VERSION ""

NS_ :

BS_:

BU_: BCM DMS NAB NDG NQS NVO SGW

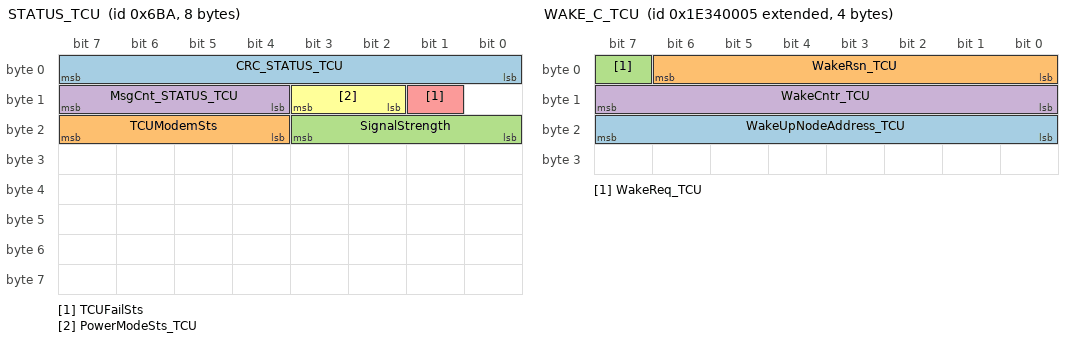
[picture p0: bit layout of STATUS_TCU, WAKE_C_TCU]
BO_ 1722 STATUS_TCU: 8 SGW
 SG_ CRC_STATUS_TCU : 7|8@0+ (1,0) [0|255] "" Vector__XXX
 SG_ TCUModemSts : 23|4@0+ (1,0) [0|15] "" Vector__XXX
 SG_ SignalStrength : 19|4@0+ (1,0) [0|15] "" Vector__XXX
 SG_ MsgCnt_STATUS_TCU : 15|4@0+ (1,0) [0|14] "" Vector__XXX
 SG_ TCUFailSts : 9|1@0+ (1,0) [0|1] "" Vector__XXX
 SG_ PowerModeSts_TCU : 11|2@0+ (1,0) [0|3] ""  BCM

BO_ 2654208005 WAKE_C_TCU: 4 SGW
 SG_ WakeUpNodeAddress_TCU : 23|8@0+ (1,0) [0|255] ""  BCM
 SG_ WakeRsn_TCU : 6|7@0+ (1,0) [0|127] ""  BCM
 SG_ WakeReq_TCU : 7|1@0+ (1,0) [0|1] ""  BCM
 SG_ WakeCntr_TCU : 15|8@0+ (1,0) [0|255] ""  BCM

BO_ 1212 COMMAND_SGW_TO_NBC: 8 SGW
 SG_ TCU_Replacement_Warning : 23|1@0+ (1,0) [0|1] ""  BCM

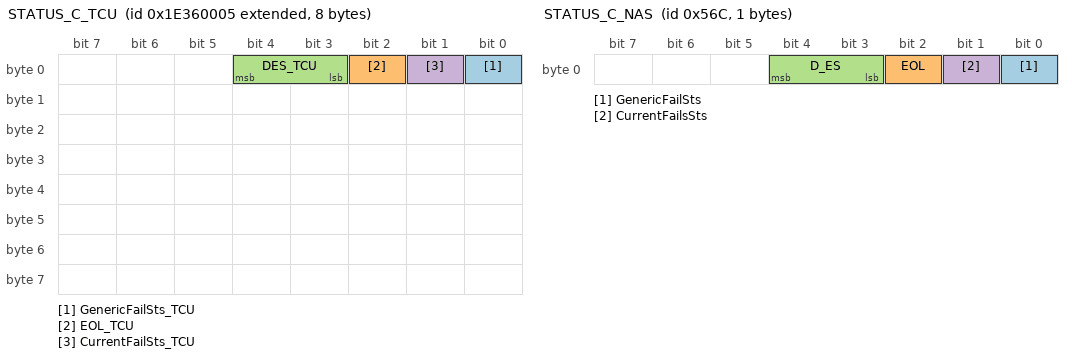
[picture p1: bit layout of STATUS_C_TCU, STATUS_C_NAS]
BO_ 2654339077 STATUS_C_TCU: 8 SGW
 SG_ GenericFailSts_TCU : 0|1@0+ (1,0) [0|1] ""  BCM
 SG_ EOL_TCU : 2|1@0+ (1,0) [0|1] ""  BCM
 SG_ DES_TCU : 4|2@0+ (1,0) [0|3] ""  BCM
 SG_ CurrentFailSts_TCU : 1|1@0+ (1,0) [0|1] ""  BCM

BO_ 2564453105 UDS_DIAG_REQ_ELR: 8 SGW
 SG_ TPDU_DREQ_ELR : 7|64@0+ (1,0) [0|1.84467440737096E+019] ""  BCM

BO_ 2564453361 UDS_DIAG_REQ_ELL: 8 SGW
 SG_ TPDU_DREQ_ELL : 7|64@0+ (1,0) [0|1.84467440737096E+019] ""  BCM

BO_ 204 LWS_STEERING_ANGLE_SENSOR: 6 SGW
 SG_ LWS_OK : 8|1@0+ (1,0) [0|1] ""  BCM
 SG_ LWS_Angle : 31|16@0- (0.1,0) [-780|780] "°"  BCM,NDG

BO_ 1388 STATUS_C_NAS: 1 SGW
 SG_ GenericFailSts : 0|1@0+ (1,0) [0|1] ""  BCM
 SG_ EOL : 2|1@0+ (1,0) [0|1] ""  BCM
 SG_ D_ES : 4|2@0+ (1,0) [0|3] ""  BCM
 SG_ CurrentFailsSts : 1|1@0+ (1,0) [0|1] ""  BCM

BO_ 1530 STATUS_C_LCU: 8 SGW
 SG_ Right_TI_Feedback_C_LCU : 27|1@0+ (1,0) [0|1] ""  BCM
 SG_ Right_TI_FailSts_C_LCU : 25|1@0+ (1,0) [0|1] ""  BCM
 SG_ Right_PL_Feedback_C_LCU : 14|1@0+ (1,0) [0|1] ""  BCM,NQS
 SG_ Right_LB_Feedback_C_LCU : 23|1@0+ (1,0) [0|1] ""  BCM
 SG_ Right_HB_Feedback_C_LCU : 31|1@0+ (1,0) [0|1] ""  BCM
 SG_ Right_DRL_Feedback_C_LCU : 12|1@0+ (1,0) [0|1] ""  BCM,NQS
 SG_ ParkingLight_Feedback_C_LCU : 38|1@0+ (1,0) [0|1] ""  BCM
 SG_ MsgCounter_LCUSts : 51|4@0+ (1,0) [0|15] ""  BCM,NQS
 SG_ Left_TI_Feedback_C_LCU : 28|1@0+ (1,0) [0|1] ""  BCM
 SG_ Left_TI_FailSts_C_LCU : 26|1@0+ (1,0) [0|1] ""  BCM
 SG_ Left_PL_Feedback_C_LCU : 15|1@0+ (1,0) [0|1] ""  BCM,NQS
 SG_ Left_LB_Feedback_C_LCU : 8|1@0+ (1,0) [0|1] ""  BCM
 SG_ Left_HB_Feedback_C_LCU : 16|1@0+ (1,0) [0|1] ""  BCM
 SG_ Left_DRL_Feedback_C_LCU : 13|1@0+ (1,0) [0|1] ""  BCM,NQS
 SG_ GenericFailSts_C_LCU : 0|1@0+ (1,0) [0|1] ""  BCM
 SG_ EOL_C_LCU : 2|1@0+ (1,0) [0|1] ""  BCM
 SG_ D_ES_C_LCU : 4|2@0+ (1,0) [0|3] ""  BCM
 SG_ CurrentFailsSts_C_LCU : 1|1@0+ (1,0) [0|1] ""  BCM
 SG_ Checksum_LCUSts : 63|8@0+ (1,0) [0|255] ""  BCM,NQS

BO_ 2564485490 UDS_DIAG_RES_ELR: 8 BCM
 SG_ TPDU_DRES_ELR : 7|64@0+ (1,0) [0|1.84467440737096E+019] ""  SGW

BO_ 2564485491 UDS_DIAG_RES_ELL: 8 BCM
 SG_ TPDU_DRES_ELL : 7|64@0+ (1,0) [0|1.84467440737096E+019] ""  SGW

BO_ 2041 DIAGNOSTIC_RESPONSE_BCM_MTP_TST: 8 BCM
 SG_ N_PDU_MTP_TST_RESP : 7|64@0+ (1,0) [0|0] ""  SGW

BO_ 2040 DIAGNOSTIC_RESPONSE_BCM_MTP: 8 BCM
 SG_ N_PDU_MTP_RESP : 7|64@0+ (1,0) [0|0] ""  SGW

BO_ 2033 DIAGNOSTIC_REQUEST_BCM_MTP_TST: 8 SGW
 SG_ N_PDU_MTP_TST_REQ : 7|64@0+ (1,0) [0|0] ""  BCM

BO_ 2032 DIAGNOSTIC_REQUEST_BCM_MTP: 8 SGW
 SG_ N_PDU_MTP_REQ : 7|64@0+ (1,0) [0|0] ""  BCM

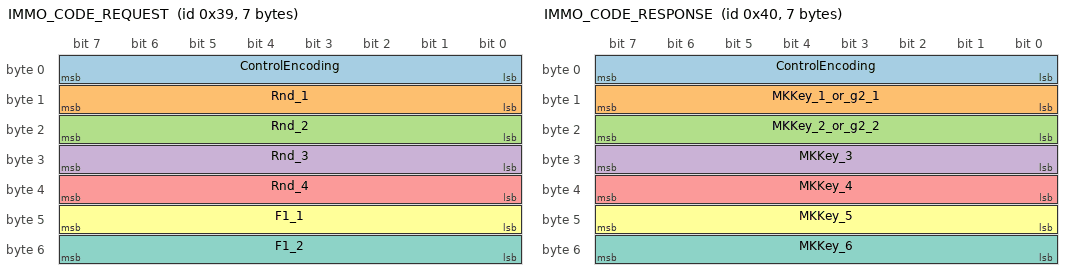
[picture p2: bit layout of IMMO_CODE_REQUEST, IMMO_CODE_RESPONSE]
BO_ 57 IMMO_CODE_REQUEST: 7 SGW
 SG_ ControlEncoding : 7|8@0+ (1,0) [0|255] ""  BCM
 SG_ Rnd_1 : 15|8@0+ (1,0) [0|255] ""  BCM
 SG_ Rnd_2 : 23|8@0+ (1,0) [0|255] ""  BCM
 SG_ Rnd_3 : 31|8@0+ (1,0) [0|255] ""  BCM
 SG_ Rnd_4 : 39|8@0+ (1,0) [0|255] ""  BCM
 SG_ F1_1 : 47|8@0+ (1,0) [0|255] ""  BCM
 SG_ F1_2 : 55|8@0+ (1,0) [0|255] ""  BCM

BO_ 64 IMMO_CODE_RESPONSE: 7 BCM
 SG_ ControlEncoding : 7|8@0+ (1,0) [0|255] ""  SGW
 SG_ MKKey_1_or_g2_1 : 15|8@0+ (1,0) [0|255] ""  SGW
 SG_ MKKey_2_or_g2_2 : 23|8@0+ (1,0) [0|255] ""  SGW
 SG_ MKKey_3 : 31|8@0+ (1,0) [0|255] ""  SGW
 SG_ MKKey_4 : 39|8@0+ (1,0) [0|255] ""  SGW
 SG_ MKKey_5 : 47|8@0+ (1,0) [0|255] ""  SGW
 SG_ MKKey_6 : 55|8@0+ (1,0) [0|255] ""  SGW

BO_ 70 C1_ASR0: 8 SGW
 SG_ ABSSts : 3|3@0+ (1,0) [0|7] ""  BCM,NAB
 SG_ BrkRecSts : 6|3@0+ (1,0) [0|7] "0" Vector__XXX
 SG_ HDCSts : 10|3@0+ (1,0) [0|7] ""  NQS,NVO
 SG_ EBDSts : 15|3@0+ (1,0) [0|7] "" Vector__XXX
 SG_ ACC_Engine_Torque_Enabled_NFR : 16|1@0+ (1,0) [0|1] "" Vector__XXX
 SG_ TrqIncrease_Enabler_TCS : 17|1@0+ (1,0) [0|1] "" Vector__XXX
 SG_ AVHSts : 20|3@0+ (1,0) [0|7] "" Vector__XXX
 SG_ CDPSts : 23|3@0+ (1,0) [0|7] "" Vector__XXX
 SG_ FrontCtrlSts : 25|3@0+ (1,0) [0|7] "" Vector__XXX
 SG_ RearCtrlSts : 28|3@0+ (1,0) [0|7] "" Vector__XXX
 SG_ CommandedSilenceRequest : 29|1@0+ (1,0) [0|1] "" Vector__XXX
 SG_ ACCEngaged : 30|1@0+ (1,0) [0|1] "" Vector__XXX
 SG_ DsblFuelShutOff_ACC_NFR : 31|1@0+ (1,0) [0|1] "" Vector__XXX
 SG_ HDC_TargetSpeed : 38|7@0+ (1,0) [0|120] ""  NQS
 SG_ ACC_TorqueRequest_NFR : 47|12@0+ (8,-8000) [-8000|24760] "Nm" Vector__XXX
 SG_ MessageCounterP_ASR0 : 51|4@0+ (1,0) [0|15] "" Vector__XXX
 SG_ ChecksumP_ASR0 : 63|8@0+ (1,0) [0|255] "" Vector__XXX

BO_ 76 NCR_INFO: 8 SGW
 SG_ GearEngagedForADAS : 7|4@0+ (1,0) [0|15] ""  DMS
 SG_ ActiveGearRatio : 9|10@0+ (0.025,0) [0|25.575] "" Vector__XXX
 SG_ NCRACCFailSts : 10|1@0+ (1,0) [0|1] "" Vector__XXX
 SG_ ActiveGearRatioValidData : 11|1@0+ (1,0) [0|1] "" Vector__XXX
 SG_ GearBoxAutomaticMode : 12|1@0+ (1,0) [0|1] "" Vector__XXX
 SG_ DrivingCycle : 13|1@0+ (1,0) [0|1] "" Vector__XXX
 SG_ WarmingUpCycle : 14|1@0+ (1,0) [0|1] "" Vector__XXX
 SG_ GearEngaged : 27|4@0+ (1,0) [0|15] ""  BCM
 SG_ FutureSyncGear : 31|4@0+ (1,0) [0|15] "" Vector__XXX
 SG_ AMTIndex : 38|7@0+ (1,0) [0|100] "" Vector__XXX
 SG_ ShiftInProgress : 39|1@0+ (1,0) [0|1] "" Vector__XXX
 SG_ DCTState : 45|6@0+ (1,0) [0|63] "" Vector__XXX
 SG_ EngineSlaveMode : 46|1@0+ (1,0) [0|1] "" Vector__XXX
 SG_ RaceStart : 47|1@0+ (1,0) [0|1] "" Vector__XXX
 SG_ MessageCounterP_NCR_INFO : 51|4@0+ (1,0) [0|15] ""  DMS
 SG_ TorquePhaseTime : 55|4@0+ (50,0) [0|750] "msec" Vector__XXX
 SG_ ChecksumP_NCR_INFO : 63|8@0+ (1,0) [0|255] ""  DMS

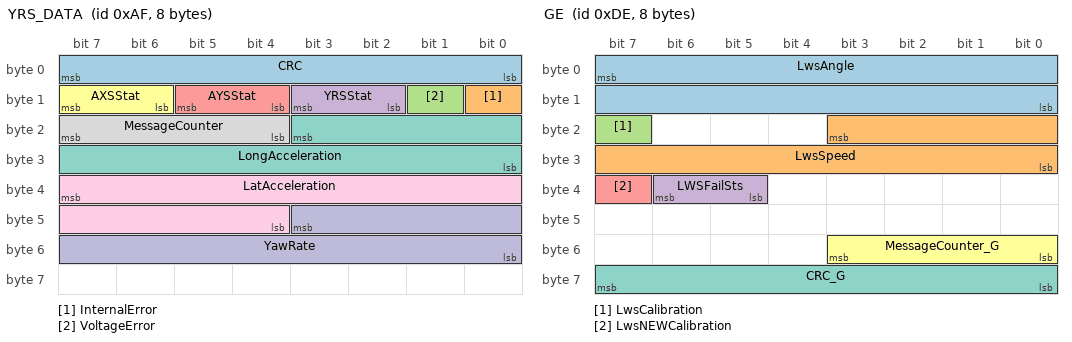
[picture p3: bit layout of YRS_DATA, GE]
BO_ 175 YRS_DATA: 8 SGW
 SG_ CRC : 7|8@0+ (1,0) [0|255] ""  BCM,NAB
 SG_ InternalError : 8|1@0+ (1,0) [0|1] "" Vector__XXX
 SG_ VoltageError : 9|1@0+ (1,0) [0|1] "" Vector__XXX
 SG_ YRSStat : 11|2@0+ (1,0) [0|3] ""  BCM
 SG_ AYSStat : 13|2@0+ (1,0) [0|3] ""  BCM,NQS
 SG_ AXSStat : 15|2@0+ (1,0) [0|3] ""  BCM,NQS
 SG_ LongAcceleration : 19|12@0+ (0.02,-40.96) [-40.96|40.92] "m/s²"  BCM,NDG,NQS
 SG_ MessageCounter : 23|4@0+ (1,0) [0|15] ""  BCM,NAB
 SG_ LatAcceleration : 39|12@0+ (0.02,-40.96) [-40.96|40.92] "m/s²"  BCM,NDG,NQS
 SG_ YawRate : 43|12@0+ (0.08,-163.84) [-163.84|163.68] "°/s"  BCM,NAB,NDG

BO_ 222 GE: 8 SGW
 SG_ LwsAngle : 7|16@0+ (0.1,-720) [-720|720] "°"  BCM,NAB,NDG
 SG_ LwsSpeed : 19|12@0+ (1,-2000) [-2000|2094] "°/S" Vector__XXX
 SG_ LwsCalibration : 23|1@0+ (1,0) [0|1] ""  BCM
 SG_ LWSFailSts : 38|2@0+ (1,0) [0|3] ""  BCM,NAB,NQS
 SG_ LwsNEWCalibration : 39|1@0+ (1,0) [0|1] "" Vector__XXX
 SG_ MessageCounter_G : 51|4@0+ (1,0) [0|15] "" Vector__XXX
 SG_ CRC_G : 63|8@0+ (1,0) [0|255] "" Vector__XXX

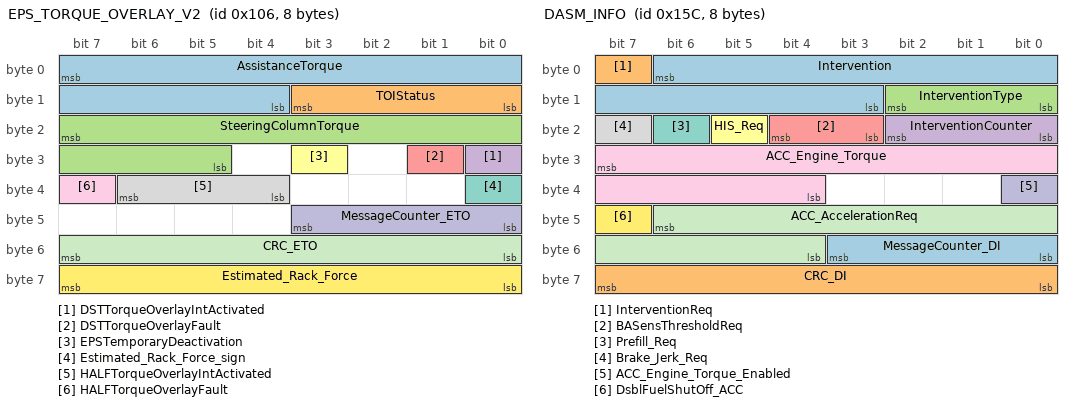
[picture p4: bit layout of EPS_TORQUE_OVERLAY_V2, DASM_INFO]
BO_ 262 EPS_TORQUE_OVERLAY_V2: 8 SGW
 SG_ AssistanceTorque : 7|12@0+ (0.05,-100) [-100|104.75] "Nm" Vector__XXX
 SG_ TOIStatus : 11|4@0+ (1,0) [0|15] "" Vector__XXX
 SG_ SteeringColumnTorque : 23|11@0+ (0.0078125,-8) [-8|7.984375] "Nm" Vector__XXX
 SG_ DSTTorqueOverlayIntActivated : 24|1@0+ (1,0) [0|1] "" Vector__XXX
 SG_ DSTTorqueOverlayFault : 25|1@0+ (1,0) [0|1] "" Vector__XXX
 SG_ EPSTemporaryDeactivation : 27|1@0+ (1,0) [0|1] "" Vector__XXX
 SG_ Estimated_Rack_Force_sign : 32|1@0+ (1,0) [0|1] "" Vector__XXX
 SG_ HALFTorqueOverlayIntActivated : 38|3@0+ (1,0) [0|7] ""  NAB
 SG_ HALFTorqueOverlayFault : 39|1@0+ (1,0) [0|1] ""  NAB
 SG_ MessageCounter_ETO : 43|4@0+ (1,0) [0|15] "" Vector__XXX
 SG_ CRC_ETO : 55|8@0+ (1,0) [0|255] "" Vector__XXX
 SG_ Estimated_Rack_Force : 63|8@0+ (80,0) [0|20400] "N" Vector__XXX

BO_ 326 BRAKE_FE3: 8 BCM
 SG_ Slope : 0|7@0+ (1,-61) [-61|61] "%" Vector__XXX
 SG_ EPBMalfunction : 1|1@0+ (1,0) [0|1] "" Vector__XXX
 SG_ SlopeValidData : 2|1@0+ (1,0) [0|1] "" Vector__XXX
 SG_ Function2Sts : 3|1@0+ (1,0) [0|1] "" Vector__XXX
 SG_ FunctionSts : 4|1@0+ (1,0) [0|1] "" Vector__XXX
 SG_ EPBSts : 7|3@0+ (1,0) [0|7] "" Vector__XXX
 SG_ EPB_ButtonSts : 9|2@0+ (1,0) [0|3] "" Vector__XXX
 SG_ VehicleSpeedVSOSig : 22|13@0+ (0.0625,0) [0|511.9375] "km/h" Vector__XXX
 SG_ AutoDriveOffFailSts : 23|1@0+ (1,0) [0|1] "" Vector__XXX
 SG_ VehicleSpeedVSOSigFailSts : 25|1@0+ (1,0) [0|1] "" Vector__XXX
 SG_ NFR_Speed_FA : 38|13@0+ (0.0625,0) [0|511.9375] "km/h" Vector__XXX
 SG_ ESCOFF_Mode : 39|1@0+ (1,0) [0|1] "" Vector__XXX
 SG_ ABSFailPresent : 40|1@0+ (1,0) [0|1] "" Vector__XXX
 SG_ NFR_Speed_FA_FailSts : 41|1@0+ (1,0) [0|1] "" Vector__XXX
 SG_ MsgCounter : 51|4@0+ (1,0) [0|15] "" Vector__XXX
 SG_ NFRAutoStopFailSts : 52|1@0+ (1,0) [0|1] "" Vector__XXX
 SG_ NFRAutoStopStaySts : 53|1@0+ (1,0) [0|1] "" Vector__XXX
 SG_ NFRAutoStopEnableSts : 54|1@0+ (1,0) [0|1] "" Vector__XXX
 SG_ NFRCruiseEnabler : 55|1@0+ (1,0) [0|1] "" Vector__XXX
 SG_ Checksum : 63|8@0+ (1,0) [0|255] "" Vector__XXX

BO_ 348 DASM_INFO: 8 SGW
 SG_ Intervention : 6|12@0+ (0.01,-16) [-16|4.46] "m/s2" Vector__XXX
 SG_ InterventionReq : 7|1@0+ (1,0) [0|1] ""  NAB,NQS
 SG_ InterventionType : 10|3@0+ (1,0) [0|7] "" Vector__XXX
 SG_ InterventionCounter : 18|3@0+ (1,0) [0|7] "" Vector__XXX
 SG_ BASensThresholdReq : 20|2@0+ (1,0) [0|3] "" Vector__XXX
 SG_ HIS_Req : 21|1@0+ (1,0) [0|1] "" Vector__XXX
 SG_ Prefill_Req : 22|1@0+ (1,0) [0|1] "" Vector__XXX
 SG_ Brake_Jerk_Req : 23|1@0+ (1,0) [0|1] "" Vector__XXX
 SG_ ACC_Engine_Torque : 31|12@0+ (8,-8000) [-8000|24760] "Nm"  NQS
 SG_ ACC_Engine_Torque_Enabled : 32|1@0+ (1,0) [0|1] ""  NQS
 SG_ ACC_AccelerationReq : 46|11@0+ (0.01,-16) [-16|4.46] "m/s2" Vector__XXX
 SG_ DsblFuelShutOff_ACC : 47|1@0+ (1,0) [0|1] "" Vector__XXX
 SG_ MessageCounter_DI : 51|4@0+ (1,0) [0|15] "" Vector__XXX
 SG_ CRC_DI : 63|8@0+ (1,0) [0|255] "" Vector__XXX

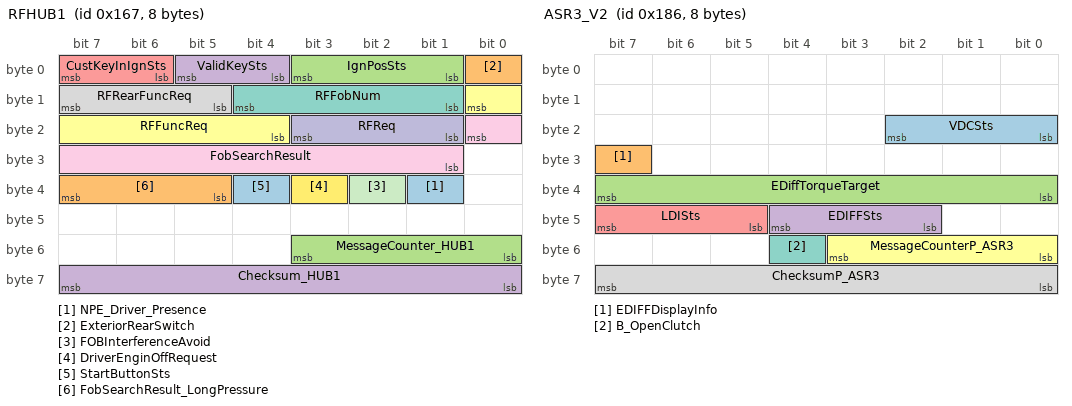
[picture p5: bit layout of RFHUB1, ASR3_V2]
BO_ 359 RFHUB1: 8 BCM
 SG_ NPE_Driver_Presence : 33|1@0+ (1,0) [0|1] ""  SGW
 SG_ ExteriorRearSwitch : 0|1@0+ (1,0) [0|1] ""  SGW
 SG_ IgnPosSts : 3|3@0+ (1,0) [0|7] ""  SGW
 SG_ ValidKeySts : 5|2@0+ (1,0) [0|3] ""  SGW
 SG_ CustKeyInIgnSts : 7|2@0+ (1,0) [0|3] ""  SGW
 SG_ RFFuncReq : 8|5@0+ (1,0) [0|31] ""  SGW
 SG_ RFFobNum : 12|4@0+ (1,0) [0|15] ""  SGW
 SG_ RFRearFuncReq : 15|3@0+ (1,0) [0|7] ""  SGW
 SG_ FobSearchResult : 16|8@0+ (1,0) [0|255] ""  SGW
 SG_ RFReq : 19|3@0+ (1,0) [0|7] ""  SGW
 SG_ FOBInterferenceAvoid : 34|1@0+ (1,0) [0|1] "raw"  NQS,SGW
 SG_ DriverEnginOffRequest : 35|1@0+ (1,0) [0|1] ""  SGW
 SG_ StartButtonSts : 36|1@0+ (1,0) [0|1] ""  SGW
 SG_ FobSearchResult_LongPressure : 39|3@0+ (1,0) [0|7] ""  SGW
 SG_ MessageCounter_HUB1 : 51|4@0+ (1,0) [0|15] ""  SGW
 SG_ Checksum_HUB1 : 63|8@0+ (1,0) [0|255] ""  SGW

BO_ 390 ASR3_V2: 8 SGW
 SG_ VDCSts : 18|3@0+ (1,0) [0|7] ""  NAB
 SG_ EDIFFDisplayInfo : 31|1@0+ (1,0) [0|1] "" Vector__XXX
 SG_ EDiffTorqueTarget : 39|8@0+ (10,0) [0|2550] "Nm" Vector__XXX
 SG_ EDIFFSts : 44|3@0+ (1,0) [0|7] "" Vector__XXX
 SG_ LDISts : 47|3@0+ (1,0) [0|7] "" Vector__XXX
 SG_ MessageCounterP_ASR3 : 51|4@0+ (1,0) [0|15] "" Vector__XXX
 SG_ B_OpenClutch : 52|1@0+ (1,0) [0|1] "" Vector__XXX
 SG_ ChecksumP_ASR3 : 63|8@0+ (1,0) [0|255] "" Vector__XXX

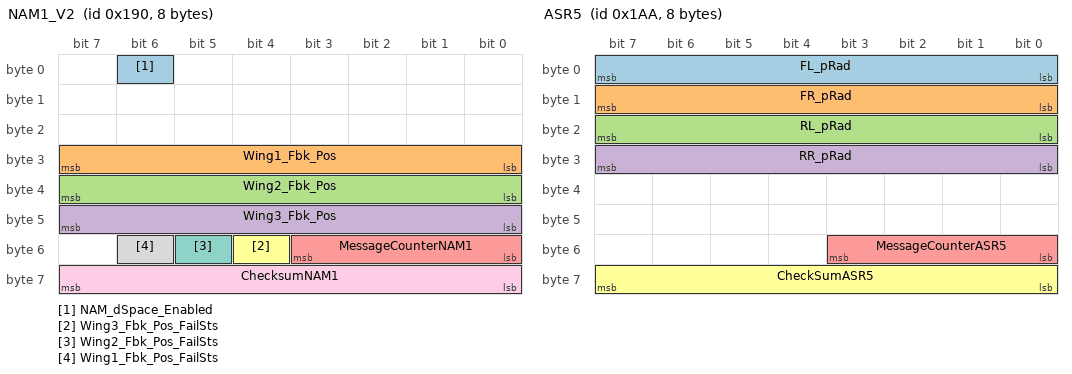
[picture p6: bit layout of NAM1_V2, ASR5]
BO_ 400 NAM1_V2: 8 SGW
 SG_ NAM_dSpace_Enabled : 6|1@0+ (1,0) [0|1] "" Vector__XXX
 SG_ Wing1_Fbk_Pos : 31|8@0+ (0.5,0) [0|100] "%"  BCM
 SG_ Wing2_Fbk_Pos : 39|8@0+ (0.5,0) [0|100] "%"  BCM
 SG_ Wing3_Fbk_Pos : 47|8@0+ (0.5,0) [0|100] "%"  BCM
 SG_ MessageCounterNAM1 : 51|4@0+ (1,0) [0|15] ""  BCM
 SG_ Wing3_Fbk_Pos_FailSts : 52|1@0+ (1,0) [0|1] "" Vector__XXX
 SG_ Wing2_Fbk_Pos_FailSts : 53|1@0+ (1,0) [0|1] "" Vector__XXX
 SG_ Wing1_Fbk_Pos_FailSts : 54|1@0+ (1,0) [0|1] "" Vector__XXX
 SG_ ChecksumNAM1 : 63|8@0+ (1,0) [0|255] ""  BCM

BO_ 426 ASR5: 8 SGW
 SG_ FL_pRad : 7|8@0+ (0.8,0) [0|200] "bar"  NQS
 SG_ FR_pRad : 15|8@0+ (0.8,0) [0|200] "bar"  NQS
 SG_ RL_pRad : 23|8@0+ (0.8,0) [0|200] "bar"  NQS
 SG_ RR_pRad : 31|8@0+ (0.8,0) [0|200] "bar"  NQS
 SG_ MessageCounterASR5 : 51|4@0+ (1,0) [0|15] "" Vector__XXX
 SG_ CheckSumASR5 : 63|8@0+ (1,0) [0|255] "" Vector__XXX

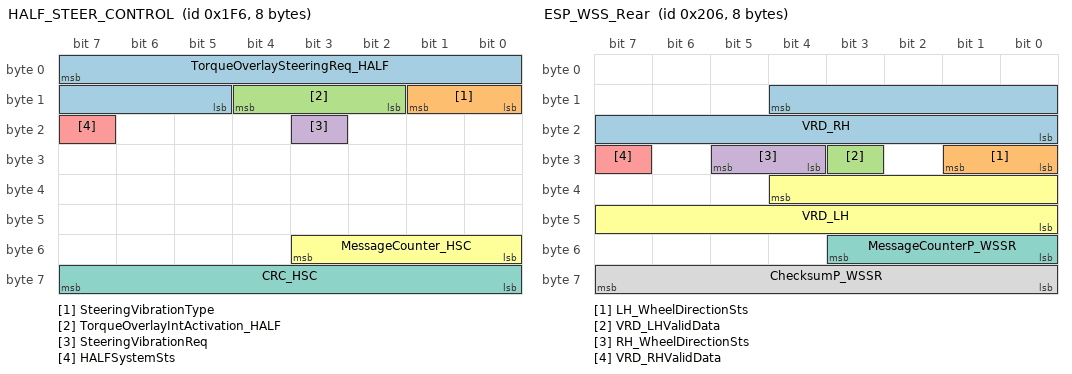
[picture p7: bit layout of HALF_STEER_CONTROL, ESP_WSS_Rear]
BO_ 502 HALF_STEER_CONTROL: 8 SGW
 SG_ TorqueOverlaySteeringReq_HALF : 7|11@0+ (0.00195312,-2) [-2|1.99803664] "Nm" Vector__XXX
 SG_ SteeringVibrationType : 9|2@0+ (1,0) [0|3] "" Vector__XXX
 SG_ TorqueOverlayIntActivation_HALF : 12|3@0+ (1,0) [0|7] "" Vector__XXX
 SG_ SteeringVibrationReq : 19|1@0+ (1,0) [0|1] "" Vector__XXX
 SG_ HALFSystemSts : 23|1@0+ (1,0) [0|1] ""  NAB
 SG_ MessageCounter_HSC : 51|4@0+ (1,0) [0|15] "" Vector__XXX
 SG_ CRC_HSC : 63|8@0+ (1,0) [0|255] "" Vector__XXX

BO_ 518 ESP_WSS_Rear: 8 SGW
 SG_ VRD_RH : 12|13@0+ (0.0625,0) [0.5|511.9375] "km/h"  BCM,NQS
 SG_ LH_WheelDirectionSts : 25|2@0+ (1,0) [0|3] ""  BCM
 SG_ VRD_LHValidData : 27|1@0+ (1,0) [0|1] ""  BCM,NQS
 SG_ RH_WheelDirectionSts : 29|2@0+ (1,0) [0|3] ""  BCM
 SG_ VRD_RHValidData : 31|1@0+ (1,0) [0|1] ""  BCM,NQS
 SG_ VRD_LH : 36|13@0+ (0.0625,0) [0.5|511.9375] "km/h"  BCM,NQS
 SG_ MessageCounterP_WSSR : 51|4@0+ (1,0) [0|15] ""  BCM,NQS
 SG_ ChecksumP_WSSR : 63|8@0+ (1,0) [0|255] ""  BCM,NQS

BO_ 524 NFR_SPEED: 8 SGW
 SG_ Slope : 0|7@0+ (1,-61) [-61|61] "%"  BCM
 SG_ EPBMalfunction : 1|1@0+ (1,0) [0|1] ""  BCM,NAB
 SG_ SlopeValidData : 2|1@0+ (1,0) [0|1] ""  BCM
 SG_ Function2Sts : 3|1@0+ (1,0) [0|1] ""  BCM
 SG_ FunctionSts : 4|1@0+ (1,0) [0|1] ""  BCM
 SG_ EPBSts : 7|3@0+ (1,0) [0|7] ""  BCM,NAB
 SG_ EPB_ButtonSts : 9|2@0+ (1,0) [0|3] ""  BCM
 SG_ VehicleSpeedVSOSig : 22|13@0+ (0.0625,0) [0|511.9375] "km/h"  BCM,DMS,NAB,NDG,NQS,NVO
 SG_ AutoDriveOffFailSts : 23|1@0+ (1,0) [0|1] ""  BCM
 SG_ VehicleSpeedVSOSigFailSts : 25|1@0+ (1,0) [0|1] ""  BCM,DMS,NAB,NDG,NQS,NVO
 SG_ NFR_Speed_FA : 38|13@0+ (0.0625,0) [0|511.9375] "km/h"  BCM,NAB,NQS
 SG_ ESCOFF_Mode : 39|1@0+ (1,0) [0|1] ""  BCM,NAB
 SG_ ABSFailPresent : 40|1@0+ (1,0) [0|1] ""  BCM
 SG_ NFR_Speed_FA_FailSts : 41|1@0+ (1,0) [0|1] ""  BCM,NAB,NQS
 SG_ MsgCounter : 51|4@0+ (1,0) [0|15] ""  BCM,DMS
 SG_ NFRAutoStopFailSts : 52|1@0+ (1,0) [0|1] ""  BCM
 SG_ NFRAutoStopStaySts : 53|1@0+ (1,0) [0|1] ""  BCM
 SG_ NFRAutoStopEnableSts : 54|1@0+ (1,0) [0|1] ""  BCM
 SG_ NFRCruiseEnabler : 55|1@0+ (1,0) [0|1] ""  BCM
 SG_ Checksum : 63|8@0+ (1,0) [0|255] ""  BCM,DMS

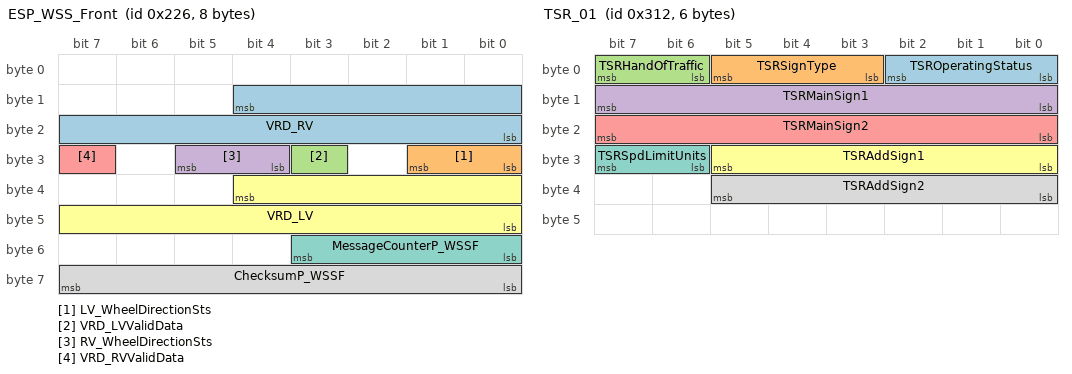
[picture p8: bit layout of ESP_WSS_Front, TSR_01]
BO_ 550 ESP_WSS_Front: 8 SGW
 SG_ VRD_RV : 12|13@0+ (0.0625,0) [0.5|511.9375] "km/h"  BCM,NQS
 SG_ LV_WheelDirectionSts : 25|2@0+ (1,0) [0|3] ""  BCM
 SG_ VRD_LVValidData : 27|1@0+ (1,0) [0|1] ""  BCM,NQS
 SG_ RV_WheelDirectionSts : 29|2@0+ (1,0) [0|3] ""  BCM
 SG_ VRD_RVValidData : 31|1@0+ (1,0) [0|1] ""  BCM,NQS
 SG_ VRD_LV : 36|13@0+ (0.0625,0) [0.5|511.9375] "km/h"  BCM,NQS
 SG_ MessageCounterP_WSSF : 51|4@0+ (1,0) [0|15] ""  BCM,NQS
 SG_ ChecksumP_WSSF : 63|8@0+ (1,0) [0|255] ""  BCM,NQS

BO_ 599 AIRBAG1: 8 NAB
 SG_ AirBagWarningPABLabelSts : 63|1@0+ (1,0) [0|1] ""  BCM,SGW
 SG_ SBR2RowCentralSeatBuckleFailSts : 0|2@0+ (1,0) [0|3] ""  BCM,SGW
 SG_ SBR2RowCentralSeatConfigSts : 1|1@0+ (1,0) [0|1] ""  BCM,SGW
 SG_ AirBagFailSts : 7|2@0+ (1,0) [0|3] ""  BCM,NDG,NQS,SGW
 SG_ SBR1RowDriverSeatFailSts : 8|2@0+ (1,0) [0|3] ""  BCM,SGW
 SG_ SBR1RowDriverSeatConfigSts : 9|1@0+ (1,0) [0|1] ""  BCM,NQS,SGW
 SG_ SBR2RowCentralSeatSts : 12|3@0+ (1,0) [0|7] ""  BCM,SGW
 SG_ SBR1RowCentralSeatPPDFailSts : 14|2@0+ (1,0) [0|3] ""  BCM,SGW
 SG_ SBR1RowPsngrSeatPPDFailSts : 17|2@0+ (1,0) [0|3] ""  BCM,NQS,SGW
 SG_ SBR1RowPsngrSeatBuckleFailSts : 19|2@0+ (1,0) [0|3] ""  BCM,SGW
 SG_ SBR1RowPsngrSeatConfigSts : 20|1@0+ (1,0) [0|1] ""  BCM,NQS,SGW
 SG_ SBR1RowDriverSeatSts : 22|2@0+ (1,0) [0|3] ""  BCM,NQS,SGW
 SG_ SBR2RowLeftSeatSts : 24|2@0+ (1,0) [0|3] ""  BCM,SGW
 SG_ SBR2RowRightSeatFailSts : 26|2@0+ (1,0) [0|3] ""  BCM,SGW
 SG_ SBR2RowLeftSeatFailSts : 28|2@0+ (1,0) [0|3] ""  BCM,SGW
 SG_ SBR1RowPsngrSeatSts : 31|3@0+ (1,0) [0|7] ""  BCM,NQS,SGW
 SG_ CrashOutputSts : 36|8@0+ (1,0) [0|255] ""  BCM,NQS,SGW
 SG_ SBR2RowRightSeatSts : 38|2@0+ (1,0) [0|3] ""  BCM,SGW
 SG_ MessageCounterNAB1 : 43|4@0+ (1,0) [0|15] ""  BCM,SGW
 SG_ CrashOutputValidData : 44|1@0+ (1,0) [0|1] ""  BCM,NQS,SGW
 SG_ ChecksumNAB1 : 55|8@0+ (1,0) [0|255] ""  BCM,SGW
 SG_ AirBagWarningPADLampOnSts : 56|1@0+ (1,0) [0|1] ""  BCM,SGW
 SG_ AirBagWarningPADLampOffSts : 57|1@0+ (1,0) [0|1] ""  BCM,SGW
 SG_ SBR2RowRightSeatConfigSts : 58|1@0+ (1,0) [0|1] ""  BCM,SGW
 SG_ SBR2RowLeftSeatConfigSts : 59|1@0+ (1,0) [0|1] ""  BCM,SGW
 SG_ Ppd_psngr_info : 61|2@0+ (1,0) [0|3] ""  BCM,NQS,SGW
 SG_ AirBagWarningLampSts : 62|1@0+ (1,0) [0|1] ""  BCM,NDG,NQS,SGW

BO_ 786 TSR_01: 6 SGW
 SG_ TSROperatingStatus : 0|3@1+ (1,0) [0|7] ""  NQS
 SG_ TSRSignType : 3|3@1+ (1,0) [0|7] ""  NQS
 SG_ TSRHandOfTraffic : 6|2@1+ (1,0) [0|3] ""  NQS
 SG_ TSRMainSign1 : 8|8@1+ (1,0) [0|255] ""  NQS
 SG_ TSRMainSign2 : 16|8@1+ (1,0) [0|255] ""  NQS
 SG_ TSRAddSign1 : 24|6@1+ (1,0) [0|63] ""  NQS
 SG_ TSRSpdLimitUnits : 30|2@1+ (1,0) [0|3] ""  NQS
 SG_ TSRAddSign2 : 32|6@1+ (1,0) [0|63] ""  NQS

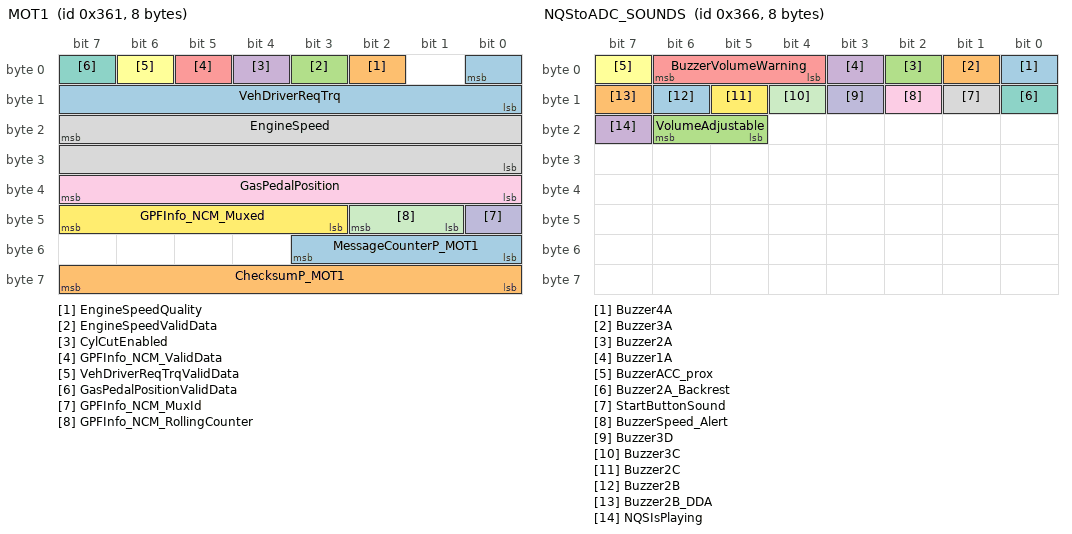
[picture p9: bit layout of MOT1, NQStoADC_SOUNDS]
BO_ 865 MOT1: 8 SGW
 SG_ VehDriverReqTrq : 0|9@0+ (4,-508) [-508|1536] "Nm"  BCM
 SG_ EngineSpeedQuality : 2|1@0+ (1,0) [0|1] ""  BCM
 SG_ EngineSpeedValidData : 3|1@0+ (1,0) [0|1] ""  BCM,NAB,NQS
 SG_ CylCutEnabled : 4|1@0+ (1,0) [0|1] ""  BCM
 SG_ GPFInfo_NCM_ValidData : 5|1@0+ (1,0) [0|1] ""  BCM
 SG_ VehDriverReqTrqValidData : 6|1@0+ (1,0) [0|1] ""  BCM
 SG_ GasPedalPositionValidData : 7|1@0+ (1,0) [0|1] ""  BCM,NDG,NQS
 SG_ EngineSpeed : 23|16@0+ (1,0) [0|10240] "1/min"  BCM,NAB,NQS
 SG_ GasPedalPosition : 39|8@0+ (0.392,0) [0|99.96] "%"  BCM,NDG,NQS
 SG_ GPFInfo_NCM_MuxId : 40|1@0+ (1,0) [0|1] ""  BCM
 SG_ GPFInfo_NCM_RollingCounter : 42|2@0+ (1,0) [0|3] ""  BCM
 SG_ GPFInfo_NCM_Muxed : 47|5@0+ (1,0) [0|31] ""  BCM
 SG_ MessageCounterP_MOT1 : 51|4@0+ (1,0) [0|15] ""  BCM
 SG_ ChecksumP_MOT1 : 63|8@0+ (1,0) [0|255] ""  BCM

BO_ 870 NQStoADC_SOUNDS: 8 NQS
 SG_ Buzzer4A : 0|1@0+ (1,0) [0|1] ""  SGW
 SG_ Buzzer3A : 1|1@0+ (1,0) [0|1] ""  SGW
 SG_ Buzzer2A : 2|1@0+ (1,0) [0|1] ""  SGW
 SG_ Buzzer1A : 3|1@0+ (1,0) [0|1] ""  SGW
 SG_ BuzzerVolumeWarning : 6|3@0+ (1,0) [0|7] ""  SGW
 SG_ BuzzerACC_prox : 7|1@0+ (1,0) [0|1] ""  SGW
 SG_ Buzzer2A_Backrest : 8|1@0+ (1,0) [0|1] ""  SGW
 SG_ StartButtonSound : 9|1@0+ (1,0) [0|1] ""  SGW
 SG_ BuzzerSpeed_Alert : 10|1@0+ (1,0) [0|1] ""  SGW
 SG_ Buzzer3D : 11|1@0+ (1,0) [0|1] ""  SGW
 SG_ Buzzer3C : 12|1@0+ (1,0) [0|1] ""  SGW
 SG_ Buzzer2C : 13|1@0+ (1,0) [0|1] ""  SGW
 SG_ Buzzer2B : 14|1@0+ (1,0) [0|1] ""  SGW
 SG_ Buzzer2B_DDA : 15|1@0+ (1,0) [0|1] ""  SGW
 SG_ VolumeAdjustable : 22|2@0+ (1,0) [0|3] ""  SGW
 SG_ NQSIsPlaying : 23|1@0+ (1,0) [0|1] ""  SGW

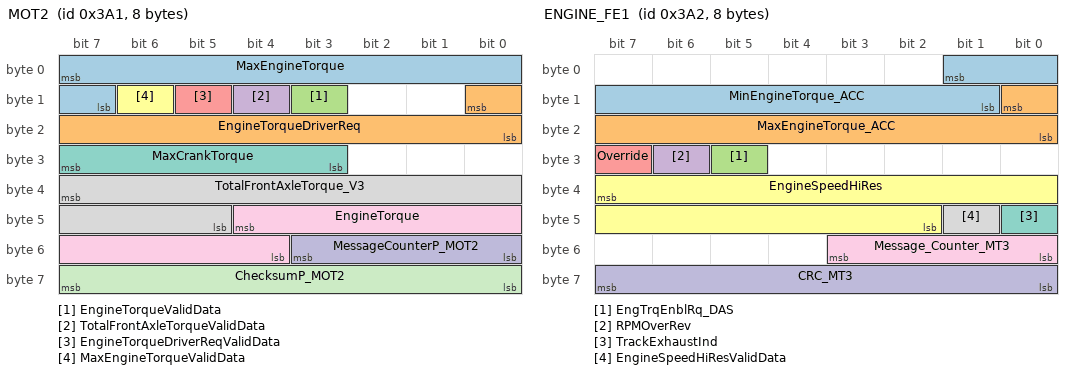
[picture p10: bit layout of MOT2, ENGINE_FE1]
BO_ 929 MOT2: 8 SGW
 SG_ MaxEngineTorque : 7|9@0+ (4,-508) [-508|1536] "Nm" Vector__XXX
 SG_ EngineTorqueDriverReq : 8|9@0+ (4,-508) [-508|1536] "Nm"  NQS
 SG_ EngineTorqueValidData : 11|1@0+ (1,0) [0|1] ""  NQS
 SG_ TotalFrontAxleTorqueValidData : 12|1@0+ (1,0) [0|1] ""  NQS
 SG_ EngineTorqueDriverReqValidData : 13|1@0+ (1,0) [0|1] ""  NQS
 SG_ MaxEngineTorqueValidData : 14|1@0+ (1,0) [0|1] "" Vector__XXX
 SG_ MaxCrankTorque : 31|5@0+ (5,60) [60|215] "Nm" Vector__XXX
 SG_ TotalFrontAxleTorque_V3 : 39|11@0+ (1,-254) [-254|1533] "Nm"  NQS
 SG_ EngineTorque : 44|9@0+ (4,-508) [-508|1536] "Nm"  NQS
 SG_ MessageCounterP_MOT2 : 51|4@0+ (1,0) [0|15] ""  BCM
 SG_ ChecksumP_MOT2 : 63|8@0+ (1,0) [0|255] ""  BCM

BO_ 930 ENGINE_FE1: 8 SGW
 SG_ MinEngineTorque_ACC : 1|9@0+ (4,-508) [-508|1536] "Nm" Vector__XXX
 SG_ MaxEngineTorque_ACC : 8|9@0+ (4,-508) [-508|1536] "Nm" Vector__XXX
 SG_ EngTrqEnblRq_DAS : 29|1@0+ (1,0) [0|1] "" Vector__XXX
 SG_ RPMOverRev : 30|1@0+ (1,0) [0|1] "" Vector__XXX
 SG_ Override : 31|1@0+ (1,0) [0|1] "" Vector__XXX
 SG_ EngineSpeedHiRes : 39|14@0+ (1,0) [0|16383] "rpm"  NQS,NVO
 SG_ TrackExhaustInd : 40|1@0+ (1,0) [0|1] ""  NQS
 SG_ EngineSpeedHiResValidData : 41|1@0+ (1,0) [0|1] ""  NQS,NVO
 SG_ Message_Counter_MT3 : 51|4@0+ (1,0) [0|15] ""  NQS,NVO
 SG_ CRC_MT3 : 63|8@0+ (1,0) [0|255] ""  NQS,NVO

BO_ 980 NVO_INFO: 8 NVO
 SG_ CruiseControlCmdResumeSts : 0|1@0+ (1,0) [0|1] ""  SGW
 SG_ CruiseControlCmdChangeSts : 1|1@0+ (1,0) [0|1] ""  NQS,SGW
 SG_ CruiseControlCmdDecelerationSts : 2|1@0+ (1,0) [0|1] ""  SGW
 SG_ CruiseControlCmdAccelerationSts : 3|1@0+ (1,0) [0|1] ""  SGW
 SG_ HManettinoDriverWishFailSts : 4|1@0+ (1,0) [0|1] ""  SGW
 SG_ HManettinoDriverWish : 7|3@0+ (1,0) [0|7] ""  SGW
 SG_ CruiseControlFailSts : 9|1@0+ (1,0) [0|1] ""  SGW
 SG_ ACC_OnOffSts : 10|1@0+ (1,0) [0|1] ""  NQS,SGW
 SG_ SpeedRockerSts : 13|3@0+ (1,0) [0|7] ""  SGW
 SG_ ACC_DistSts : 14|1@0+ (1,0) [0|1] ""  SGW
 SG_ ResumeSwitch : 15|1@0+ (1,0) [0|1] ""  SGW
 SG_ ManettinoSuspensionSts : 18|3@0+ (1,0) [0|7] ""  SGW
 SG_ ESPChangeModeReqSts : 19|1@0+ (1,0) [0|1] ""  SGW
 SG_ ManettinoFailSts : 20|1@0+ (1,0) [0|1] ""  NDG,NQS,SGW
 SG_ ManettinoSts : 23|3@0+ (1,0) [0|7] ""  NDG,NQS,SGW
 SG_ FrontWindshieldWiperSwitchSts : 26|3@0+ (1,0) [0|7] ""  BCM,SGW
 SG_ SuspensionButtonSts : 27|1@0+ (1,0) [0|1] ""  SGW
 SG_ LdirectionSwitchSts_NVO_INFO : 28|1@0+ (1,0) [0|1] ""  BCM,SGW
 SG_ RdirectionSwitchSts_NVO_INFO : 29|1@0+ (1,0) [0|1] ""  BCM,SGW
 SG_ EfficiencyModeRequest : 31|2@0+ (1,0) [0|3] ""  SGW
 SG_ LChangeLaneSts_NVO_INFO : 35|1@0+ (1,0) [0|1] ""  BCM
 SG_ RChangeLaneSts_NVO_INFO : 36|1@0+ (1,0) [0|1] ""  BCM
 SG_ HDCButtonSts : 37|1@0+ (1,0) [0|1] ""  SGW
 SG_ ADAS_OnOffSts : 38|1@0+ (1,0) [0|1] ""  SGW
 SG_ FrontWindshieldWasherSwitchSts : 39|1@0+ (1,0) [0|1] ""  BCM,SGW
 SG_ MessageCounterP_NVO_INFO : 51|4@0+ (1,0) [0|15] ""  BCM,SGW
 SG_ ChecksumP_NVO_INFO : 63|8@0+ (1,0) [0|255] ""  BCM,SGW

BO_ 988 STATUS_NTP: 8 SGW
 SG_ TyrePressureSystemSts : 0|1@0+ (1,0) [0|1] ""  NAB,NQS
 SG_ TyrePressureSystemFailSts : 1|1@0+ (1,0) [0|1] ""  NAB,NQS
 SG_ TyrePressureSysCalibrationSts : 2|1@0+ (1,0) [0|1] ""  NQS
 SG_ NTPTempNotActiveSts : 3|1@0+ (1,0) [0|1] ""  NQS
 SG_ NTPCalibrationReqACK : 4|1@0+ (1,0) [0|1] ""  NQS
 SG_ IDtyre_temperature : 7|2@0+ (1,0) [0|3] ""  NQS
 SG_ TemperatureSts_xx : 15|8@0+ (1,-40) [-40|125] "°C"  NQS
 SG_ UnknownTyrePressureSts : 17|2@0+ (1,0) [0|3] ""  NQS
 SG_ TPMSTelltaleSts : 23|2@0+ (1,0) [0|3] ""  NQS
 SG_ RHRTyrePressureSts : 25|2@0+ (1,0) [0|3] ""  NQS
 SG_ LHRTyrePressureSts : 27|2@0+ (1,0) [0|3] ""  NQS
 SG_ RHFTyrePressureSts : 29|2@0+ (1,0) [0|3] ""  NQS
 SG_ LHFTyrePressureSts : 31|2@0+ (1,0) [0|3] ""  NQS
 SG_ LHFPressureSts : 39|8@0+ (0.025,0) [0|5.375] "bar"  NQS
 SG_ RHFPressureSts : 47|8@0+ (0.025,0) [0|5.375] "bar"  NQS
 SG_ LHRPressureSts : 55|8@0+ (0.025,0) [0|5.375] "bar"  NQS
 SG_ RHRPressureSts : 63|8@0+ (0.025,0) [0|5.375] "bar"  NQS

BO_ 1023 LCU_COMMAND: 8 BCM
 SG_ HBActivation : 1|2@0+ (1,0) [0|3] ""  SGW
 SG_ LBActivation : 2|1@0+ (1,0) [0|1] ""  SGW
 SG_ ParkingLightCmd : 3|1@0+ (1,0) [0|1] ""  SGW
 SG_ LeftPL : 4|1@0+ (1,0) [0|1] ""  SGW
 SG_ RightPL : 5|1@0+ (1,0) [0|1] ""  SGW
 SG_ LeftDRL : 6|1@0+ (1,0) [0|1] ""  SGW
 SG_ RightDRL : 7|1@0+ (1,0) [0|1] ""  SGW
 SG_ AHB_Memory : 12|1@0+ (1,0) [0|1] "" Vector__XXX
 SG_ FBL_Activation : 13|1@0+ (1,0) [0|1] ""  SGW
 SG_ TrafficChangeEnable : 15|2@0+ (1,0) [0|3] "" Vector__XXX
 SG_ AFSReq : 40|1@0+ (1,0) [0|1] ""  SGW
 SG_ MsgCounter_LCUCmd : 51|4@0+ (1,0) [0|15] ""  SGW
 SG_ FrontWindshieldWiperSts : 52|1@0+ (1,0) [0|1] ""  SGW
 SG_ FrontWindshieldWasherSts : 53|1@0+ (1,0) [0|1] ""  SGW
 SG_ AHBFeature : 54|1@0+ (1,0) [0|1] ""  SGW
 SG_ AHB_ON : 55|1@0+ (1,0) [0|1] "" Vector__XXX
 SG_ Checksum_LCUCmd : 63|8@0+ (1,0) [0|255] ""  SGW

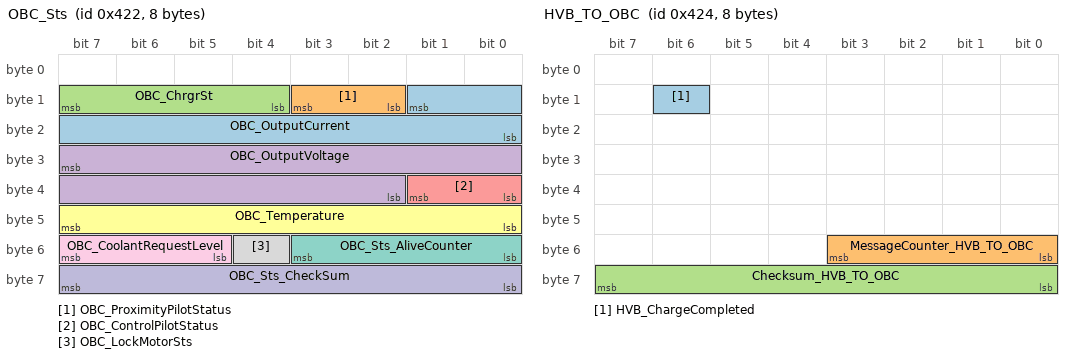
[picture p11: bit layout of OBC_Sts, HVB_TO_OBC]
BO_ 1058 OBC_Sts: 8 SGW
 SG_ OBC_OutputCurrent : 9|10@0+ (0.1,0) [0|25] "A" Vector__XXX
 SG_ OBC_ProximityPilotStatus : 11|2@0+ (1,0) [0|3] "" Vector__XXX
 SG_ OBC_ChrgrSt : 15|4@0+ (1,0) [0|15] ""  NDG,NQS
 SG_ OBC_OutputVoltage : 31|14@0+ (0.1,0) [0|512] "V" Vector__XXX
 SG_ OBC_ControlPilotStatus : 33|2@0+ (1,0) [0|3] "" Vector__XXX
 SG_ OBC_Temperature : 47|8@0+ (1,-40) [-40|215] "°C" Vector__XXX
 SG_ OBC_Sts_AliveCounter : 51|4@0+ (1,0) [0|15] ""  NQS
 SG_ OBC_LockMotorSts : 52|1@0+ (1,0) [0|1] "" Vector__XXX
 SG_ OBC_CoolantRequestLevel : 55|3@0+ (1,0) [0|7] "" Vector__XXX
 SG_ OBC_Sts_CheckSum : 63|8@0+ (1,0) [0|255] ""  NQS

BO_ 1060 HVB_TO_OBC: 8 SGW
 SG_ HVB_ChargeCompleted : 14|1@0+ (1,0) [0|1] ""  NQS
 SG_ MessageCounter_HVB_TO_OBC : 51|4@0+ (1,0) [0|15] ""  NQS
 SG_ Checksum_HVB_TO_OBC : 63|8@0+ (1,0) [0|255] ""  NQS

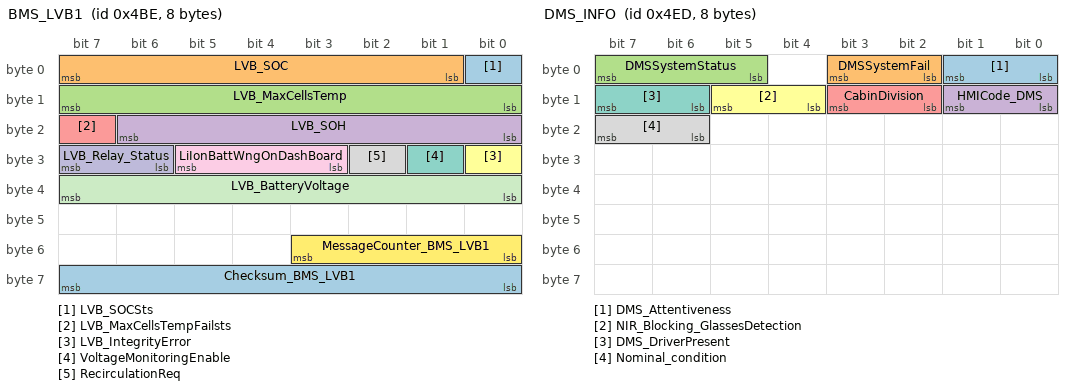
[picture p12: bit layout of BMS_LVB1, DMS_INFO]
BO_ 1214 BMS_LVB1: 8 SGW
 SG_ LVB_SOCSts : 0|1@0+ (1,0) [0|1] ""  BCM,NDG,NQS
 SG_ LVB_SOC : 7|7@0+ (1,0) [0|100] "%"  BCM,NDG,NQS
 SG_ LVB_MaxCellsTemp : 15|8@0+ (1,-45) [-45|170] "°C"  BCM
 SG_ LVB_SOH : 22|7@0+ (1,0) [0|100] "%"  BCM,NDG
 SG_ LVB_MaxCellsTempFailsts : 23|1@0+ (1,0) [0|1] ""  BCM
 SG_ LVB_IntegrityError : 24|1@0+ (1,0) [0|1] ""  BCM
 SG_ VoltageMonitoringEnable : 25|1@0+ (1,0) [0|1] ""  BCM
 SG_ RecirculationReq : 26|1@0+ (1,0) [0|1] ""  BCM
 SG_ LiIonBattWngOnDashBoard : 29|3@0+ (1,0) [0|7] ""  BCM
 SG_ LVB_Relay_Status : 31|2@0+ (1,0) [0|3] ""  BCM
 SG_ LVB_BatteryVoltage : 39|8@0+ (0.078,0) [0|19.89] "V"  BCM
 SG_ MessageCounter_BMS_LVB1 : 51|4@0+ (1,0) [0|15] ""  BCM,NQS
 SG_ Checksum_BMS_LVB1 : 63|8@0+ (1,0) [0|255] ""  BCM,NQS

BO_ 1261 DMS_INFO: 8 DMS
 SG_ DMS_Attentiveness : 1|2@0+ (1,0) [0|3] ""  SGW
 SG_ DMSSystemFail : 3|2@0+ (1,0) [0|3] ""  NQS,SGW
 SG_ DMSSystemStatus : 7|3@0+ (1,0) [0|7] ""  NQS,SGW
 SG_ HMICode_DMS : 9|2@0+ (1,0) [0|3] ""  NQS,SGW
 SG_ CabinDivision : 11|2@0+ (1,0) [0|3] ""  SGW
 SG_ NIR_Blocking_GlassesDetection : 13|2@0+ (1,0) [0|3] ""  SGW
 SG_ DMS_DriverPresent : 15|2@0+ (1,0) [0|3] ""  SGW
 SG_ Nominal_condition : 23|2@0+ (1,0) [0|3] ""  SGW

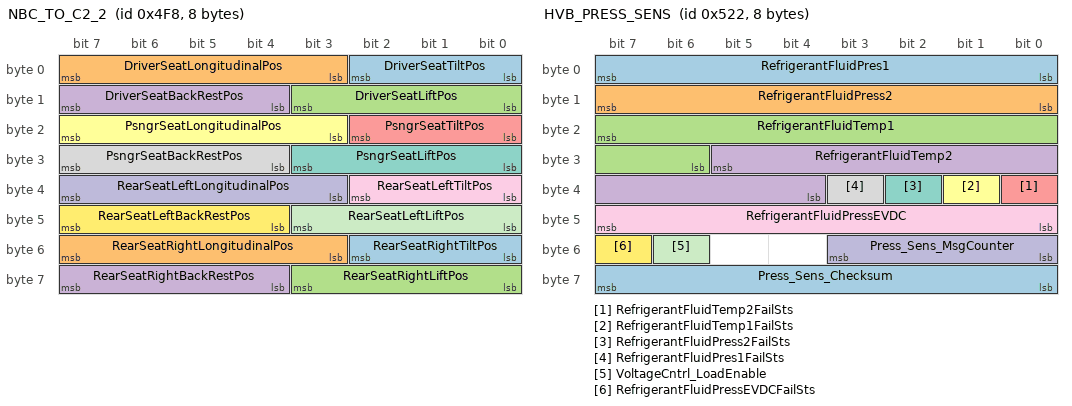
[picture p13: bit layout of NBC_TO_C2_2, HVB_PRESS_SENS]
BO_ 1272 NBC_TO_C2_2: 8 BCM
 SG_ DriverSeatTiltPos : 2|3@0+ (1.01,0) [0|7.07] "°"  SGW
 SG_ DriverSeatLongitudinalPos : 7|5@0+ (7.28,0) [0|225.68] "mm"  SGW
 SG_ DriverSeatLiftPos : 11|4@0+ (6.12,0) [0|91.8] "mm"  SGW
 SG_ DriverSeatBackRestPos : 15|4@0+ (3.88,0) [0|58.2] "°"  SGW
 SG_ PsngrSeatTiltPos : 18|3@0+ (1.01,0) [0|7.07] "°"  SGW
 SG_ PsngrSeatLongitudinalPos : 23|5@0+ (7.28,0) [0|225.68] "mm"  SGW
 SG_ PsngrSeatLiftPos : 27|4@0+ (6.12,0) [0|91.8] "mm"  SGW
 SG_ PsngrSeatBackRestPos : 31|4@0+ (3.88,0) [0|58.2] "°"  SGW
 SG_ RearSeatLeftTiltPos : 34|3@0+ (1.01,0) [0|7.07] "°"  SGW
 SG_ RearSeatLeftLongitudinalPos : 39|5@0+ (7.4,0) [0|229.4] "mm"  SGW
 SG_ RearSeatLeftLiftPos : 43|4@0+ (6.12,0) [0|91.8] "mm"  SGW
 SG_ RearSeatLeftBackRestPos : 47|4@0+ (2.69,0) [0|40.35] "°"  SGW
 SG_ RearSeatRightTiltPos : 50|3@0+ (1.01,0) [0|7.07] "°"  SGW
 SG_ RearSeatRightLongitudinalPos : 55|5@0+ (7.4,0) [0|229.4] "mm"  SGW
 SG_ RearSeatRightLiftPos : 59|4@0+ (6.12,0) [0|91.8] "mm"  SGW
 SG_ RearSeatRightBackRestPos : 63|4@0+ (2.69,0) [0|40.35] "°"  SGW

BO_ 1273 NBC_TO_C2: 8 BCM
 SG_ BlowerSpeed10L : 7|4@0+ (1,0) [0|15] ""  SGW
 SG_ AirConditionCompressor : 40|1@0+ (1,0) [0|1] ""  SGW

BO_ 1286 NFR_HMI: 8 SGW
 SG_ AVHDisplayInfo : 1|2@0+ (1,0) [0|3] ""  NDG,NQS
 SG_ HHCDisplayInfo : 2|1@0+ (1,0) [0|1] ""  NQS
 SG_ EBDDisplayInfo : 3|1@0+ (1,0) [0|1] ""  NDG,NQS
 SG_ ABSDisplayInfo : 4|1@0+ (1,0) [0|1] ""  NAB,NDG,NQS
 SG_ ESCOFFLampRequest : 5|1@0+ (1,0) [0|1] ""  NAB,NDG,NQS,NVO
 SG_ Reserved_AWDDisplayInfo : 6|1@0+ (1,0) [0|1] "" Vector__XXX
 SG_ BrakeFluidLevelSts : 7|1@0+ (1,0) [0|1] ""  NDG,NQS
 SG_ NFRSts : 11|4@0+ (1,0) [0|15] ""  NAB,NQS,NVO
 SG_ F1TCSDisplayInfo : 13|2@0+ (1,0) [0|3] ""  NAB,NDG,NQS,NVO
 SG_ EPBRemovePLRqtInfo : 14|1@0+ (1,0) [0|1] ""  NQS
 SG_ ThirdLightFaultSts : 15|1@0+ (1,0) [0|1] ""  NDG,NQS
 SG_ EPB_BrakePedalPressIndicationReq : 16|1@0+ (1,0) [0|1] ""  NQS
 SG_ EPB_BuzzerReq : 17|1@0+ (1,0) [0|1] ""  NQS
 SG_ LDIDisplayInfo : 20|3@0+ (1,0) [0|7] ""  NAB,NQS
 SG_ PBDisplayInfoValidData : 21|1@0+ (1,0) [0|1] ""  NQS
 SG_ VDCDisplayInfo : 23|2@0+ (1,0) [0|3] ""  NAB,NDG,NQS,NVO
 SG_ ServiceLampBlinkFreq : 26|3@0+ (1,0) [0|7] ""  NQS
 SG_ PBDisplayInfo : 31|5@0+ (1,0) [0|31] ""  NDG,NQS
 SG_ FadeWarning : 33|2@0+ (1,0) [0|3] ""  NQS
 SG_ EPBDisplayEnable : 35|2@0+ (1,0) [0|3] ""  NDG,NQS
 SG_ WarningLampReq : 37|2@0+ (1,0) [0|3] ""  NDG,NQS
 SG_ ServiceLampReq : 39|2@0+ (1,0) [0|3] ""  NQS
 SG_ MessageCounter : 51|4@0+ (1,0) [0|15] ""  BCM,NQS
 SG_ EPBLifeCycleWarning : 52|1@0+ (1,0) [0|1] ""  NDG,NQS
 SG_ HDC_Pop_Up : 55|3@0+ (1,0) [0|3] ""  NQS
 SG_ Checksum : 63|8@0+ (1,0) [0|255] ""  BCM,NQS

BO_ 1312 VEHSTAT: 8 BCM
 SG_ LowBeamSts_VEHSTAT : 0|1@0+ (1,0) [0|1] ""  SGW
 SG_ TurnIndicatorSts_CCAN1 : 2|2@0+ (1,0) [0|3] ""  NAB,SGW
 SG_ KeySts : 6|4@0+ (1,0) [0|15] "raw"  SGW
 SG_ LHRTurnLightFailSts : 8|1@0+ (1,0) [0|1] ""  NQS,SGW
 SG_ LHRParkTailLightFailSts : 9|1@0+ (1,0) [0|1] ""  NQS,SGW
 SG_ HazardLightSts : 10|1@0+ (1,0) [0|1] ""  NAB,SGW
 SG_ ADAS_heater : 11|1@0+ (1,0) [0|1] ""  SGW
 SG_ NBCFISSts : 12|1@0+ (1,0) [0|1] ""  SGW
 SG_ StopLightFault : 13|1@0+ (1,0) [0|1] ""  SGW
 SG_ AHBFeature : 14|1@0+ (1,0) [0|1] ""  NQS,NVO,SGW
 SG_ HighBeamSts_VEHSTAT : 15|1@0+ (1,0) [0|1] ""  SGW
 SG_ RHTurnSignalSts : 16|1@0+ (1,0) [0|1] ""  NQS,SGW
 SG_ RHStopLightFailSts : 17|1@0+ (1,0) [0|1] ""  NQS,SGW
 SG_ RHRTurnLightFailSts : 18|1@0+ (1,0) [0|1] ""  NQS,SGW
 SG_ RHRParkTailLightFailSts : 19|1@0+ (1,0) [0|1] ""  NQS,SGW
 SG_ RHFTurnLightFailSts : 21|1@0+ (1,0) [0|1] ""  NQS,SGW
 SG_ LHTurnSignalSts : 22|1@0+ (1,0) [0|1] ""  NQS,SGW
 SG_ LHStopLightFailSts : 23|1@0+ (1,0) [0|1] ""  NQS,SGW
 SG_ FrontWindshieldWiperMotErrSts : 29|1@0+ (1,0) [0|1] ""  NQS,SGW
 SG_ LHFTurnLightFailSts : 30|1@0+ (1,0) [0|1] ""  NQS,SGW
 SG_ NSVSts : 41|2@0+ (1,0) [0|3] ""  SGW
 SG_ message_counter_B01 : 51|4@0+ (1,0) [0|15] ""  SGW
 SG_ RLSWiperSpeed : 54|3@0+ (1,0) [0|7] ""  SGW
 SG_ FrontWiperModeSts : 55|1@0+ (1,0) [0|1] ""  SGW
 SG_ CRC_B01 : 63|8@0+ (1,0) [0|255] ""  SGW

BO_ 1313 STATUS_DOORS: 8 BCM
 SG_ STS_DRS_DriverLatchsts : 1|2@0+ (1,0) [0|3] ""  NDG,NVO,SGW
 SG_ STS_DRS_PsngrDoorSts : 3|2@0+ (1,0) [0|3] ""  NDG,NQS,NVO,SGW
 SG_ STS_DRS_DriverDoorSts : 5|2@0+ (1,0) [0|3] ""  NDG,NQS,NVO,SGW
 SG_ STS_DRS_VPSTrunkSts : 7|2@0+ (1,0) [0|3] ""  NDG,NQS,SGW
 SG_ STS_DRS_RearRightLatchsts : 9|2@0+ (1,0) [0|3] ""  NVO,SGW
 SG_ STS_DRS_RearLeftDoorSts : 11|2@0+ (1,0) [0|3] ""  NVO,SGW
 SG_ STS_DRS_RearRightDoorSts : 13|2@0+ (1,0) [0|3] ""  NVO,SGW
 SG_ STS_DRS_PsngrLatchsts : 15|2@0+ (1,0) [0|3] ""  NDG,NVO,SGW
 SG_ STS_DRS_PsngrWindowSts : 17|3@0+ (1,0) [0|7] ""  SGW
 SG_ STS_DRS_DriverWindowSts : 20|3@0+ (1,0) [0|7] ""  SGW
 SG_ STS_DRS_VPSLockValidData : 21|1@0+ (1,0) [0|1] ""  SGW
 SG_ STS_DRS_RearLeftLatchsts : 23|2@0+ (1,0) [0|3] ""  NVO,SGW
 SG_ STS_DRS_RearRightWindowSts : 27|3@0+ (1,0) [0|7] ""  SGW
 SG_ STS_DRS_RearLeftWindowSts : 30|3@0+ (1,0) [0|7] ""  SGW
 SG_ VPSDoorSts : 37|2@0+ (1,0) [0|3] ""  SGW
 SG_ STS_DRS_MsgCounter : 51|4@0+ (1,0) [0|15] ""  NQS,SGW
 SG_ STS_DRS_Checksum : 63|8@0+ (1,0) [0|255] ""  NQS,SGW

BO_ 1314 HVB_PRESS_SENS: 8 SGW
 SG_ RefrigerantFluidPres1 : 7|8@0+ (0.04,0) [0|10] "bar" Vector__XXX
 SG_ RefrigerantFluidPress2 : 15|8@0+ (0.04,0) [0|10] "bar" Vector__XXX
 SG_ RefrigerantFluidTemp1 : 23|10@0+ (0.1,-20) [-20|82.3] "°C" Vector__XXX
 SG_ RefrigerantFluidTemp2 : 29|10@0+ (0.1,-20) [-20|82.3] "°C" Vector__XXX
 SG_ RefrigerantFluidTemp2FailSts : 32|1@0+ (1,0) [0|1] "" Vector__XXX
 SG_ RefrigerantFluidTemp1FailSts : 33|1@0+ (1,0) [0|1] "" Vector__XXX
 SG_ RefrigerantFluidPress2FailSts : 34|1@0+ (1,0) [0|1] "" Vector__XXX
 SG_ RefrigerantFluidPres1FailSts : 35|1@0+ (1,0) [0|1] "" Vector__XXX
 SG_ RefrigerantFluidPressEVDC : 47|8@0+ (0.125,0) [0|31.875] "bar" Vector__XXX
 SG_ Press_Sens_MsgCounter : 51|4@0+ (1,0) [0|15] ""  BCM
 SG_ VoltageCntrl_LoadEnable : 54|1@0+ (1,0) [0|1] "" Vector__XXX
 SG_ RefrigerantFluidPressEVDCFailSts : 55|1@0+ (1,0) [0|1] "" Vector__XXX
 SG_ Press_Sens_Checksum : 63|8@0+ (1,0) [0|255] ""  BCM

BO_ 1317 STATUS_AUWP_HVB: 8 SGW
 SG_ SetSpeed : 7|8@0+ (28,0) [0|7000] "rpm" Vector__XXX
 SG_ ActualSpeed : 15|8@0+ (28,0) [0|7000] "rpm" Vector__XXX
 SG_ Voltage : 23|8@0+ (0.1,0) [0|25.4] "V" Vector__XXX
 SG_ Temperature : 31|8@0+ (1,-50) [-50|205] "°C" Vector__XXX
 SG_ Current : 39|8@0+ (0.2,0) [0|51] "A" Vector__XXX
 SG_ OverTemperature : 41|2@0+ (1,0) [0|3] "" Vector__XXX
 SG_ HVB_Load_Enable_NCL : 42|1@0+ (1,0) [0|1] "" Vector__XXX
 SG_ LT_WaterPumpRelayFailSts : 43|1@0+ (1,0) [0|1] "" Vector__XXX
 SG_ Stepmode : 45|2@0+ (1,0) [0|3] "" Vector__XXX
 SG_ LT_WaterPumpRelaySts : 47|2@0+ (1,0) [0|3] "" Vector__XXX
 SG_ Deblocking : 49|2@0+ (1,0) [0|3] "" Vector__XXX
 SG_ VoltageError : 51|2@0+ (1,0) [0|3] "" Vector__XXX
 SG_ DryRun : 53|2@0+ (1,0) [0|3] "" Vector__XXX
 SG_ OverCurrent : 55|2@0+ (1,0) [0|3] "" Vector__XXX
 SG_ CommunicationError : 56|1@0+ (1,0) [0|1] "" Vector__XXX
 SG_ StatusPostRunningMode : 59|3@0+ (1,0) [0|7] "" Vector__XXX
 SG_ EOBDII_FailureCleaningRqt : 60|1@0+ (1,0) [0|1] ""  BCM
 SG_ EOBDII_SecondaryNodes : 63|3@0+ (1,0) [0|7] ""  BCM

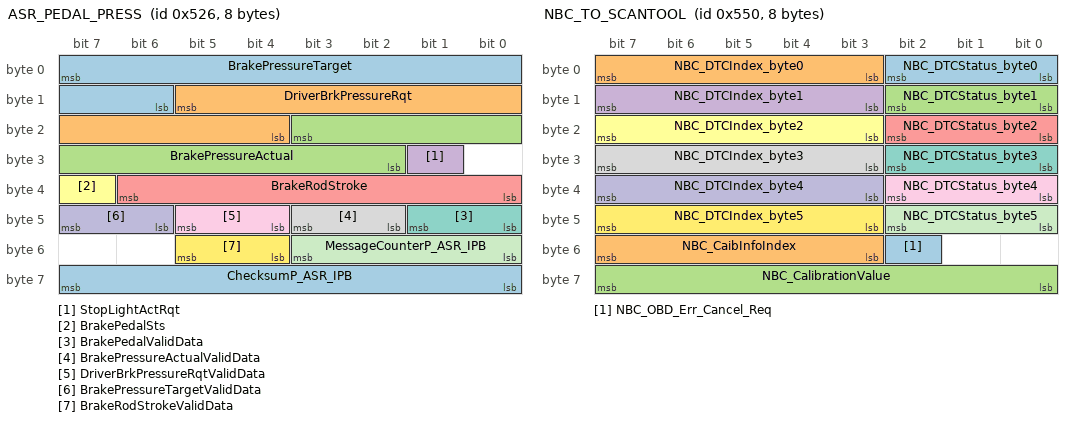
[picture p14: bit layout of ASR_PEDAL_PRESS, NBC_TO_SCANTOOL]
BO_ 1318 ASR_PEDAL_PRESS: 8 SGW
 SG_ BrakePressureTarget : 7|10@0+ (0.25,0) [0|200] "bar"  BCM
 SG_ DriverBrkPressureRqt : 13|10@0+ (0.25,0) [0|200] "bar"  BCM
 SG_ BrakePressureActual : 19|10@0+ (0.25,0) [0|200] "bar"  BCM,NDG,NQS
 SG_ StopLightActRqt : 25|1@0+ (1,0) [0|1] ""  BCM
 SG_ BrakeRodStroke : 38|7@0+ (0.2,0) [0|20] "mm"  BCM,NAB
 SG_ BrakePedalSts : 39|1@0+ (1,0) [0|1] ""  BCM,NAB,NDG,NQS
 SG_ BrakePedalValidData : 41|2@0+ (1,0) [0|3] ""  BCM,NAB,NDG,NQS
 SG_ BrakePressureActualValidData : 43|2@0+ (1,0) [0|3] ""  BCM,NDG,NQS
 SG_ DriverBrkPressureRqtValidData : 45|2@0+ (1,0) [0|3] ""  BCM
 SG_ BrakePressureTargetValidData : 47|2@0+ (1,0) [0|3] ""  BCM
 SG_ MessageCounterP_ASR_IPB : 51|4@0+ (1,0) [0|15] ""  BCM,NDG,NQS
 SG_ BrakeRodStrokeValidData : 53|2@0+ (1,0) [0|3] ""  BCM,NAB
 SG_ ChecksumP_ASR_IPB : 63|8@0+ (1,0) [0|255] ""  BCM,NDG,NQS

BO_ 1323 NCM_HYB_INFO: 8 SGW
 SG_ EngineWarmingInProgress : 0|1@0+ (1,0) [0|1] ""  NQS
 SG_ HManettinoTransitionInfo : 3|3@0+ (1,0) [0|7] ""  NQS
 SG_ HManettinoFailSts : 4|1@0+ (1,0) [0|1] ""  NDG,NQS,NVO
 SG_ HManettinoSts : 7|3@0+ (1,0) [0|7] ""  NDG,NQS,NVO
 SG_ LimpHomeWarningSts : 11|4@0+ (1,0) [0|15] ""  NDG,NQS
 SG_ FuelTankFlapEnable : 13|2@0+ (1,0) [0|3] ""  BCM
 SG_ EfficiencyMode : 15|2@0+ (1,0) [0|3] ""  NQS,NVO
 SG_ P2_To_Wheel : 17|2@0+ (1,0) [0|3] ""  NQS
 SG_ HybridLimpHomeSts : 20|3@0+ (1,0) [0|7] ""  NDG,NQS
 SG_ START_ButtonPress_Rqt : 23|2@0+ (1,0) [0|3] ""  NQS
 SG_ P2_To_HVB : 25|2@0+ (1,0) [0|3] ""  NQS
 SG_ eDriveStsForNqs : 27|2@0+ (1,0) [0|3] ""  NQS
 SG_ Engine_To_P2 : 28|1@0+ (1,0) [0|1] ""  NQS
 SG_ MAX_PWR : 31|3@0+ (1,0) [0|7] ""  NQS
 SG_ MAX_BST : 38|7@0+ (1,0) [0|100] "%"  NQS
 SG_ Engine_To_Wheel : 39|1@0+ (1,0) [0|1] ""  NQS
 SG_ MAX_GEN : 46|7@0+ (1,0) [0|100] "%"  NQS
 SG_ P2_To_P4 : 47|1@0+ (1,0) [0|1] ""  NQS
 SG_ VehicleStartNotAllowed : 48|1@0+ (1,0) [0|1] ""  NQS
 SG_ HVB_Lamp : 50|2@0+ (1,0) [0|3] ""  NQS
 SG_ P4_To_HVB : 52|2@0+ (1,0) [0|3] ""  NQS
 SG_ P4_To_Wheel : 54|2@0+ (1,0) [0|3] ""  NQS
 SG_ ICE_Lamp : 55|1@0+ (1,0) [0|1] ""  NQS
 SG_ OverboostStatus : 57|2@0+ (1,0) [0|3] ""  NQS
 SG_ OverboostLevel_NQS : 63|6@0+ (1,0) [0|60] ""  NQS

BO_ 1351 HAPTIC1: 8 SGW
 SG_ HALF_CHIME_TYPESts : 3|4@0+ (1,0) [0|15] "" Vector__XXX
 SG_ TSR_Fault : 4|1@0+ (1,0) [0|1] ""  NDG,NQS
 SG_ TSR_ON : 5|1@0+ (1,0) [0|1] ""  NQS
 SG_ LDWSystemSts : 7|2@0+ (1,0) [0|3] ""  NAB
 SG_ StatusLKA : 9|2@0+ (1,0) [0|3] ""  NAB,NDG,NQS
 SG_ AHBSensitivitySts : 11|2@0+ (1,0) [0|3] ""  BCM
 SG_ LDWSensitivitySts : 13|2@0+ (1,0) [0|3] "" Vector__XXX
 SG_ HALF_RF_CHIME_RQSts : 14|1@0+ (1,0) [0|1] "" Vector__XXX
 SG_ HALF_LF_CHIME_RQSts : 15|1@0+ (1,0) [0|1] "" Vector__XXX
 SG_ TSA_ON : 17|2@0+ (1,0) [0|3] ""  NQS
 SG_ HandsOnSts : 21|3@0+ (1,0) [0|7] ""  NQS
 SG_ StatusDDA : 23|2@0+ (1,0) [0|3] "" Vector__XXX
 SG_ LDW_Intensity_fbk : 25|2@0+ (1,0) [0|3] "" Vector__XXX
 SG_ ADAS_Unavailable_Camera : 27|2@0+ (1,0) [0|3] ""  NQS
 SG_ TSAMainSign2Fbk : 29|2@0+ (1,0) [0|3] ""  NQS
 SG_ TSASignChangeFbk : 31|2@0+ (1,0) [0|3] ""  NQS
 SG_ DDAW_Level : 35|4@0+ (1,0) [0|15] "" Vector__XXX
 SG_ DrowsinessSts : 37|2@0+ (1,0) [0|3] ""  NQS
 SG_ LDWWarningType_fbk : 39|2@0+ (1,0) [0|3] "" Vector__XXX
 SG_ DisplaySts : 40|8@0+ (1,0) [0|255] ""  NAB,NDG,NQS
 SG_ SensorBlinded : 41|1@0+ (1,0) [0|1] ""  BCM,NDG,NQS
 SG_ AHBFault : 42|1@0+ (1,0) [0|1] ""  BCM,NDG,NQS
 SG_ AHB_ON : 43|1@0+ (1,0) [0|1] ""  BCM
 SG_ TSR_Sts : 46|1@0+ (1,0) [0|1] "" Vector__XXX
 SG_ HALF_heaterSts : 47|1@0+ (1,0) [0|1] "" Vector__XXX
 SG_ DDAW_Index : 48|9@0+ (0.2,0) [0|100] "" Vector__XXX

BO_ 1360 NBC_TO_SCANTOOL: 8 BCM
 SG_ NBC_DTCStatus_byte0 : 2|3@0+ (1,0) [0|7] ""  SGW
 SG_ NBC_DTCIndex_byte0 : 7|5@0+ (1,0) [0|31] ""  SGW
 SG_ NBC_DTCStatus_byte1 : 10|3@0+ (1,0) [0|7] ""  SGW
 SG_ NBC_DTCIndex_byte1 : 15|5@0+ (1,0) [0|31] ""  SGW
 SG_ NBC_DTCStatus_byte2 : 18|3@0+ (1,0) [0|7] ""  SGW
 SG_ NBC_DTCIndex_byte2 : 23|5@0+ (1,0) [0|31] ""  SGW
 SG_ NBC_DTCStatus_byte3 : 26|3@0+ (1,0) [0|7] ""  SGW
 SG_ NBC_DTCIndex_byte3 : 31|5@0+ (1,0) [0|31] ""  SGW
 SG_ NBC_DTCStatus_byte4 : 34|3@0+ (1,0) [0|7] ""  SGW
 SG_ NBC_DTCIndex_byte4 : 39|5@0+ (1,0) [0|31] ""  SGW
 SG_ NBC_DTCStatus_byte5 : 42|3@0+ (1,0) [0|7] ""  SGW
 SG_ NBC_DTCIndex_byte5 : 47|5@0+ (1,0) [0|31] ""  SGW
 SG_ NBC_OBD_Err_Cancel_Req : 50|1@0+ (1,0) [0|1] ""  SGW
 SG_ NBC_CaibInfoIndex : 55|5@0+ (1,0) [0|31] ""  SGW
 SG_ NBC_CalibrationValue : 63|8@0+ (1,0) [0|255] ""  SGW

BO_ 1376 STATUS_B_CAN: 8 BCM
 SG_ IncreaseIdleSpeedReq_2 : 55|1@0+ (1,0) [0|1] ""  SGW
 SG_ VDCLamp_FailSts : 1|2@0+ (1,0) [0|3] ""  SGW
 SG_ TC_ASRLamp_FailSts : 3|2@0+ (1,0) [0|3] ""  SGW
 SG_ EBDLamp_FailSts : 5|2@0+ (1,0) [0|3] ""  SGW
 SG_ ABSLamp_FailSts : 7|2@0+ (1,0) [0|3] ""  SGW
 SG_ LifterButtonValidData : 8|1@0+ (1,0) [0|1] ""  SGW
 SG_ TrunkSts : 9|1@0+ (1,0) [0|1] ""  SGW
 SG_ ReverseGearBCSts : 10|1@0+ (1,0) [0|1] ""  SGW
 SG_ LifterButtonSts : 11|1@0+ (1,0) [0|1] ""  SGW
 SG_ AutoEPBButtonSts : 12|1@0+ (1,0) [0|1] ""  SGW
 SG_ SimpleCapoteSts : 13|1@0+ (1,0) [0|1] ""  SGW
 SG_ PowerModeSts : 15|2@0+ (1,0) [0|3] ""  SGW
 SG_ TrunkReleaseReqCntrl : 16|1@0+ (1,0) [0|1] ""  SGW
 SG_ BackWindowSts : 18|2@0+ (1,0) [0|3] ""  SGW
 SG_ DriverDoorSts : 19|1@0+ (1,0) [0|1] ""  NVO,SGW
 SG_ KeySts : 23|4@0+ (1,0) [0|15] "raw"  DMS,NAB,NDG,SGW
 SG_ ExternalTemperature : 31|8@0+ (0.5,-40) [-39.5|87.5] "°C"  NQS,SGW
 SG_ FuelLevelFailSts : 32|1@0+ (1,0) [0|1] ""  SGW
 SG_ RawNourriceLevel : 33|1@0+ (1,0) [0|1] ""  SGW
 SG_ IncreaseIdleSpeedReq : 34|1@0+ (1,0) [0|1] ""  SGW
 SG_ CompressorACReqSts : 35|1@0+ (1,0) [0|1] ""  SGW
 SG_ LowNourriceLevel : 36|1@0+ (1,0) [0|1] ""  SGW
 SG_ EngineBonnetSts : 37|1@0+ (1,0) [0|1] ""  SGW
 SG_ RemoteDoorUnlock : 38|1@0+ (1,0) [0|1] ""  SGW
 SG_ ExternalTemperatureFailSts : 39|1@0+ (1,0) [0|1] ""  NQS,SGW
 SG_ FuelLevelRawValue : 47|8@0+ (1,0) [0|100] "%"  SGW
 SG_ FOBSearchRequest : 49|2@0+ (1,0) [0|3] ""  SGW
 SG_ TheftAlarmStatus : 52|3@0+ (1,0) [0|7] ""  NDG,NVO,SGW
 SG_ SnowChainMode : 53|1@0+ (1,0) [0|1] ""  SGW
 SG_ NTPCalibrationReqSts : 54|1@0+ (1,0) [0|1] ""  SGW
 SG_ NBCStopStartButtonSts : 56|1@0+ (1,0) [0|1] ""  NQS,SGW
 SG_ PsngDoorSts : 57|1@0+ (1,0) [0|1] ""  NVO,SGW
 SG_ BCANAutoStopFailSts : 61|4@0+ (1,0) [0|15] ""  SGW
 SG_ BCANAutoStopStaySts : 62|1@0+ (1,0) [0|1] ""  SGW
 SG_ BCANAutoStopEnableSts : 63|1@0+ (1,0) [0|1] ""  SGW

BO_ 1377 STATUS_C_NCM: 8 SGW
 SG_ GenericFailSts_STATUS_C_NCM : 0|1@0+ (1,0) [0|1] ""  BCM
 SG_ CurrentFailSts : 1|1@0+ (1,0) [0|1] ""  BCM
 SG_ EOL : 2|1@0+ (1,0) [0|1] ""  BCM
 SG_ D_ES : 4|2@0+ (1,0) [0|3] ""  BCM
 SG_ CCSpeedWarning : 9|2@0+ (1,0) [0|1] ""  NQS
 SG_ LiIonBattWngOnDashBoard : 12|3@0+ (1,0) [0|7] ""  NDG
 SG_ GeneralDenominator : 13|1@0+ (1,0) [0|1] "" Vector__XXX
 SG_ OilPressureFailSts : 14|1@0+ (1,0) [0|1] ""  NDG,NQS
 SG_ OilPressureSts : 15|1@0+ (1,0) [0|1] ""  NDG,NQS
 SG_ EngineWaterTempWarningLightSts : 16|1@0+ (1,0) [0|1] ""  NDG,NQS
 SG_ EngineBonnetSts2_LH : 17|1@0+ (1,0) [0|1] "" Vector__XXX
 SG_ EngineWaterTempFailSts : 18|1@0+ (1,0) [0|1] ""  BCM,NDG,NQS
 SG_ EMSFailSts : 20|2@0+ (1,0) [0|3] ""  NDG
 SG_ LimpHomeSts : 21|1@0+ (1,0) [0|1] ""  NDG,NQS
 SG_ CompressorSts : 23|2@0+ (1,0) [0|3] ""  BCM
 SG_ EngineWaterTemp : 31|8@0+ (1,-40) [-40|215] "°C"  BCM,NDG,NQS
 SG_ FuelConsumption : 39|16@0+ (0.0044,0) [0|288] "litres/hour"  BCM,NQS
 SG_ EngineSpeed : 55|8@0+ (40,0) [0|10200] "rpm"  BCM,NDG,NQS
 SG_ SlowDownSts : 57|2@0+ (1,0) [0|3] ""  NDG,NQS
 SG_ ShiftIndicatorLightSts : 59|2@0+ (1,0) [0|3] ""  NQS
 SG_ OilLevelSts : 60|1@0+ (1,0) [0|1] ""  NDG,NQS
 SG_ EngineSpeedValidData : 61|1@0+ (1,0) [0|1] ""  BCM,NDG,NQS
 SG_ FuelConsumptionValidData : 62|1@0+ (1,0) [0|1] ""  NQS
 SG_ BatteryDisconnectionWarning : 63|1@0+ (1,0) [0|1] ""  NQS

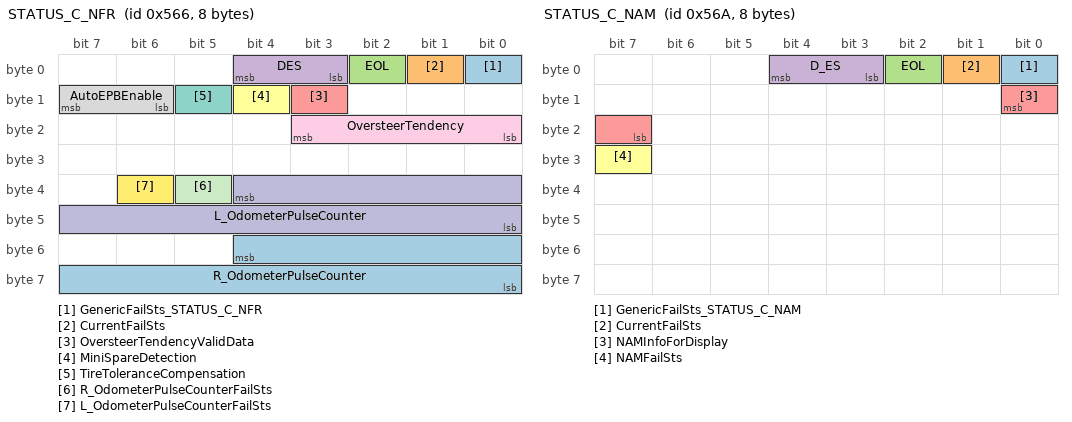
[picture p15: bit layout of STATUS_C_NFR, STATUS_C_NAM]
BO_ 1382 STATUS_C_NFR: 8 SGW
 SG_ GenericFailSts_STATUS_C_NFR : 0|1@0+ (1,0) [0|1] ""  BCM
 SG_ CurrentFailSts : 1|1@0+ (1,0) [0|1] ""  BCM
 SG_ EOL : 2|1@0+ (1,0) [0|1] ""  BCM
 SG_ DES : 4|2@0+ (1,0) [0|3] ""  BCM
 SG_ OversteerTendencyValidData : 11|1@0+ (1,0) [0|1] "" Vector__XXX
 SG_ MiniSpareDetection : 12|1@0+ (1,0) [0|1] ""  NQS
 SG_ TireToleranceCompensation : 13|1@0+ (1,0) [0|1] ""  NQS
 SG_ AutoEPBEnable : 15|2@0+ (1,0) [0|3] ""  NQS
 SG_ OversteerTendency : 19|4@0+ (3.33333,0) [0|49.99995] "%" Vector__XXX
 SG_ L_OdometerPulseCounter : 36|13@0+ (1,0) [0|8191] "pulses"  BCM
 SG_ R_OdometerPulseCounterFailSts : 37|1@0+ (1,0) [0|1] ""  BCM
 SG_ L_OdometerPulseCounterFailSts : 38|1@0+ (1,0) [0|1] ""  BCM
 SG_ R_OdometerPulseCounter : 52|13@0+ (1,0) [0|8191] "pulses"  BCM

BO_ 1386 STATUS_C_NAM: 8 SGW
 SG_ GenericFailSts_STATUS_C_NAM : 0|1@0+ (1,0) [0|1] ""  BCM
 SG_ CurrentFailSts : 1|1@0+ (1,0) [0|1] ""  BCM
 SG_ EOL : 2|1@0+ (1,0) [0|1] ""  BCM
 SG_ D_ES : 4|2@0+ (1,0) [0|3] ""  BCM
 SG_ NAMInfoForDisplay : 8|2@0+ (1,0) [0|3] ""  NQS
 SG_ NAMFailSts : 31|1@0+ (1,0) [0|1] ""  NQS

BO_ 1387 STATUS_C_NCA_NCR: 8 SGW
 SG_ GenericFailSts_STATUS_C_NCA_NCR : 0|1@0+ (1,0) [0|1] ""  BCM
 SG_ CurrentFailSts : 1|1@0+ (1,0) [0|1] ""  BCM
 SG_ EOL : 2|1@0+ (1,0) [0|1] ""  BCM
 SG_ D_ES : 4|2@0+ (1,0) [0|3] ""  BCM
 SG_ ShiftModeSts : 15|1@0+ (1,0) [0|1] ""  BCM,NDG,NQS
 SG_ Automatic_RoboticXmsnFailSts : 16|1@0+ (1,0) [0|1] ""  BCM,NDG,NQS
 SG_ ActualGearForDisplay : 20|4@0+ (1,0) [0|15] ""  BCM,NAB,NDG,NQS,NVO
 SG_ NCDFailSts : 22|2@0+ (1,0) [0|3] ""  BCM,NDG,NQS,NVO
 SG_ AutoEPBInhibitionReq : 26|1@0+ (1,0) [0|1] ""  BCM
 SG_ BuzzerReqSts : 29|2@0+ (1,0) [0|3] ""  BCM,NQS
 SG_ GearIndicationSts : 31|1@0+ (1,0) [0|1] ""  BCM,NDG,NQS
 SG_ AutomaticRoboticXmsnDegradedMode : 40|1@0+ (1,0) [0|1] ""  BCM,NDG,NQS
 SG_ PerformanceLaunchMode : 41|1@0+ (1,0) [0|1] ""  BCM,NDG,NQS,NVO
 SG_ RoboticTransmissionWarning : 47|6@0+ (1,0) [0|63] ""  BCM,NDG,NQS
 SG_ MessageCounter : 51|4@0+ (1,0) [0|15] ""  BCM,NQS,NVO
 SG_ PLockSts : 53|2@0+ (1,0) [0|3] ""  BCM
 SG_ NCR_EPB_Req : 54|1@0+ (1,0) [0|1] ""  BCM
 SG_ SailingAct : 55|1@0+ (1,0) [0|1] ""  BCM,NQS
 SG_ Checksum_STATUS_C_NCA_NCR : 63|8@0+ (1,0) [0|255] ""  BCM,NQS,NVO

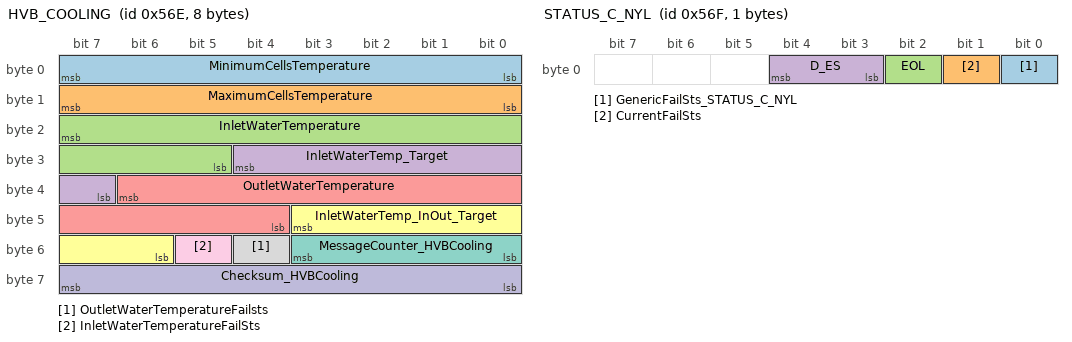
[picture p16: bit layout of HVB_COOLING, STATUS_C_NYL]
BO_ 1390 HVB_COOLING: 8 SGW
 SG_ MinimumCellsTemperature : 7|8@0+ (0.5,-40) [-40|80] "°C" Vector__XXX
 SG_ MaximumCellsTemperature : 15|8@0+ (0.5,-40) [-40|80] "°C"  NDG,NQS
 SG_ InletWaterTemperature : 23|11@0+ (0.05,-25) [-25|75] "°C" Vector__XXX
 SG_ InletWaterTemp_Target : 28|6@0+ (1,0) [0|63] "°C" Vector__XXX
 SG_ OutletWaterTemperature : 38|11@0+ (0.05,-25) [-25|75] "°C" Vector__XXX
 SG_ InletWaterTemp_InOut_Target : 43|6@0+ (1,0) [0|63] "°C" Vector__XXX
 SG_ MessageCounter_HVBCooling : 51|4@0+ (1,0) [0|15] "" Vector__XXX
 SG_ OutletWaterTemperatureFailsts : 52|1@0+ (1,0) [0|1] "" Vector__XXX
 SG_ InletWaterTemperatureFailSts : 53|1@0+ (1,0) [0|1] "" Vector__XXX
 SG_ Checksum_HVBCooling : 63|8@0+ (1,0) [0|255] "" Vector__XXX

BO_ 1391 STATUS_C_NYL: 1 SGW
 SG_ GenericFailSts_STATUS_C_NYL : 0|1@0+ (1,0) [0|1] ""  BCM
 SG_ CurrentFailSts : 1|1@0+ (1,0) [0|1] ""  BCM
 SG_ EOL : 2|1@0+ (1,0) [0|1] ""  BCM
 SG_ D_ES : 4|2@0+ (1,0) [0|3] ""  BCM

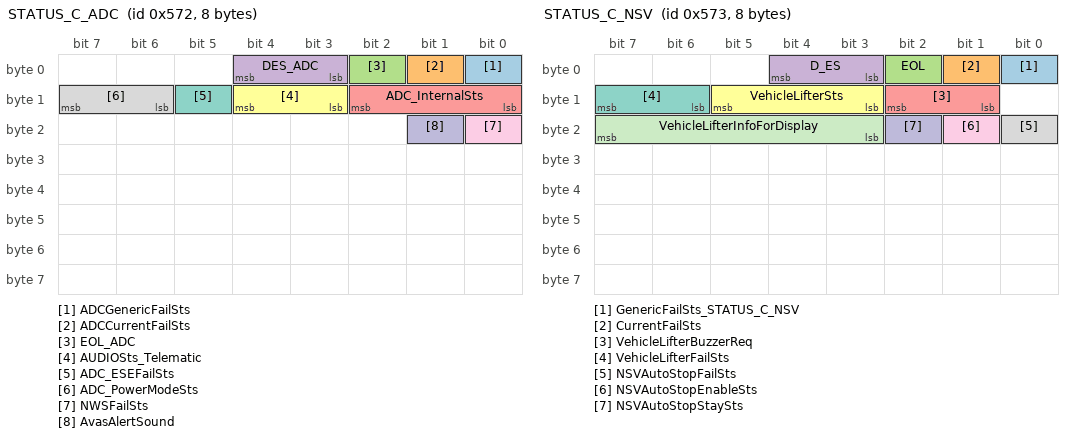
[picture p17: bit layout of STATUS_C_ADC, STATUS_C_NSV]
BO_ 1394 STATUS_C_ADC: 8 SGW
 SG_ ADCGenericFailSts : 0|1@0+ (1,0) [0|1] ""  BCM
 SG_ ADCCurrentFailSts : 1|1@0+ (1,0) [0|1] ""  BCM
 SG_ EOL_ADC : 2|1@0+ (1,0) [0|1] ""  BCM
 SG_ DES_ADC : 4|2@0+ (1,0) [0|3] ""  BCM
 SG_ ADC_InternalSts : 10|3@0+ (1,0) [0|7] "" Vector__XXX
 SG_ AUDIOSts_Telematic : 12|2@0+ (1,0) [0|3] ""  NQS
 SG_ ADC_ESEFailSts : 13|1@0+ (1,0) [0|1] ""  NQS
 SG_ ADC_PowerModeSts : 15|2@0+ (1,0) [0|3] ""  BCM
 SG_ NWSFailSts : 16|1@0+ (1,0) [0|1] ""  NDG,NQS
 SG_ AvasAlertSound : 17|1@0+ (1,0) [0|1] ""  NQS

BO_ 1395 STATUS_C_NSV: 8 SGW
 SG_ GenericFailSts_STATUS_C_NSV : 0|1@0+ (1,0) [0|1] ""  BCM
 SG_ CurrentFailSts : 1|1@0+ (1,0) [0|1] ""  BCM
 SG_ EOL : 2|1@0+ (1,0) [0|1] ""  BCM
 SG_ D_ES : 4|2@0+ (1,0) [0|3] ""  BCM
 SG_ VehicleLifterBuzzerReq : 10|2@0+ (1,0) [0|3] ""  NQS
 SG_ VehicleLifterSts : 13|3@0+ (1,0) [0|7] ""  BCM,NQS
 SG_ VehicleLifterFailSts : 15|2@0+ (1,0) [0|3] ""  BCM,NQS
 SG_ NSVAutoStopFailSts : 16|1@0+ (1,0) [0|1] "" Vector__XXX
 SG_ NSVAutoStopEnableSts : 17|1@0+ (1,0) [0|1] "" Vector__XXX
 SG_ NSVAutoStopStaySts : 18|1@0+ (1,0) [0|1] "" Vector__XXX
 SG_ VehicleLifterInfoForDisplay : 23|5@0+ (1,0) [0|31] ""  NDG,NQS

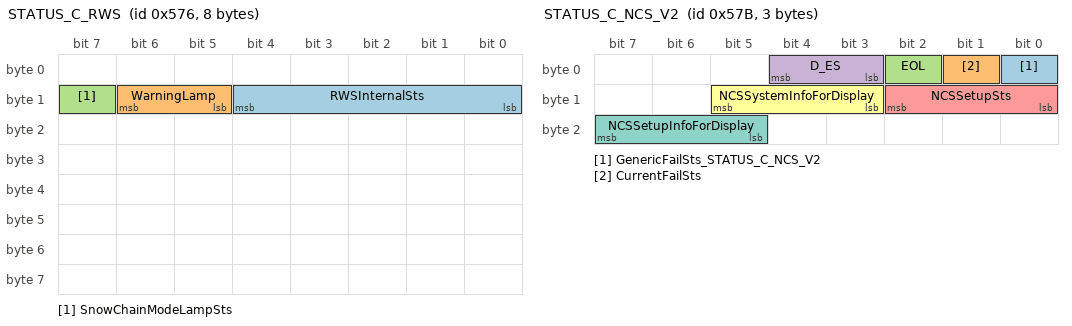
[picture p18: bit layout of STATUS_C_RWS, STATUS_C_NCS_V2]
BO_ 1398 STATUS_C_RWS: 8 SGW
 SG_ RWSInternalSts : 12|5@0+ (1,0) [0|31] ""  NQS
 SG_ WarningLamp : 14|2@0+ (1,0) [0|3] ""  NQS
 SG_ SnowChainModeLampSts : 15|1@0+ (1,0) [0|1] ""  NQS

BO_ 1403 STATUS_C_NCS_V2: 3 SGW
 SG_ GenericFailSts_STATUS_C_NCS_V2 : 0|1@0+ (1,0) [0|1] ""  BCM
 SG_ CurrentFailSts : 1|1@0+ (1,0) [0|1] ""  BCM
 SG_ EOL : 2|1@0+ (1,0) [0|1] ""  BCM
 SG_ D_ES : 4|2@0+ (1,0) [0|3] ""  BCM
 SG_ NCSSetupSts : 10|3@0+ (1,0) [0|7] ""  BCM,NQS
 SG_ NCSSystemInfoForDisplay : 13|3@0+ (1,0) [0|7] ""  BCM,NQS
 SG_ NCSSetupInfoForDisplay : 23|3@0+ (1,0) [0|7] ""  BCM,NQS

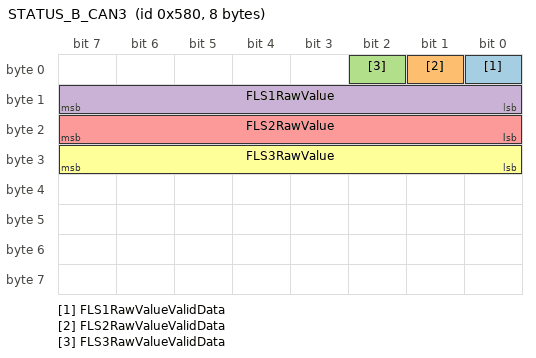
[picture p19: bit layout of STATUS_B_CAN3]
BO_ 1408 STATUS_B_CAN3: 8 BCM
 SG_ FLS1RawValueValidData : 0|1@0+ (1,0) [0|1] "" Vector__XXX
 SG_ FLS2RawValueValidData : 1|1@0+ (1,0) [0|1] "" Vector__XXX
 SG_ FLS3RawValueValidData : 2|1@0+ (1,0) [0|1] "" Vector__XXX
 SG_ FLS1RawValue : 15|8@0+ (1,0) [0|100] "%" Vector__XXX
 SG_ FLS2RawValue : 23|8@0+ (1,0) [0|100] "%" Vector__XXX
 SG_ FLS3RawValue : 31|8@0+ (1,0) [0|100] "%" Vector__XXX

CM_ "CAN_C1";
CM_ BU_ BCM "Nodo Body Computer";
CM_ BU_ NAB "Nodo AIRbag";
CM_ BU_ NQS "Nodo Quadro Strumenti";
CM_ BU_ NVO "Nodo Volante";
CM_ BU_ SGW "Secure Gateway";
CM_ SG_ 1530 MsgCounter_LCUSts "SAE J1850";
CM_ SG_ 2041 N_PDU_MTP_TST_RESP "This signal is used for EOL diagnostic purposes";
CM_ SG_ 2040 N_PDU_MTP_RESP "This signal is used for EOL diagnostic purposes";
CM_ SG_ 2033 N_PDU_MTP_TST_REQ "This signal is used for EOL diagnostic purposes";
CM_ SG_ 2032 N_PDU_MTP_REQ "This signal is used for EOL diagnostic purposes";
CM_ SG_ 57 Rnd_4 "In case the 4 byte field rnd_1 to rnd_4 is processed as a 32 bit integer, rnd_1 is the Most Significant Byte and rnd_4 the Least Significant Byte";
CM_ SG_ 57 F1_2 "In case the 2 byte field f2_1 to f2_2 is processed as a 16 bit integer, f2_1 is the Most Significant Byte and f2_2 is the Least Significant Byte";
CM_ SG_ 64 MKKey_2_or_g2_2 "In case the 2 byte field g2_1 to g2_2 is processed as a 16 bit integer, g2_1 is the Most Significant Byte and g2_2 is the Least Significant Byte";
CM_ SG_ 64 MKKey_6 "In case the 6 byte field MKKey_1 to MKKey_6 is processed as a 48 bit integer, MKKey_1 is the Most Significant Byte and MKKey_6 the Least Significant Byte";
CM_ SG_ 70 BrkRecSts "Status of regenerative braking";
CM_ SG_ 70 RearCtrlSts "Accept downshift with High RPM (negative torque) olny with MSTSts = Valid.";
CM_ SG_ 70 ACC_TorqueRequest_NFR "Nm @ wheel level";
CM_ SG_ 76 GearEngaged "{For 8Marce: Property = 'Not Coded'}";
CM_ SG_ 76 FutureSyncGear "{For 8Marce: Property = 'Not Coded'}";
CM_ SG_ 76 AMTIndex "values can be in the range [0-100]
0: full overlapshift
100: amtshift";
CM_ SG_ 76 DCTState "Details of this signal are reported into the Ferrari DCT Specification";
CM_ BO_ 175 "{For F173: Sender = NYL}";
CM_ SG_ 175 CRC "CRC according to SAE
J1850 standard";
CM_ SG_ 222 CRC_G "CRC according to SAE J1850 standard ";
CM_ SG_ 262 MessageCounter_ETO "Calculated by SAE-J1850";
CM_ SG_ 348 ACC_Engine_Torque "Nm @ wheel level";
CM_ SG_ 348 MessageCounter_DI "SAE J1850";
CM_ SG_ 348 CRC_DI "SAE J1850";
CM_ SG_ 359 RFRearFuncReq "{For F175: Sig_name = RFRearFuncReq}";
CM_ SG_ 359 FobSearchResult "   7         6       5       4         3              2                 1                 0
|Status|Status|Fault|Trunk|Interior|ExteriorRight|ExteriorLeft|ExteriorRear|

Status is 2 bits encoded as:
  7     6
  0     0   = NO_ACTION
  0     1   = IN_PROGRESS
  1     0   = COMPLETE
  1     1   = TIMEOUT

Fault: 0 = NO_FAULT, 1 = FAULT

Trunk, Interior, ExteriorRight, ExteriorLeft, ExteriorRear: 
0 = NO_FOB_IN_ZONE, 1 = FOB_IN_ZONE";
CM_ SG_ 359 FobSearchResult_LongPressure "Passive Entry system (ASC-PE)";
CM_ SG_ 390 B_OpenClutch "Frizione del differenziale libera (fattore di bloccaggio =0)";
CM_ SG_ 400 ChecksumNAM1 "According SAE J-1850";
CM_ SG_ 518 VRD_RH "Wheel Speed Right Rear.
{For NON-S&S applications: Range_MIN = 2,75}
IF speed < Range_MIN then speed = Range_MIN
Signal not valid for 600ms after startup";
CM_ SG_ 518 LH_WheelDirectionSts "Left Rear.
Signal not valid for 600ms after startup";
CM_ SG_ 518 VRD_LHValidData "Signal not valid for 600ms after startup";
CM_ SG_ 518 RH_WheelDirectionSts "Right Rear.
Signal not valid for 600ms after startup";
CM_ SG_ 518 VRD_RHValidData "Signal not valid for 600ms after startup";
CM_ SG_ 518 VRD_LH "Wheel Speed Left Rear.
{For NON-S&S applications: Range_MIN = 2,75}
IF speed < Range_MIN then speed = Range_MIN
Signal not valid for 600ms after startup";
CM_ SG_ 524 VehicleSpeedVSOSig "Speed is computed based on driven wheels ( rear wheels for Ferrari-Maserati )
This value is computed as the STATUS_C-NFR.VehicleSpeed received by NBC.
Signal not valid for 500ms after startup ";
CM_ SG_ 524 VehicleSpeedVSOSigFailSts "Signal not valid for 500ms after startup";
CM_ SG_ 524 ABSFailPresent "Signal not valid for 500ms after startup";
CM_ SG_ 524 MsgCounter "SAE J1850";
CM_ SG_ 524 NFRAutoStopFailSts "This signal indicates if is present a failure related to NFR that compromises S&S functionality (defined in F506).
Not trasmited in F150";
CM_ SG_ 524 NFRAutoStopStaySts "This signal indicates if the conditions managed by NFR needed for remaining with the engine in automatic stop or not.
Not trasmited in F150";
CM_ SG_ 524 NFRAutoStopEnableSts "This signal indicates if the conditions managed by NFR needed for enabling the automatic stop are fulfilled or not.
Not trasmited in F150";
CM_ SG_ 524 Checksum "According to SAE J1850";
CM_ SG_ 550 VRD_RV "Wheel Speed Right Front.
{For NON-S&S applications: Range_MIN = 2,75}
IF speed < Range_MIN then speed = Range_MIN
Signal not valid for 600ms after startup";
CM_ SG_ 550 LV_WheelDirectionSts "Left Front.
Signal not valid for 600ms after startup";
CM_ SG_ 550 VRD_LVValidData "Signal not valid for 600ms after startup";
CM_ SG_ 550 RV_WheelDirectionSts "Right Front.
Signal not valid for 600ms after startup";
CM_ SG_ 550 VRD_RVValidData "Signal not valid for 600ms after startup";
CM_ SG_ 550 VRD_LV "Wheel Speed Left Front.
{For NON-S&S applications: Range_MIN = 2,75}
IF speed < Range_MIN then speed = Range_MIN
Signal not valid for 600ms after startup";
CM_ SG_ 599 ChecksumNAB1 "According SAE J-1850";
CM_ BO_ 786 "{For F175: Period = 200}";
CM_ SG_ 865 VehDriverReqTrq "Nm @ clutch level";
CM_ SG_ 865 CylCutEnabled "Partial_cylinder_injection_cut_[enabled/not_enabled]_for_DCT";
CM_ SG_ 865 EngineSpeed "For Ferrari application FFFFhex means :
Data NotValid (Failure)
140322: Remove NOTE $FFFF as invalid value";
CM_ SG_ 865 GasPedalPosition "See Functional Requirements";
CM_ SG_ 929 MaxEngineTorque "Nm @ clutch level";
CM_ SG_ 929 EngineTorqueDriverReq "Nm @ clutch level";
CM_ SG_ 929 EngineTorque "Nm @ clutch level";
CM_ SG_ 930 MinEngineTorque_ACC "Nm @ clutch level";
CM_ SG_ 930 MaxEngineTorque_ACC "Nm @ clutch level";
CM_ SG_ 930 EngineSpeedHiRes "{For F173: Sig_name = Reserved}";
CM_ SG_ 930 EngineSpeedHiResValidData "{For F173: Sig_name = Not used}";
CM_ SG_ 930 Message_Counter_MT3 "SAE J1850";
CM_ SG_ 930 CRC_MT3 "SAE J1850";
CM_ SG_ 980 HManettinoDriverWishFailSts "Warming up cycle";
CM_ SG_ 980 ManettinoSuspensionSts "(*) See Project SFS for positions name definition";
CM_ SG_ 980 ManettinoSts "See Project SFS for positions name definition
Position 0 has not to be used by any project";
CM_ SG_ 988 TyrePressureSystemSts "TPMS_STAT_OFF";
CM_ SG_ 988 TyrePressureSystemFailSts "TPMS_STAT_SERVICE";
CM_ SG_ 988 TyrePressureSysCalibrationSts "TPMS_STAT_NOTCAL";
CM_ SG_ 988 NTPTempNotActiveSts "TPMS_STAT_TEMPNOTACT";
CM_ SG_ 988 NTPCalibrationReqACK "TPMS_STAT_CALACK";
CM_ SG_ 1023 MsgCounter_LCUCmd "SAE J1850";
CM_ SG_ 1023 Checksum_LCUCmd "SAE J1850";
CM_ SG_ 1058 OBC_ChrgrSt "The state of the charger";
CM_ SG_ 1060 Checksum_HVB_TO_OBC "SEAE-J1850";
CM_ BO_ 1214 "Fast message for 1M HS CAN (50ms)";
CM_ SG_ 1286 NFRSts "NVO FAILURE with values (2) and (3)";
CM_ SG_ 1286 ServiceLampBlinkFreq "Note:Without  ServiceLamp ON no blinkfrequency can be set.
Blinking must be processed with Colors set by ServiceLampColors Blinking means Flashing";
CM_ SG_ 1286 PBDisplayInfo "(1) See function F252";
CM_ SG_ 1286 WarningLampReq "Indicates all malfunctions ";
CM_ SG_ 1286 ServiceLampReq "Indicates all safety related malfunctions and system functions";
CM_ SG_ 1286 Checksum "According SAE J-1850";
CM_ SG_ 1312 message_counter_B01 "SAE J1850";
CM_ SG_ 1312 CRC_B01 "SAE J1850";
CM_ SG_ 1313 STS_DRS_DriverLatchsts "Passive Entry system (ASC-PE)";
CM_ SG_ 1313 STS_DRS_PsngrDoorSts "Passive Entry system (ASC-PE)";
CM_ SG_ 1313 STS_DRS_DriverDoorSts "Passive Entry system (ASC-PE)";
CM_ SG_ 1313 STS_DRS_RearRightLatchsts "Passive Entry system (ASC-PE)";
CM_ SG_ 1313 STS_DRS_RearLeftDoorSts "Passive Entry system (ASC-PE)";
CM_ SG_ 1313 STS_DRS_RearRightDoorSts "Passive Entry system (ASC-PE)";
CM_ SG_ 1313 STS_DRS_PsngrLatchsts "Passive Entry system (ASC-PE)";
CM_ SG_ 1313 STS_DRS_RearLeftLatchsts "Passive Entry system (ASC-PE)";
CM_ SG_ 1313 STS_DRS_MsgCounter "Passive Entry system (ASC-PE)";
CM_ SG_ 1313 STS_DRS_Checksum "According SAE J-1850 - Passive Entry system (ASC-PE)";
CM_ BO_ 1314 "{For F175: Sender = NCM}";
CM_ SG_ 1317 SetSpeed "0..254 (raw value)  Setspeed (min..max); raw value 250,251,252,253,254 have same rpm value: 7000 rpm
255 (raw value) Signal invalid";
CM_ SG_ 1317 ActualSpeed "0..254 (raw value)  Setspeed (min..max); raw value 250,251,252,253,254 have same rpm value: 7000 rpm
255 (raw value)  Signal invalid";
CM_ SG_ 1317 Voltage "0..25,4 Voltage
";
CM_ SG_ 1317 Temperature "0..254 Temperature
255 Signal invalid";
CM_ SG_ 1318 BrakePressureTarget "Target pressure value available by wire (p_TAR), it includes externnal brake requests (ACC, ?) NOT Available in Back Up mode";
CM_ SG_ 1318 DriverBrkPressureRqt "If valid, it is the master cylinder pressure (pMC), in the 'driver circuit'. Only in by wire mode is related to Brake Rod Stroke (sPTS) by the DBR-curve. In back Up mode reflects the actual pressure in the caliper circuit. ";
CM_ SG_ 1318 BrakePressureActual "Maximum pressure value available at wheels (pS_SP). NOTAvailable in Back Up mode";
CM_ SG_ 1318 StopLightActRqt "This signal is internally used by NBC only. There aren?t any changes for Gateway Function.";
CM_ SG_ 1318 BrakeRodStroke "Available in both 'by wire' and 'Back Up' mode.
Indicate if the Bake pedal is pressed or not AND the amount of the Rod stroke";
CM_ SG_ 1318 BrakePedalSts "Available in both 'by wire' and 'Back Up' mode.
Indicate if the Bake pedal is pressed or not";
CM_ SG_ 1318 DriverBrkPressureRqtValidData "Signal not valid for 800ms after startup";
CM_ SG_ 1360 NBC_DTCStatus_byte0 "Norm SD13430";
CM_ SG_ 1360 NBC_DTCIndex_byte0 "Diagnostic Trouble Code Index, Norm SD13430";
CM_ SG_ 1360 NBC_DTCStatus_byte1 "Norm SD13430";
CM_ SG_ 1360 NBC_DTCIndex_byte1 "Diagnostic Trouble Code Index, Norm SD13430";
CM_ SG_ 1360 NBC_DTCStatus_byte2 "Norm SD13430";
CM_ SG_ 1360 NBC_DTCIndex_byte2 "Diagnostic Trouble Code Index, Norm SD13430";
CM_ SG_ 1360 NBC_DTCStatus_byte3 "Norm SD13430";
CM_ SG_ 1360 NBC_DTCIndex_byte3 "Diagnostic Trouble Code Index, Norm SD13430";
CM_ SG_ 1360 NBC_DTCStatus_byte4 "Norm SD13430";
CM_ SG_ 1360 NBC_DTCIndex_byte4 "Diagnostic Trouble Code Index, Norm SD13430";
CM_ SG_ 1360 NBC_DTCStatus_byte5 "Norm SD13430";
CM_ SG_ 1360 NBC_DTCIndex_byte5 "Diagnostic Trouble Code Index, Norm SD13430";
CM_ SG_ 1360 NBC_CaibInfoIndex "Index: 0-15 ? Cal ID
Index: 16-19 ? CVZ , Norm SD13430";
CM_ SG_ 1360 NBC_CalibrationValue "Index: 0-15 ? Cal ID
Index: 16-19 ? CVZ , Norm SD13430";
CM_ SG_ 1376 TrunkReleaseReqCntrl "Passive Entry system (ASC-PE)";
CM_ SG_ 1376 ExternalTemperature "value = -40°C. This value is not the real extenal temperature processed: it means means no valid data available";
CM_ SG_ 1376 NBCStopStartButtonSts "This signal indicates the status of the S&S activation according to the status of the button. Startup / Default value depends from the value of previus key off. Default has to be used in case of battery disconnection.";
CM_ SG_ 1376 BCANAutoStopFailSts "This signal indicates if is present a faillure on BCAN Nodes that compromises S&S functionality
Bit 0 - NCLAutoStopFailSts
Bit 1 - NQSAutoStopFailSts 
Bit 2 - NCPAutoStopFailSts
Bit 3 - NBCAutoStopFailSts
Bits? Values: 
0 = Fail Not present
1 = Fail Present
0 = Startup / Default
The bits can be transmitted simultaneously.";
CM_ SG_ 1376 BCANAutoStopStaySts "This signal indicates if the conditions managed by NBC needed for remaining with the engine in automatic stop or not.";
CM_ SG_ 1376 BCANAutoStopEnableSts "This signal indicates if the conditions managed by NBC needed for enabling the automatic stop are fulfilled or not.";
CM_ SG_ 1377 CompressorSts "{For 48V: Property = 'Inserted by NCM'}";
CM_ SG_ 1377 FuelConsumption "{For F149: Range_MAX = 144;
Resolution = 0.0022}";
CM_ SG_ 1377 EngineSpeed "For Ferrari application Range High is extended from 8000 to 10200 rpm.
Resolution has been increased from 32 to 40 rpm.";
CM_ SG_ 1377 BatteryDisconnectionWarning "signal used to inform the driver to don't disconnect the Battery";
CM_ SG_ 1387 NCDFailSts "0 niente
1 spia ambra
2 spia ambra e richiesta a NVO di forzare il manettino in prima posizione
3 spia rossa e richiesta a NVO di forzare il manettino in prima posizione";
CM_ SG_ 1387 RoboticTransmissionWarning "For all property see note field in F200";
CM_ SG_ 1387 PLockSts "{For VetturaTermica: Sig_name = PLockSts}";
CM_ SG_ 1387 NCR_EPB_Req "{For VetturaTermica: Sig_name = NCR_EPB_Req}";
CM_ SG_ 1390 MinimumCellsTemperature "Actual value, required for pulse charging";
CM_ BO_ 1391 "{For F173: Sender = NYL}";
CM_ SG_ 1395 NSVAutoStopFailSts "This signal indicates if is present a faillure related to NSV that compromises S&S functionality";
CM_ SG_ 1395 NSVAutoStopEnableSts "This signal indicates if the conditions managed by NSV needed for enabling the automatic stop are fulfilled or not";
CM_ SG_ 1395 NSVAutoStopStaySts "This signal indicates if the conditions managed by NSV needed for remaining with the engine in automatic stop or not.";
BA_DEF_ SG_  "GenSigSendType" ENUM  "NotUsed","OnWrite","OnWriteWithRepetition","OnChange","OnChangeWithRepetition","IfActive","IfActiveWithRepetition","NoSigSendType";
BA_DEF_ SG_  "GenSigInactiveValue" INT 0 2147483647;
BA_DEF_ SG_  "GenSigStartValue" INT 0 2147483647;
BA_DEF_ BO_  "DiagState" ENUM  "No","Yes";
BA_DEF_ BO_  "GenMsgDelayTime" INT 0 65535;
BA_DEF_ BO_  "GenMsgCycleTimeFast" INT 0 65535;
BA_DEF_ BO_  "GenMsgStartDelayTime" INT 0 65535;
BA_DEF_ BO_  "GenMsgILSupport" ENUM  "No","Yes";
BA_DEF_ BO_  "GenMsgNrOfRepetition" INT 0 255;
BA_DEF_ BO_  "GenMsgTimeoutTime" INT 0 10000;
BA_DEF_ BO_  "GenMsgSendType" ENUM  "Cyclic","NotUsed","NotUsed","NotUsed","NotUsed","NotUsed","NotUsed","NotUsed","NoMsgSendType";
BA_DEF_ BO_  "NmMessage" ENUM  "No","Yes";
BA_DEF_ BO_  "Type" ENUM  "P","C","PE","COC","PE_Cntrl","E","E_Cntrl","OC","S","BAF","DC","EM","MM","-";
BA_DEF_ BO_  "Period" INT 0 65535;
BA_DEF_ BU_  "TpOwnSystemEcuNumber" HEX 0 255;
BA_DEF_ BU_  "NwmNodeType" ENUM  "kMaster","kSlave15","kSlave30","none";
BA_DEF_ BU_  "NmNodeType" ENUM  "kMaster","kSlave15","kSlave30","none";
BA_DEF_ BU_  "ILUsed" ENUM  "No","Yes";
BA_DEF_ BU_  "NmNode" ENUM  "No","Yes";
BA_DEF_ BU_  "NmStationAddress" HEX 0 255;
BA_DEF_ BU_  "NodeLayerModules" STRING ;
BA_DEF_ BU_  "Description" STRING ;
BA_DEF_  "Manufacturer" STRING ;
BA_DEF_  "VersionYear" INT 0 99;
BA_DEF_  "VersionWeek" INT 0 53;
BA_DEF_  "Version" HEX 0 255;
BA_DEF_  "DBName" STRING ;
BA_DEF_  "Baudrate_ARB" INT 0 1000000;
BA_DEF_  "Baudrate_DATA" INT 0 0;
BA_DEF_  "BusType" STRING ;
BA_DEF_ SG_  "EventTrans" ENUM  "Yes","No";
BA_DEF_  "NmType" STRING ;
BA_DEF_ SG_  "Accuracy" STRING ;
BA_DEF_ SG_  "SignalAge" INT 0 100000;
BA_DEF_ SG_  "InitialValue" INT -65536 65535;
BA_DEF_ BO_  "DiagResponse" ENUM  "No","Yes";
BA_DEF_ BO_  "DiagRequest" ENUM  "No","Yes";
BA_DEF_ BO_  "GenMsgCycleTime" INT 0 10000;
BA_DEF_DEF_  "GenSigSendType" "NoSigSendType";
BA_DEF_DEF_  "GenSigInactiveValue" 0;
BA_DEF_DEF_  "GenSigStartValue" 0;
BA_DEF_DEF_  "DiagState" "No";
BA_DEF_DEF_  "GenMsgDelayTime" 0;
BA_DEF_DEF_  "GenMsgCycleTimeFast" 0;
BA_DEF_DEF_  "GenMsgStartDelayTime" 0;
BA_DEF_DEF_  "GenMsgILSupport" "No";
BA_DEF_DEF_  "GenMsgNrOfRepetition" 0;
BA_DEF_DEF_  "GenMsgTimeoutTime" 0;
BA_DEF_DEF_  "GenMsgSendType" "NoMsgSendType";
BA_DEF_DEF_  "NmMessage" "No";
BA_DEF_DEF_  "Type" "-";
BA_DEF_DEF_  "Period" 0;
BA_DEF_DEF_  "TpOwnSystemEcuNumber" 0;
BA_DEF_DEF_  "NwmNodeType" "none";
BA_DEF_DEF_  "NmNodeType" "none";
BA_DEF_DEF_  "ILUsed" "Yes";
BA_DEF_DEF_  "NmNode" "Yes";
BA_DEF_DEF_  "NmStationAddress" 0;
BA_DEF_DEF_  "NodeLayerModules" "Osek_TP.dll";
BA_DEF_DEF_  "Description" "";
BA_DEF_DEF_  "Manufacturer" "Ferrari";
BA_DEF_DEF_  "VersionYear" 13;
BA_DEF_DEF_  "VersionWeek" 51;
BA_DEF_DEF_  "Version" 160;
BA_DEF_DEF_  "DBName" "CAN";
BA_DEF_DEF_  "Baudrate_ARB" 500000;
BA_DEF_DEF_  "Baudrate_DATA" 500000;
BA_DEF_DEF_  "BusType" "";
BA_DEF_DEF_  "EventTrans" "No";
BA_DEF_DEF_  "NmType" "";
BA_DEF_DEF_  "Accuracy" "";
BA_DEF_DEF_  "SignalAge" 0;
BA_DEF_DEF_  "InitialValue" 0;
BA_DEF_DEF_  "DiagResponse" "No";
BA_DEF_DEF_  "DiagRequest" "No";
BA_DEF_DEF_  "GenMsgCycleTime" 0;
BA_ "BusType" "CAN";
BA_ "NmType" "Fiat_Class_C";
BA_ "Manufacturer" "Fiat";
BA_ "DBName" "CAN_C1";
BA_ "Description" BU_ BCM "Body Control Module";
BA_ "NmNodeType" BU_ BCM 0;
BA_ "NmStationAddress" BU_ BCM 64;
BA_ "NwmNodeType" BU_ BCM 0;
BA_ "TpOwnSystemEcuNumber" BU_ BCM 64;
BA_ "Description" BU_ DMS "Driver Monitoring System";
BA_ "NmNodeType" BU_ DMS 2;
BA_ "NmStationAddress" BU_ DMS 77;
BA_ "NwmNodeType" BU_ DMS 2;
BA_ "TpOwnSystemEcuNumber" BU_ DMS 77;
BA_ "Description" BU_ NAB "Nodo Airbag";
BA_ "NmStationAddress" BU_ NAB 192;
BA_ "TpOwnSystemEcuNumber" BU_ NAB 192;
BA_ "NmNodeType" BU_ NAB 2;
BA_ "NwmNodeType" BU_ NAB 2;
BA_ "Description" BU_ NDG "Nodo Dongle";
BA_ "Description" BU_ NQS "Nodo Quadro Strumenti";
BA_ "NmStationAddress" BU_ NQS 133;
BA_ "TpOwnSystemEcuNumber" BU_ NQS 133;
BA_ "Description" BU_ NVO "Nodo Volante";
BA_ "NmStationAddress" BU_ NVO 143;
BA_ "TpOwnSystemEcuNumber" BU_ NVO 143;
BA_ "Description" BU_ SGW "Secure Gateway";
BA_ "NmStationAddress" BU_ SGW 203;
BA_ "TpOwnSystemEcuNumber" BU_ SGW 203;
BA_ "NwmNodeType" BU_ SGW 2;
BA_ "NmNodeType" BU_ SGW 2;
BA_ "GenMsgCycleTime" BO_ 1722 250;
BA_ "Period" BO_ 1722 250;
BA_ "Type" BO_ 1722 1;
BA_ "GenMsgSendType" BO_ 1722 0;
BA_ "GenMsgTimeoutTime" BO_ 1722 2500;
BA_ "GenMsgILSupport" BO_ 1722 1;
BA_ "Type" BO_ 2654208005 8;
BA_ "NmMessage" BO_ 2654208005 1;
BA_ "GenMsgILSupport" BO_ 2654208005 1;
BA_ "GenMsgStartDelayTime" BO_ 2654208005 10;
BA_ "GenMsgCycleTime" BO_ 1212 100;
BA_ "Period" BO_ 1212 100;
BA_ "GenMsgSendType" BO_ 1212 0;
BA_ "Type" BO_ 1212 3;
BA_ "GenMsgTimeoutTime" BO_ 1212 2500;
BA_ "GenMsgILSupport" BO_ 1212 1;
BA_ "GenMsgCycleTime" BO_ 2654339077 500;
BA_ "Period" BO_ 2654339077 500;
BA_ "Type" BO_ 2654339077 1;
BA_ "GenMsgSendType" BO_ 2654339077 0;
BA_ "GenMsgTimeoutTime" BO_ 2654339077 2500;
BA_ "GenMsgILSupport" BO_ 2654339077 1;
BA_ "Type" BO_ 2564453105 8;
BA_ "DiagRequest" BO_ 2564453105 1;
BA_ "Type" BO_ 2564453361 8;
BA_ "DiagRequest" BO_ 2564453361 1;
BA_ "GenMsgILSupport" BO_ 204 1;
BA_ "GenMsgTimeoutTime" BO_ 204 2500;
BA_ "GenMsgSendType" BO_ 204 0;
BA_ "Type" BO_ 204 1;
BA_ "Period" BO_ 204 10;
BA_ "GenMsgCycleTime" BO_ 204 10;
BA_ "GenMsgILSupport" BO_ 1388 1;
BA_ "GenMsgTimeoutTime" BO_ 1388 2500;
BA_ "GenMsgSendType" BO_ 1388 0;
BA_ "Type" BO_ 1388 1;
BA_ "Period" BO_ 1388 250;
BA_ "GenMsgCycleTime" BO_ 1388 250;
BA_ "GenMsgILSupport" BO_ 1530 1;
BA_ "GenMsgTimeoutTime" BO_ 1530 2500;
BA_ "GenMsgSendType" BO_ 1530 0;
BA_ "Type" BO_ 1530 3;
BA_ "Period" BO_ 1530 100;
BA_ "GenMsgCycleTime" BO_ 1530 100;
BA_ "Type" BO_ 2564485490 8;
BA_ "DiagResponse" BO_ 2564485490 1;
BA_ "Type" BO_ 2564485491 8;
BA_ "DiagResponse" BO_ 2564485491 1;
BA_ "Type" BO_ 2041 11;
BA_ "GenMsgILSupport" BO_ 2041 1;
BA_ "Type" BO_ 2040 11;
BA_ "GenMsgILSupport" BO_ 2040 1;
BA_ "Type" BO_ 2033 11;
BA_ "GenMsgILSupport" BO_ 2033 1;
BA_ "Type" BO_ 2032 11;
BA_ "GenMsgILSupport" BO_ 2032 1;
BA_ "Type" BO_ 57 11;
BA_ "GenMsgILSupport" BO_ 57 1;
BA_ "Type" BO_ 64 11;
BA_ "GenMsgILSupport" BO_ 64 1;
BA_ "GenMsgCycleTime" BO_ 70 20;
BA_ "GenMsgILSupport" BO_ 70 1;
BA_ "GenMsgSendType" BO_ 70 0;
BA_ "GenMsgTimeoutTime" BO_ 70 2500;
BA_ "Period" BO_ 70 20;
BA_ "Type" BO_ 70 0;
BA_ "GenMsgCycleTime" BO_ 76 10;
BA_ "GenMsgILSupport" BO_ 76 1;
BA_ "GenMsgSendType" BO_ 76 0;
BA_ "GenMsgTimeoutTime" BO_ 76 2500;
BA_ "Period" BO_ 76 10;
BA_ "Type" BO_ 76 0;
BA_ "GenMsgCycleTime" BO_ 175 10;
BA_ "GenMsgILSupport" BO_ 175 1;
BA_ "GenMsgSendType" BO_ 175 0;
BA_ "GenMsgTimeoutTime" BO_ 175 2500;
BA_ "Period" BO_ 175 10;
BA_ "Type" BO_ 175 1;
BA_ "GenMsgCycleTime" BO_ 222 10;
BA_ "GenMsgILSupport" BO_ 222 1;
BA_ "GenMsgSendType" BO_ 222 0;
BA_ "GenMsgTimeoutTime" BO_ 222 2500;
BA_ "Period" BO_ 222 10;
BA_ "Type" BO_ 222 1;
BA_ "GenMsgCycleTime" BO_ 262 10;
BA_ "GenMsgILSupport" BO_ 262 1;
BA_ "GenMsgSendType" BO_ 262 0;
BA_ "GenMsgTimeoutTime" BO_ 262 2500;
BA_ "Period" BO_ 262 10;
BA_ "Type" BO_ 262 1;
BA_ "GenMsgCycleTime" BO_ 326 20;
BA_ "GenMsgILSupport" BO_ 326 1;
BA_ "GenMsgSendType" BO_ 326 0;
BA_ "GenMsgTimeoutTime" BO_ 326 2500;
BA_ "Period" BO_ 326 20;
BA_ "Type" BO_ 326 0;
BA_ "GenMsgCycleTime" BO_ 348 20;
BA_ "GenMsgCycleTimeFast" BO_ 348 20;
BA_ "GenMsgDelayTime" BO_ 348 10;
BA_ "GenMsgILSupport" BO_ 348 1;
BA_ "GenMsgNrOfRepetition" BO_ 348 2;
BA_ "GenMsgSendType" BO_ 348 0;
BA_ "GenMsgStartDelayTime" BO_ 348 20;
BA_ "GenMsgTimeoutTime" BO_ 348 2500;
BA_ "Period" BO_ 348 20;
BA_ "Type" BO_ 348 1;
BA_ "GenMsgCycleTime" BO_ 359 20;
BA_ "GenMsgILSupport" BO_ 359 1;
BA_ "GenMsgTimeoutTime" BO_ 359 2500;
BA_ "Period" BO_ 359 20;
BA_ "Type" BO_ 359 11;
BA_ "GenMsgCycleTime" BO_ 390 20;
BA_ "GenMsgILSupport" BO_ 390 1;
BA_ "GenMsgSendType" BO_ 390 0;
BA_ "GenMsgTimeoutTime" BO_ 390 2500;
BA_ "Period" BO_ 390 20;
BA_ "Type" BO_ 390 0;
BA_ "GenMsgCycleTime" BO_ 400 10;
BA_ "GenMsgILSupport" BO_ 400 1;
BA_ "GenMsgSendType" BO_ 400 0;
BA_ "GenMsgTimeoutTime" BO_ 400 2500;
BA_ "Period" BO_ 400 20;
BA_ "Type" BO_ 400 0;
BA_ "GenMsgCycleTime" BO_ 426 20;
BA_ "GenMsgILSupport" BO_ 426 1;
BA_ "GenMsgSendType" BO_ 426 0;
BA_ "GenMsgTimeoutTime" BO_ 426 2500;
BA_ "Period" BO_ 426 20;
BA_ "Type" BO_ 426 0;
BA_ "GenMsgCycleTime" BO_ 502 10;
BA_ "GenMsgILSupport" BO_ 502 1;
BA_ "GenMsgSendType" BO_ 502 0;
BA_ "GenMsgTimeoutTime" BO_ 502 2500;
BA_ "Period" BO_ 502 10;
BA_ "Type" BO_ 502 1;
BA_ "GenMsgCycleTime" BO_ 518 20;
BA_ "GenMsgILSupport" BO_ 518 1;
BA_ "GenMsgSendType" BO_ 518 0;
BA_ "GenMsgTimeoutTime" BO_ 518 2500;
BA_ "Period" BO_ 518 20;
BA_ "Type" BO_ 518 0;
BA_ "GenMsgCycleTime" BO_ 524 20;
BA_ "GenMsgILSupport" BO_ 524 1;
BA_ "GenMsgSendType" BO_ 524 0;
BA_ "GenMsgTimeoutTime" BO_ 524 2500;
BA_ "Period" BO_ 524 20;
BA_ "Type" BO_ 524 0;
BA_ "GenMsgCycleTime" BO_ 550 20;
BA_ "GenMsgILSupport" BO_ 550 1;
BA_ "GenMsgSendType" BO_ 550 0;
BA_ "GenMsgTimeoutTime" BO_ 550 2500;
BA_ "Period" BO_ 550 20;
BA_ "Type" BO_ 550 0;
BA_ "GenMsgCycleTime" BO_ 599 100;
BA_ "GenMsgDelayTime" BO_ 599 10;
BA_ "GenMsgILSupport" BO_ 599 1;
BA_ "GenMsgSendType" BO_ 599 0;
BA_ "GenMsgTimeoutTime" BO_ 599 2500;
BA_ "Period" BO_ 599 100;
BA_ "Type" BO_ 599 3;
BA_ "GenMsgCycleTime" BO_ 786 200;
BA_ "GenMsgILSupport" BO_ 786 1;
BA_ "GenMsgSendType" BO_ 786 0;
BA_ "GenMsgTimeoutTime" BO_ 786 2500;
BA_ "Period" BO_ 786 200;
BA_ "Type" BO_ 786 1;
BA_ "GenMsgCycleTime" BO_ 865 10;
BA_ "GenMsgILSupport" BO_ 865 1;
BA_ "GenMsgSendType" BO_ 865 0;
BA_ "GenMsgTimeoutTime" BO_ 865 2500;
BA_ "Period" BO_ 865 10;
BA_ "Type" BO_ 865 0;
BA_ "GenMsgCycleTime" BO_ 870 250;
BA_ "GenMsgILSupport" BO_ 870 1;
BA_ "GenMsgSendType" BO_ 870 0;
BA_ "GenMsgTimeoutTime" BO_ 870 2500;
BA_ "Period" BO_ 870 250;
BA_ "Type" BO_ 870 3;
BA_ "GenMsgCycleTime" BO_ 929 10;
BA_ "GenMsgILSupport" BO_ 929 1;
BA_ "GenMsgSendType" BO_ 929 0;
BA_ "GenMsgTimeoutTime" BO_ 929 2500;
BA_ "Period" BO_ 929 10;
BA_ "Type" BO_ 929 0;
BA_ "GenMsgCycleTime" BO_ 930 10;
BA_ "GenMsgILSupport" BO_ 930 1;
BA_ "GenMsgSendType" BO_ 930 0;
BA_ "GenMsgTimeoutTime" BO_ 930 2500;
BA_ "Period" BO_ 930 10;
BA_ "Type" BO_ 930 0;
BA_ "GenMsgCycleTime" BO_ 980 100;
BA_ "GenMsgILSupport" BO_ 980 1;
BA_ "GenMsgSendType" BO_ 980 0;
BA_ "GenMsgTimeoutTime" BO_ 980 2500;
BA_ "Period" BO_ 980 100;
BA_ "Type" BO_ 980 0;
BA_ "GenMsgCycleTime" BO_ 988 500;
BA_ "GenMsgILSupport" BO_ 988 1;
BA_ "GenMsgSendType" BO_ 988 0;
BA_ "GenMsgTimeoutTime" BO_ 988 2500;
BA_ "Period" BO_ 988 500;
BA_ "Type" BO_ 988 3;
BA_ "GenMsgCycleTime" BO_ 1023 100;
BA_ "GenMsgDelayTime" BO_ 1023 10;
BA_ "GenMsgILSupport" BO_ 1023 1;
BA_ "GenMsgSendType" BO_ 1023 0;
BA_ "GenMsgStartDelayTime" BO_ 1023 10;
BA_ "GenMsgTimeoutTime" BO_ 1023 2500;
BA_ "Period" BO_ 1023 100;
BA_ "Type" BO_ 1023 3;
BA_ "GenMsgCycleTime" BO_ 1058 50;
BA_ "GenMsgILSupport" BO_ 1058 1;
BA_ "GenMsgSendType" BO_ 1058 0;
BA_ "GenMsgTimeoutTime" BO_ 1058 2500;
BA_ "Period" BO_ 1058 50;
BA_ "Type" BO_ 1058 1;
BA_ "GenMsgCycleTime" BO_ 1060 50;
BA_ "GenMsgILSupport" BO_ 1060 1;
BA_ "GenMsgSendType" BO_ 1060 0;
BA_ "GenMsgTimeoutTime" BO_ 1060 2500;
BA_ "Period" BO_ 1060 50;
BA_ "Type" BO_ 1060 1;
BA_ "GenMsgCycleTime" BO_ 1214 500;
BA_ "GenMsgILSupport" BO_ 1214 1;
BA_ "GenMsgSendType" BO_ 1214 0;
BA_ "GenMsgTimeoutTime" BO_ 1214 2500;
BA_ "Period" BO_ 1214 500;
BA_ "Type" BO_ 1214 1;
BA_ "GenMsgCycleTime" BO_ 1261 200;
BA_ "GenMsgILSupport" BO_ 1261 1;
BA_ "GenMsgSendType" BO_ 1261 0;
BA_ "GenMsgTimeoutTime" BO_ 1261 2500;
BA_ "Period" BO_ 1261 200;
BA_ "Type" BO_ 1261 1;
BA_ "GenMsgCycleTime" BO_ 1272 250;
BA_ "GenMsgDelayTime" BO_ 1272 10;
BA_ "GenMsgILSupport" BO_ 1272 1;
BA_ "GenMsgSendType" BO_ 1272 0;
BA_ "GenMsgStartDelayTime" BO_ 1272 10;
BA_ "GenMsgTimeoutTime" BO_ 1272 2500;
BA_ "Period" BO_ 1272 250;
BA_ "Type" BO_ 1272 1;
BA_ "GenMsgCycleTime" BO_ 1273 250;
BA_ "GenMsgDelayTime" BO_ 1273 10;
BA_ "GenMsgILSupport" BO_ 1273 1;
BA_ "GenMsgSendType" BO_ 1273 0;
BA_ "GenMsgStartDelayTime" BO_ 1273 10;
BA_ "GenMsgTimeoutTime" BO_ 1273 2500;
BA_ "Period" BO_ 1273 250;
BA_ "Type" BO_ 1273 1;
BA_ "GenMsgCycleTime" BO_ 1286 100;
BA_ "GenMsgDelayTime" BO_ 1286 10;
BA_ "GenMsgILSupport" BO_ 1286 1;
BA_ "GenMsgSendType" BO_ 1286 0;
BA_ "GenMsgTimeoutTime" BO_ 1286 2500;
BA_ "Period" BO_ 1286 100;
BA_ "Type" BO_ 1286 1;
BA_ "GenMsgCycleTime" BO_ 1312 10;
BA_ "GenMsgDelayTime" BO_ 1312 10;
BA_ "GenMsgILSupport" BO_ 1312 1;
BA_ "GenMsgSendType" BO_ 1312 0;
BA_ "GenMsgStartDelayTime" BO_ 1312 10;
BA_ "GenMsgTimeoutTime" BO_ 1312 2500;
BA_ "Period" BO_ 1312 10;
BA_ "Type" BO_ 1312 0;
BA_ "GenMsgCycleTime" BO_ 1313 100;
BA_ "GenMsgDelayTime" BO_ 1313 10;
BA_ "GenMsgILSupport" BO_ 1313 1;
BA_ "GenMsgSendType" BO_ 1313 0;
BA_ "GenMsgTimeoutTime" BO_ 1313 2500;
BA_ "Period" BO_ 1313 100;
BA_ "Type" BO_ 1313 1;
BA_ "GenMsgCycleTime" BO_ 1314 100;
BA_ "GenMsgILSupport" BO_ 1314 1;
BA_ "GenMsgSendType" BO_ 1314 0;
BA_ "GenMsgTimeoutTime" BO_ 1314 1000;
BA_ "Period" BO_ 1314 100;
BA_ "Type" BO_ 1314 1;
BA_ "GenMsgCycleTime" BO_ 1317 100;
BA_ "GenMsgILSupport" BO_ 1317 1;
BA_ "GenMsgSendType" BO_ 1317 0;
BA_ "GenMsgTimeoutTime" BO_ 1317 2500;
BA_ "Period" BO_ 1317 100;
BA_ "Type" BO_ 1317 0;
BA_ "GenMsgCycleTime" BO_ 1318 20;
BA_ "GenMsgILSupport" BO_ 1318 1;
BA_ "GenMsgSendType" BO_ 1318 0;
BA_ "GenMsgTimeoutTime" BO_ 1318 2500;
BA_ "Period" BO_ 1318 20;
BA_ "Type" BO_ 1318 0;
BA_ "GenMsgCycleTime" BO_ 1323 50;
BA_ "GenMsgILSupport" BO_ 1323 1;
BA_ "GenMsgSendType" BO_ 1323 0;
BA_ "GenMsgTimeoutTime" BO_ 1323 2500;
BA_ "Period" BO_ 1323 50;
BA_ "Type" BO_ 1323 1;
BA_ "GenMsgCycleTime" BO_ 1351 250;
BA_ "GenMsgILSupport" BO_ 1351 1;
BA_ "GenMsgSendType" BO_ 1351 0;
BA_ "GenMsgTimeoutTime" BO_ 1351 2500;
BA_ "Period" BO_ 1351 250;
BA_ "Type" BO_ 1351 3;
BA_ "GenMsgCycleTime" BO_ 1360 100;
BA_ "GenMsgILSupport" BO_ 1360 1;
BA_ "GenMsgSendType" BO_ 1360 0;
BA_ "GenMsgTimeoutTime" BO_ 1360 2500;
BA_ "Period" BO_ 1360 100;
BA_ "Type" BO_ 1360 0;
BA_ "GenMsgCycleTime" BO_ 1376 100;
BA_ "GenMsgDelayTime" BO_ 1376 10;
BA_ "GenMsgILSupport" BO_ 1376 1;
BA_ "GenMsgSendType" BO_ 1376 0;
BA_ "GenMsgStartDelayTime" BO_ 1376 10;
BA_ "GenMsgTimeoutTime" BO_ 1376 2500;
BA_ "Period" BO_ 1376 100;
BA_ "Type" BO_ 1376 1;
BA_ "GenMsgCycleTime" BO_ 1377 50;
BA_ "GenMsgILSupport" BO_ 1377 1;
BA_ "GenMsgSendType" BO_ 1377 0;
BA_ "GenMsgTimeoutTime" BO_ 1377 2500;
BA_ "Period" BO_ 1377 50;
BA_ "Type" BO_ 1377 1;
BA_ "GenMsgCycleTime" BO_ 1382 100;
BA_ "GenMsgILSupport" BO_ 1382 1;
BA_ "GenMsgSendType" BO_ 1382 0;
BA_ "GenMsgTimeoutTime" BO_ 1382 2500;
BA_ "Period" BO_ 1382 100;
BA_ "Type" BO_ 1382 1;
BA_ "GenMsgCycleTime" BO_ 1386 100;
BA_ "GenMsgILSupport" BO_ 1386 1;
BA_ "GenMsgSendType" BO_ 1386 0;
BA_ "GenMsgTimeoutTime" BO_ 1386 2500;
BA_ "Period" BO_ 1386 100;
BA_ "Type" BO_ 1386 1;
BA_ "GenMsgCycleTime" BO_ 1387 100;
BA_ "GenMsgILSupport" BO_ 1387 1;
BA_ "GenMsgSendType" BO_ 1387 0;
BA_ "GenMsgStartDelayTime" BO_ 1387 20;
BA_ "GenMsgTimeoutTime" BO_ 1387 2500;
BA_ "Period" BO_ 1387 100;
BA_ "Type" BO_ 1387 1;
BA_ "GenMsgCycleTime" BO_ 1390 100;
BA_ "GenMsgILSupport" BO_ 1390 1;
BA_ "GenMsgSendType" BO_ 1390 0;
BA_ "GenMsgTimeoutTime" BO_ 1390 2500;
BA_ "Period" BO_ 1390 100;
BA_ "Type" BO_ 1390 1;
BA_ "GenMsgCycleTime" BO_ 1391 500;
BA_ "GenMsgILSupport" BO_ 1391 1;
BA_ "GenMsgSendType" BO_ 1391 0;
BA_ "GenMsgTimeoutTime" BO_ 1391 2500;
BA_ "Period" BO_ 1391 500;
BA_ "Type" BO_ 1391 1;
BA_ "GenMsgCycleTime" BO_ 1394 500;
BA_ "GenMsgILSupport" BO_ 1394 1;
BA_ "GenMsgSendType" BO_ 1394 0;
BA_ "GenMsgTimeoutTime" BO_ 1394 2500;
BA_ "Period" BO_ 1394 500;
BA_ "Type" BO_ 1394 1;
BA_ "GenMsgCycleTime" BO_ 1395 100;
BA_ "GenMsgILSupport" BO_ 1395 1;
BA_ "GenMsgSendType" BO_ 1395 0;
BA_ "GenMsgTimeoutTime" BO_ 1395 2500;
BA_ "Period" BO_ 1395 100;
BA_ "Type" BO_ 1395 1;
BA_ "GenMsgCycleTime" BO_ 1398 250;
BA_ "GenMsgILSupport" BO_ 1398 1;
BA_ "GenMsgSendType" BO_ 1398 0;
BA_ "GenMsgTimeoutTime" BO_ 1398 2500;
BA_ "Period" BO_ 1398 250;
BA_ "Type" BO_ 1398 0;
BA_ "GenMsgCycleTime" BO_ 1403 500;
BA_ "GenMsgILSupport" BO_ 1403 1;
BA_ "GenMsgSendType" BO_ 1403 0;
BA_ "GenMsgTimeoutTime" BO_ 1403 2500;
BA_ "Period" BO_ 1403 500;
BA_ "Type" BO_ 1403 1;
BA_ "GenMsgCycleTime" BO_ 1408 100;
BA_ "GenMsgILSupport" BO_ 1408 1;
BA_ "GenMsgSendType" BO_ 1408 0;
BA_ "GenMsgTimeoutTime" BO_ 1408 2500;
BA_ "Period" BO_ 1408 100;
BA_ "Type" BO_ 1408 1;
BA_ "EventTrans" SG_ 1212 TCU_Replacement_Warning 0;
BA_ "GenSigSendType" SG_ 1212 TCU_Replacement_Warning 3;
BA_ "GenSigSendType" SG_ 2564453105 TPDU_DREQ_ELR 1;
BA_ "EventTrans" SG_ 2564453105 TPDU_DREQ_ELR 0;
BA_ "GenSigSendType" SG_ 2564453361 TPDU_DREQ_ELL 1;
BA_ "EventTrans" SG_ 2564453361 TPDU_DREQ_ELL 0;
BA_ "Accuracy" SG_ 204 LWS_Angle "±2,5°";
BA_ "SignalAge" SG_ 204 LWS_Angle 10;
BA_ "GenSigSendType" SG_ 2564485490 TPDU_DRES_ELR 1;
BA_ "EventTrans" SG_ 2564485490 TPDU_DRES_ELR 0;
BA_ "GenSigSendType" SG_ 2564485491 TPDU_DRES_ELL 1;
BA_ "EventTrans" SG_ 2564485491 TPDU_DRES_ELL 0;
BA_ "EventTrans" SG_ 57 ControlEncoding 0;
BA_ "GenSigSendType" SG_ 57 ControlEncoding 1;
BA_ "EventTrans" SG_ 57 Rnd_1 0;
BA_ "GenSigSendType" SG_ 57 Rnd_1 1;
BA_ "EventTrans" SG_ 57 Rnd_2 0;
BA_ "GenSigSendType" SG_ 57 Rnd_2 1;
BA_ "EventTrans" SG_ 57 Rnd_3 0;
BA_ "GenSigSendType" SG_ 57 Rnd_3 1;
BA_ "EventTrans" SG_ 57 Rnd_4 0;
BA_ "GenSigSendType" SG_ 57 Rnd_4 1;
BA_ "EventTrans" SG_ 57 F1_1 0;
BA_ "GenSigSendType" SG_ 57 F1_1 1;
BA_ "EventTrans" SG_ 57 F1_2 0;
BA_ "GenSigSendType" SG_ 57 F1_2 1;
BA_ "EventTrans" SG_ 64 ControlEncoding 0;
BA_ "GenSigSendType" SG_ 64 ControlEncoding 1;
BA_ "EventTrans" SG_ 64 MKKey_1_or_g2_1 0;
BA_ "GenSigSendType" SG_ 64 MKKey_1_or_g2_1 1;
BA_ "EventTrans" SG_ 64 MKKey_2_or_g2_2 0;
BA_ "GenSigSendType" SG_ 64 MKKey_2_or_g2_2 1;
BA_ "EventTrans" SG_ 64 MKKey_3 0;
BA_ "GenSigSendType" SG_ 64 MKKey_3 1;
BA_ "EventTrans" SG_ 64 MKKey_4 0;
BA_ "GenSigSendType" SG_ 64 MKKey_4 1;
BA_ "EventTrans" SG_ 64 MKKey_5 0;
BA_ "GenSigSendType" SG_ 64 MKKey_5 1;
BA_ "EventTrans" SG_ 64 MKKey_6 0;
BA_ "GenSigSendType" SG_ 64 MKKey_6 1;
BA_ "Accuracy" SG_ 70 ACC_TorqueRequest_NFR "8";
BA_ "GenSigStartValue" SG_ 70 ACC_TorqueRequest_NFR 1000;
BA_ "SignalAge" SG_ 70 ACC_TorqueRequest_NFR 10;
BA_ "Accuracy" SG_ 76 ActiveGearRatio "0,025";
BA_ "SignalAge" SG_ 76 ActiveGearRatio 10;
BA_ "Accuracy" SG_ 76 AMTIndex "1";
BA_ "SignalAge" SG_ 76 AMTIndex 10;
BA_ "Accuracy" SG_ 76 TorquePhaseTime "50";
BA_ "SignalAge" SG_ 76 TorquePhaseTime 50;
BA_ "Accuracy" SG_ 175 CRC "1";
BA_ "SignalAge" SG_ 175 CRC 10;
BA_ "GenSigStartValue" SG_ 175 YRSStat 3;
BA_ "InitialValue" SG_ 175 YRSStat 3;
BA_ "GenSigStartValue" SG_ 175 AYSStat 3;
BA_ "InitialValue" SG_ 175 AYSStat 3;
BA_ "GenSigStartValue" SG_ 175 AXSStat 3;
BA_ "InitialValue" SG_ 175 AXSStat 3;
BA_ "Accuracy" SG_ 175 LongAcceleration "0,02";
BA_ "GenSigStartValue" SG_ 175 LongAcceleration 2048;
BA_ "SignalAge" SG_ 175 LongAcceleration 10;
BA_ "Accuracy" SG_ 175 MessageCounter "1";
BA_ "SignalAge" SG_ 175 MessageCounter 10;
BA_ "Accuracy" SG_ 175 LatAcceleration "0,02";
BA_ "GenSigStartValue" SG_ 175 LatAcceleration 2048;
BA_ "SignalAge" SG_ 175 LatAcceleration 10;
BA_ "Accuracy" SG_ 175 YawRate "0,08";
BA_ "GenSigStartValue" SG_ 175 YawRate 2048;
BA_ "SignalAge" SG_ 175 YawRate 10;
BA_ "Accuracy" SG_ 222 LwsAngle "± 2,8 °";
BA_ "GenSigStartValue" SG_ 222 LwsAngle 7200;
BA_ "SignalAge" SG_ 222 LwsAngle 10;
BA_ "Accuracy" SG_ 222 LwsSpeed "15 °/S";
BA_ "GenSigStartValue" SG_ 222 LwsSpeed 2000;
BA_ "SignalAge" SG_ 222 LwsSpeed 10;
BA_ "SignalAge" SG_ 222 MessageCounter_G 10;
BA_ "Accuracy" SG_ 262 AssistanceTorque "+/- 0,05";
BA_ "GenSigStartValue" SG_ 262 AssistanceTorque 2000;
BA_ "SignalAge" SG_ 262 AssistanceTorque 10;
BA_ "Accuracy" SG_ 262 SteeringColumnTorque "+/- 0,47";
BA_ "GenSigStartValue" SG_ 262 SteeringColumnTorque 1024;
BA_ "SignalAge" SG_ 262 SteeringColumnTorque 10;
BA_ "GenSigStartValue" SG_ 326 Slope 61;
BA_ "GenSigStartValue" SG_ 326 EPBSts 7;
BA_ "InitialValue" SG_ 326 EPBSts 7;
BA_ "Accuracy" SG_ 326 VehicleSpeedVSOSig "± 0,0625km/h";
BA_ "SignalAge" SG_ 326 VehicleSpeedVSOSig 10;
BA_ "GenSigStartValue" SG_ 326 VehicleSpeedVSOSigFailSts 1;
BA_ "InitialValue" SG_ 326 VehicleSpeedVSOSigFailSts 1;
BA_ "Accuracy" SG_ 326 NFR_Speed_FA "± 0,0625km/h";
BA_ "SignalAge" SG_ 326 NFR_Speed_FA 20;
BA_ "GenSigStartValue" SG_ 326 ABSFailPresent 1;
BA_ "InitialValue" SG_ 326 ABSFailPresent 1;
BA_ "GenSigStartValue" SG_ 326 NFR_Speed_FA_FailSts 1;
BA_ "InitialValue" SG_ 326 NFR_Speed_FA_FailSts 1;
BA_ "SignalAge" SG_ 326 NFR_Speed_FA_FailSts 20;
BA_ "GenSigStartValue" SG_ 348 Intervention 1600;
BA_ "Accuracy" SG_ 348 ACC_Engine_Torque "8";
BA_ "GenSigStartValue" SG_ 348 ACC_Engine_Torque 1000;
BA_ "SignalAge" SG_ 348 ACC_Engine_Torque 10;
BA_ "GenSigStartValue" SG_ 348 ACC_AccelerationReq 1600;
BA_ "Accuracy" SG_ 390 EDiffTorqueTarget "+/-10Nm";
BA_ "GenSigStartValue" SG_ 390 EDiffTorqueTarget 125;
BA_ "InitialValue" SG_ 390 EDiffTorqueTarget 1250;
BA_ "SignalAge" SG_ 390 EDiffTorqueTarget 20;
BA_ "GenSigStartValue" SG_ 502 TorqueOverlaySteeringReq_HALF 1024;
BA_ "Accuracy" SG_ 518 VRD_RH "± 0,0625 km/h";
BA_ "SignalAge" SG_ 518 VRD_RH 10;
BA_ "GenSigStartValue" SG_ 518 LH_WheelDirectionSts 3;
BA_ "InitialValue" SG_ 518 LH_WheelDirectionSts 3;
BA_ "GenSigStartValue" SG_ 518 VRD_LHValidData 1;
BA_ "InitialValue" SG_ 518 VRD_LHValidData 1;
BA_ "GenSigStartValue" SG_ 518 RH_WheelDirectionSts 3;
BA_ "InitialValue" SG_ 518 RH_WheelDirectionSts 3;
BA_ "GenSigStartValue" SG_ 518 VRD_RHValidData 1;
BA_ "InitialValue" SG_ 518 VRD_RHValidData 1;
BA_ "Accuracy" SG_ 518 VRD_LH "± 0,0625 km/h";
BA_ "SignalAge" SG_ 518 VRD_LH 10;
BA_ "GenSigStartValue" SG_ 524 Slope 61;
BA_ "GenSigStartValue" SG_ 524 EPBSts 7;
BA_ "InitialValue" SG_ 524 EPBSts 7;
BA_ "Accuracy" SG_ 524 VehicleSpeedVSOSig "± 0,0625km/h";
BA_ "SignalAge" SG_ 524 VehicleSpeedVSOSig 10;
BA_ "GenSigStartValue" SG_ 524 VehicleSpeedVSOSigFailSts 1;
BA_ "InitialValue" SG_ 524 VehicleSpeedVSOSigFailSts 1;
BA_ "Accuracy" SG_ 524 NFR_Speed_FA "± 0,0625km/h";
BA_ "SignalAge" SG_ 524 NFR_Speed_FA 20;
BA_ "GenSigStartValue" SG_ 524 ABSFailPresent 1;
BA_ "InitialValue" SG_ 524 ABSFailPresent 1;
BA_ "GenSigStartValue" SG_ 524 NFR_Speed_FA_FailSts 1;
BA_ "InitialValue" SG_ 524 NFR_Speed_FA_FailSts 1;
BA_ "SignalAge" SG_ 524 NFR_Speed_FA_FailSts 20;
BA_ "Accuracy" SG_ 550 VRD_RV "± 0,0625 km/h";
BA_ "SignalAge" SG_ 550 VRD_RV 10;
BA_ "GenSigStartValue" SG_ 550 LV_WheelDirectionSts 3;
BA_ "InitialValue" SG_ 550 LV_WheelDirectionSts 3;
BA_ "GenSigStartValue" SG_ 550 VRD_LVValidData 1;
BA_ "InitialValue" SG_ 550 VRD_LVValidData 1;
BA_ "GenSigStartValue" SG_ 550 RV_WheelDirectionSts 3;
BA_ "InitialValue" SG_ 550 RV_WheelDirectionSts 3;
BA_ "GenSigStartValue" SG_ 550 VRD_RVValidData 1;
BA_ "InitialValue" SG_ 550 VRD_RVValidData 1;
BA_ "Accuracy" SG_ 550 VRD_LV "± 0,0625 km/h";
BA_ "SignalAge" SG_ 550 VRD_LV 10;
BA_ "EventTrans" SG_ 599 AirBagWarningPABLabelSts 0;
BA_ "GenSigSendType" SG_ 599 AirBagWarningPABLabelSts 3;
BA_ "EventTrans" SG_ 599 SBR2RowCentralSeatBuckleFailSts 0;
BA_ "GenSigSendType" SG_ 599 SBR2RowCentralSeatBuckleFailSts 3;
BA_ "GenSigStartValue" SG_ 599 SBR2RowCentralSeatBuckleFailSts 3;
BA_ "InitialValue" SG_ 599 SBR2RowCentralSeatBuckleFailSts 3;
BA_ "EventTrans" SG_ 599 SBR2RowCentralSeatConfigSts 0;
BA_ "GenSigSendType" SG_ 599 SBR2RowCentralSeatConfigSts 3;
BA_ "EventTrans" SG_ 599 AirBagFailSts 0;
BA_ "GenSigSendType" SG_ 599 AirBagFailSts 3;
BA_ "GenSigStartValue" SG_ 599 AirBagFailSts 2;
BA_ "InitialValue" SG_ 599 AirBagFailSts 2;
BA_ "EventTrans" SG_ 599 SBR1RowDriverSeatFailSts 0;
BA_ "GenSigSendType" SG_ 599 SBR1RowDriverSeatFailSts 3;
BA_ "GenSigStartValue" SG_ 599 SBR1RowDriverSeatFailSts 3;
BA_ "InitialValue" SG_ 599 SBR1RowDriverSeatFailSts 3;
BA_ "EventTrans" SG_ 599 SBR1RowDriverSeatConfigSts 0;
BA_ "GenSigSendType" SG_ 599 SBR1RowDriverSeatConfigSts 3;
BA_ "EventTrans" SG_ 599 SBR2RowCentralSeatSts 0;
BA_ "GenSigSendType" SG_ 599 SBR2RowCentralSeatSts 3;
BA_ "GenSigStartValue" SG_ 599 SBR2RowCentralSeatSts 7;
BA_ "InitialValue" SG_ 599 SBR2RowCentralSeatSts 7;
BA_ "EventTrans" SG_ 599 SBR1RowCentralSeatPPDFailSts 0;
BA_ "GenSigSendType" SG_ 599 SBR1RowCentralSeatPPDFailSts 3;
BA_ "GenSigStartValue" SG_ 599 SBR1RowCentralSeatPPDFailSts 3;
BA_ "InitialValue" SG_ 599 SBR1RowCentralSeatPPDFailSts 3;
BA_ "EventTrans" SG_ 599 SBR1RowPsngrSeatPPDFailSts 0;
BA_ "GenSigSendType" SG_ 599 SBR1RowPsngrSeatPPDFailSts 3;
BA_ "GenSigStartValue" SG_ 599 SBR1RowPsngrSeatPPDFailSts 3;
BA_ "InitialValue" SG_ 599 SBR1RowPsngrSeatPPDFailSts 3;
BA_ "EventTrans" SG_ 599 SBR1RowPsngrSeatBuckleFailSts 0;
BA_ "GenSigSendType" SG_ 599 SBR1RowPsngrSeatBuckleFailSts 3;
BA_ "GenSigStartValue" SG_ 599 SBR1RowPsngrSeatBuckleFailSts 3;
BA_ "InitialValue" SG_ 599 SBR1RowPsngrSeatBuckleFailSts 3;
BA_ "EventTrans" SG_ 599 SBR1RowPsngrSeatConfigSts 0;
BA_ "GenSigSendType" SG_ 599 SBR1RowPsngrSeatConfigSts 3;
BA_ "EventTrans" SG_ 599 SBR1RowDriverSeatSts 0;
BA_ "GenSigSendType" SG_ 599 SBR1RowDriverSeatSts 3;
BA_ "GenSigStartValue" SG_ 599 SBR1RowDriverSeatSts 3;
BA_ "InitialValue" SG_ 599 SBR1RowDriverSeatSts 3;
BA_ "EventTrans" SG_ 599 SBR2RowLeftSeatSts 0;
BA_ "GenSigSendType" SG_ 599 SBR2RowLeftSeatSts 3;
BA_ "GenSigStartValue" SG_ 599 SBR2RowLeftSeatSts 3;
BA_ "InitialValue" SG_ 599 SBR2RowLeftSeatSts 3;
BA_ "EventTrans" SG_ 599 SBR2RowRightSeatFailSts 0;
BA_ "GenSigSendType" SG_ 599 SBR2RowRightSeatFailSts 3;
BA_ "GenSigStartValue" SG_ 599 SBR2RowRightSeatFailSts 3;
BA_ "InitialValue" SG_ 599 SBR2RowRightSeatFailSts 3;
BA_ "EventTrans" SG_ 599 SBR2RowLeftSeatFailSts 0;
BA_ "GenSigSendType" SG_ 599 SBR2RowLeftSeatFailSts 3;
BA_ "GenSigStartValue" SG_ 599 SBR2RowLeftSeatFailSts 3;
BA_ "InitialValue" SG_ 599 SBR2RowLeftSeatFailSts 3;
BA_ "EventTrans" SG_ 599 SBR1RowPsngrSeatSts 0;
BA_ "GenSigSendType" SG_ 599 SBR1RowPsngrSeatSts 3;
BA_ "GenSigStartValue" SG_ 599 SBR1RowPsngrSeatSts 7;
BA_ "InitialValue" SG_ 599 SBR1RowPsngrSeatSts 7;
BA_ "EventTrans" SG_ 599 CrashOutputSts 0;
BA_ "GenSigSendType" SG_ 599 CrashOutputSts 3;
BA_ "EventTrans" SG_ 599 SBR2RowRightSeatSts 0;
BA_ "GenSigSendType" SG_ 599 SBR2RowRightSeatSts 3;
BA_ "GenSigStartValue" SG_ 599 SBR2RowRightSeatSts 3;
BA_ "InitialValue" SG_ 599 SBR2RowRightSeatSts 3;
BA_ "SignalAge" SG_ 599 MessageCounterNAB1 10;
BA_ "EventTrans" SG_ 599 CrashOutputValidData 0;
BA_ "GenSigSendType" SG_ 599 CrashOutputValidData 3;
BA_ "SignalAge" SG_ 599 ChecksumNAB1 10;
BA_ "EventTrans" SG_ 599 AirBagWarningPADLampOnSts 0;
BA_ "GenSigSendType" SG_ 599 AirBagWarningPADLampOnSts 3;
BA_ "EventTrans" SG_ 599 AirBagWarningPADLampOffSts 0;
BA_ "GenSigSendType" SG_ 599 AirBagWarningPADLampOffSts 3;
BA_ "EventTrans" SG_ 599 SBR2RowRightSeatConfigSts 0;
BA_ "GenSigSendType" SG_ 599 SBR2RowRightSeatConfigSts 3;
BA_ "EventTrans" SG_ 599 SBR2RowLeftSeatConfigSts 0;
BA_ "GenSigSendType" SG_ 599 SBR2RowLeftSeatConfigSts 3;
BA_ "EventTrans" SG_ 599 Ppd_psngr_info 0;
BA_ "GenSigSendType" SG_ 599 Ppd_psngr_info 3;
BA_ "EventTrans" SG_ 599 AirBagWarningLampSts 0;
BA_ "GenSigSendType" SG_ 599 AirBagWarningLampSts 3;
BA_ "InitialValue" SG_ 865 VehDriverReqTrq -508;
BA_ "GenSigStartValue" SG_ 865 EngineSpeedValidData 1;
BA_ "InitialValue" SG_ 865 EngineSpeedValidData 1;
BA_ "Accuracy" SG_ 865 EngineSpeed "± 1/min";
BA_ "Accuracy" SG_ 865 GasPedalPosition "± 0,392%";
BA_ "SignalAge" SG_ 865 GasPedalPosition 10;
BA_ "EventTrans" SG_ 870 Buzzer4A 0;
BA_ "GenSigSendType" SG_ 870 Buzzer4A 3;
BA_ "EventTrans" SG_ 870 Buzzer3A 0;
BA_ "GenSigSendType" SG_ 870 Buzzer3A 3;
BA_ "EventTrans" SG_ 870 Buzzer2A 0;
BA_ "GenSigSendType" SG_ 870 Buzzer2A 3;
BA_ "EventTrans" SG_ 870 Buzzer1A 0;
BA_ "GenSigSendType" SG_ 870 Buzzer1A 3;
BA_ "EventTrans" SG_ 870 BuzzerVolumeWarning 0;
BA_ "GenSigSendType" SG_ 870 BuzzerVolumeWarning 3;
BA_ "GenSigStartValue" SG_ 870 BuzzerVolumeWarning 4;
BA_ "InitialValue" SG_ 870 BuzzerVolumeWarning 4;
BA_ "EventTrans" SG_ 870 BuzzerACC_prox 0;
BA_ "GenSigSendType" SG_ 870 BuzzerACC_prox 3;
BA_ "EventTrans" SG_ 870 Buzzer2A_Backrest 0;
BA_ "GenSigSendType" SG_ 870 Buzzer2A_Backrest 3;
BA_ "EventTrans" SG_ 870 StartButtonSound 0;
BA_ "GenSigSendType" SG_ 870 StartButtonSound 3;
BA_ "EventTrans" SG_ 870 BuzzerSpeed_Alert 0;
BA_ "GenSigSendType" SG_ 870 BuzzerSpeed_Alert 3;
BA_ "EventTrans" SG_ 870 Buzzer3D 0;
BA_ "GenSigSendType" SG_ 870 Buzzer3D 3;
BA_ "EventTrans" SG_ 870 Buzzer3C 0;
BA_ "GenSigSendType" SG_ 870 Buzzer3C 3;
BA_ "EventTrans" SG_ 870 Buzzer2C 0;
BA_ "GenSigSendType" SG_ 870 Buzzer2C 3;
BA_ "EventTrans" SG_ 870 Buzzer2B 0;
BA_ "GenSigSendType" SG_ 870 Buzzer2B 3;
BA_ "EventTrans" SG_ 870 Buzzer2B_DDA 0;
BA_ "GenSigSendType" SG_ 870 Buzzer2B_DDA 3;
BA_ "EventTrans" SG_ 870 VolumeAdjustable 0;
BA_ "GenSigSendType" SG_ 870 VolumeAdjustable 3;
BA_ "EventTrans" SG_ 870 NQSIsPlaying 0;
BA_ "GenSigSendType" SG_ 870 NQSIsPlaying 3;
BA_ "Accuracy" SG_ 929 MaxEngineTorque "4";
BA_ "InitialValue" SG_ 929 MaxEngineTorque -508;
BA_ "SignalAge" SG_ 929 MaxEngineTorque 10;
BA_ "Accuracy" SG_ 929 EngineTorqueDriverReq "4";
BA_ "InitialValue" SG_ 929 EngineTorqueDriverReq -508;
BA_ "SignalAge" SG_ 929 EngineTorqueDriverReq 10;
BA_ "InitialValue" SG_ 929 MaxCrankTorque 60;
BA_ "GenSigStartValue" SG_ 929 TotalFrontAxleTorque_V3 254;
BA_ "Accuracy" SG_ 929 EngineTorque "4";
BA_ "InitialValue" SG_ 929 EngineTorque -508;
BA_ "SignalAge" SG_ 929 EngineTorque 10;
BA_ "Accuracy" SG_ 930 MinEngineTorque_ACC "4";
BA_ "InitialValue" SG_ 930 MinEngineTorque_ACC -508;
BA_ "SignalAge" SG_ 930 MinEngineTorque_ACC 10;
BA_ "Accuracy" SG_ 930 MaxEngineTorque_ACC "4";
BA_ "InitialValue" SG_ 930 MaxEngineTorque_ACC -508;
BA_ "SignalAge" SG_ 930 MaxEngineTorque_ACC 10;
BA_ "Accuracy" SG_ 930 EngineSpeedHiRes "1";
BA_ "SignalAge" SG_ 930 EngineSpeedHiRes 10;
BA_ "EventTrans" SG_ 980 HManettinoDriverWish 0;
BA_ "GenSigSendType" SG_ 980 HManettinoDriverWish 3;
BA_ "EventTrans" SG_ 980 ManettinoSuspensionSts 0;
BA_ "GenSigSendType" SG_ 980 ManettinoSuspensionSts 3;
BA_ "EventTrans" SG_ 980 ESPChangeModeReqSts 0;
BA_ "GenSigSendType" SG_ 980 ESPChangeModeReqSts 3;
BA_ "EventTrans" SG_ 980 ManettinoFailSts 0;
BA_ "GenSigSendType" SG_ 980 ManettinoFailSts 3;
BA_ "EventTrans" SG_ 980 ManettinoSts 0;
BA_ "GenSigSendType" SG_ 980 ManettinoSts 3;
BA_ "EventTrans" SG_ 980 FrontWindshieldWiperSwitchSts 0;
BA_ "GenSigSendType" SG_ 980 FrontWindshieldWiperSwitchSts 3;
BA_ "EventTrans" SG_ 980 LdirectionSwitchSts_NVO_INFO 0;
BA_ "GenSigSendType" SG_ 980 LdirectionSwitchSts_NVO_INFO 3;
BA_ "EventTrans" SG_ 980 RdirectionSwitchSts_NVO_INFO 0;
BA_ "GenSigSendType" SG_ 980 RdirectionSwitchSts_NVO_INFO 3;
BA_ "EventTrans" SG_ 980 LChangeLaneSts_NVO_INFO 0;
BA_ "GenSigSendType" SG_ 980 LChangeLaneSts_NVO_INFO 3;
BA_ "EventTrans" SG_ 980 RChangeLaneSts_NVO_INFO 0;
BA_ "GenSigSendType" SG_ 980 RChangeLaneSts_NVO_INFO 3;
BA_ "EventTrans" SG_ 980 ADAS_OnOffSts 0;
BA_ "GenSigSendType" SG_ 980 ADAS_OnOffSts 3;
BA_ "EventTrans" SG_ 980 FrontWindshieldWasherSwitchSts 0;
BA_ "GenSigSendType" SG_ 980 FrontWindshieldWasherSwitchSts 3;
BA_ "EventTrans" SG_ 988 TyrePressureSystemSts 0;
BA_ "GenSigSendType" SG_ 988 TyrePressureSystemSts 3;
BA_ "EventTrans" SG_ 988 TyrePressureSystemFailSts 0;
BA_ "GenSigSendType" SG_ 988 TyrePressureSystemFailSts 3;
BA_ "EventTrans" SG_ 988 TyrePressureSysCalibrationSts 0;
BA_ "GenSigSendType" SG_ 988 TyrePressureSysCalibrationSts 3;
BA_ "EventTrans" SG_ 988 NTPTempNotActiveSts 0;
BA_ "GenSigSendType" SG_ 988 NTPTempNotActiveSts 3;
BA_ "EventTrans" SG_ 988 NTPCalibrationReqACK 0;
BA_ "GenSigSendType" SG_ 988 NTPCalibrationReqACK 3;
BA_ "Accuracy" SG_ 988 TemperatureSts_xx "Tbd";
BA_ "InitialValue" SG_ 988 TemperatureSts_xx -40;
BA_ "EventTrans" SG_ 988 TPMSTelltaleSts 0;
BA_ "GenSigSendType" SG_ 988 TPMSTelltaleSts 3;
BA_ "Accuracy" SG_ 988 LHFPressureSts "0,075 bar";
BA_ "Accuracy" SG_ 988 RHFPressureSts "0,075 bar";
BA_ "Accuracy" SG_ 988 LHRPressureSts "0,075 bar";
BA_ "Accuracy" SG_ 988 RHRPressureSts "0,075 bar";
BA_ "EventTrans" SG_ 1023 HBActivation 0;
BA_ "GenSigSendType" SG_ 1023 HBActivation 3;
BA_ "EventTrans" SG_ 1023 LBActivation 0;
BA_ "GenSigSendType" SG_ 1023 LBActivation 3;
BA_ "EventTrans" SG_ 1023 ParkingLightCmd 0;
BA_ "GenSigSendType" SG_ 1023 ParkingLightCmd 3;
BA_ "EventTrans" SG_ 1023 LeftPL 0;
BA_ "GenSigSendType" SG_ 1023 LeftPL 3;
BA_ "EventTrans" SG_ 1023 RightPL 0;
BA_ "GenSigSendType" SG_ 1023 RightPL 3;
BA_ "EventTrans" SG_ 1023 LeftDRL 0;
BA_ "GenSigSendType" SG_ 1023 LeftDRL 3;
BA_ "EventTrans" SG_ 1023 RightDRL 0;
BA_ "GenSigSendType" SG_ 1023 RightDRL 3;
BA_ "EventTrans" SG_ 1023 AHB_Memory 0;
BA_ "GenSigSendType" SG_ 1023 AHB_Memory 3;
BA_ "EventTrans" SG_ 1023 FBL_Activation 0;
BA_ "GenSigSendType" SG_ 1023 FBL_Activation 3;
BA_ "EventTrans" SG_ 1023 TrafficChangeEnable 0;
BA_ "GenSigSendType" SG_ 1023 TrafficChangeEnable 3;
BA_ "EventTrans" SG_ 1023 AFSReq 0;
BA_ "GenSigSendType" SG_ 1023 AFSReq 3;
BA_ "EventTrans" SG_ 1023 FrontWindshieldWiperSts 0;
BA_ "GenSigSendType" SG_ 1023 FrontWindshieldWiperSts 3;
BA_ "EventTrans" SG_ 1023 FrontWindshieldWasherSts 0;
BA_ "GenSigSendType" SG_ 1023 FrontWindshieldWasherSts 3;
BA_ "EventTrans" SG_ 1023 AHBFeature 0;
BA_ "GenSigSendType" SG_ 1023 AHBFeature 3;
BA_ "EventTrans" SG_ 1023 AHB_ON 0;
BA_ "GenSigSendType" SG_ 1023 AHB_ON 3;
BA_ "InitialValue" SG_ 1058 OBC_Temperature -40;
BA_ "InitialValue" SG_ 1214 LVB_MaxCellsTemp -45;
BA_ "GenSigStartValue" SG_ 1214 LVB_SOH 127;
BA_ "InitialValue" SG_ 1214 LVB_SOH 127;
BA_ "GenSigStartValue" SG_ 1214 LVB_Relay_Status 3;
BA_ "InitialValue" SG_ 1214 LVB_Relay_Status 3;
BA_ "GenSigStartValue" SG_ 1286 PBDisplayInfoValidData 1;
BA_ "InitialValue" SG_ 1286 PBDisplayInfoValidData 1;
BA_ "GenSigStartValue" SG_ 1286 EPBDisplayEnable 2;
BA_ "InitialValue" SG_ 1286 EPBDisplayEnable 2;
BA_ "GenSigStartValue" SG_ 1312 ADAS_heater 1;
BA_ "InitialValue" SG_ 1312 ADAS_heater 1;
BA_ "EventTrans" SG_ 1312 NBCFISSts 0;
BA_ "GenSigSendType" SG_ 1312 NBCFISSts 3;
BA_ "EventTrans" SG_ 1312 AHBFeature 0;
BA_ "GenSigSendType" SG_ 1312 AHBFeature 3;
BA_ "EventTrans" SG_ 1312 HighBeamSts_VEHSTAT 0;
BA_ "GenSigSendType" SG_ 1312 HighBeamSts_VEHSTAT 3;
BA_ "SignalAge" SG_ 1313 STS_DRS_Checksum 10;
BA_ "InitialValue" SG_ 1314 RefrigerantFluidTemp1 -20;
BA_ "InitialValue" SG_ 1314 RefrigerantFluidTemp2 -20;
BA_ "GenSigStartValue" SG_ 1317 SetSpeed 255;
BA_ "InitialValue" SG_ 1317 SetSpeed 7140;
BA_ "GenSigStartValue" SG_ 1317 ActualSpeed 255;
BA_ "InitialValue" SG_ 1317 ActualSpeed 7140;
BA_ "GenSigStartValue" SG_ 1317 Temperature 205;
BA_ "InitialValue" SG_ 1317 Temperature 155;
BA_ "GenSigStartValue" SG_ 1317 Current 51;
BA_ "InitialValue" SG_ 1317 Current 10;
BA_ "GenSigStartValue" SG_ 1317 OverTemperature 3;
BA_ "InitialValue" SG_ 1317 OverTemperature 3;
BA_ "GenSigStartValue" SG_ 1317 Stepmode 3;
BA_ "InitialValue" SG_ 1317 Stepmode 3;
BA_ "GenSigStartValue" SG_ 1317 Deblocking 3;
BA_ "InitialValue" SG_ 1317 Deblocking 3;
BA_ "GenSigStartValue" SG_ 1317 VoltageError 3;
BA_ "InitialValue" SG_ 1317 VoltageError 3;
BA_ "GenSigStartValue" SG_ 1317 DryRun 3;
BA_ "InitialValue" SG_ 1317 DryRun 3;
BA_ "GenSigStartValue" SG_ 1317 OverCurrent 3;
BA_ "InitialValue" SG_ 1317 OverCurrent 3;
BA_ "GenSigStartValue" SG_ 1317 StatusPostRunningMode 3;
BA_ "InitialValue" SG_ 1317 StatusPostRunningMode 3;
BA_ "Accuracy" SG_ 1318 BrakePressureTarget "± 5 bar";
BA_ "SignalAge" SG_ 1318 BrakePressureTarget 7;
BA_ "Accuracy" SG_ 1318 DriverBrkPressureRqt "± 5 bar";
BA_ "SignalAge" SG_ 1318 DriverBrkPressureRqt 7;
BA_ "Accuracy" SG_ 1318 BrakePressureActual "± 5 bar";
BA_ "SignalAge" SG_ 1318 BrakePressureActual 7;
BA_ "EventTrans" SG_ 1351 HALF_CHIME_TYPESts 0;
BA_ "GenSigSendType" SG_ 1351 HALF_CHIME_TYPESts 3;
BA_ "EventTrans" SG_ 1351 TSR_Fault 0;
BA_ "GenSigSendType" SG_ 1351 TSR_Fault 3;
BA_ "EventTrans" SG_ 1351 TSR_ON 0;
BA_ "GenSigSendType" SG_ 1351 TSR_ON 3;
BA_ "EventTrans" SG_ 1351 LDWSystemSts 0;
BA_ "GenSigSendType" SG_ 1351 LDWSystemSts 3;
BA_ "GenSigStartValue" SG_ 1351 LDWSystemSts 2;
BA_ "InitialValue" SG_ 1351 LDWSystemSts 2;
BA_ "GenSigStartValue" SG_ 1351 StatusLKA 3;
BA_ "InitialValue" SG_ 1351 StatusLKA 3;
BA_ "GenSigStartValue" SG_ 1351 AHBSensitivitySts 1;
BA_ "InitialValue" SG_ 1351 AHBSensitivitySts 1;
BA_ "GenSigStartValue" SG_ 1351 LDWSensitivitySts 3;
BA_ "InitialValue" SG_ 1351 LDWSensitivitySts 3;
BA_ "EventTrans" SG_ 1351 HALF_RF_CHIME_RQSts 0;
BA_ "GenSigSendType" SG_ 1351 HALF_RF_CHIME_RQSts 3;
BA_ "EventTrans" SG_ 1351 HALF_LF_CHIME_RQSts 0;
BA_ "GenSigSendType" SG_ 1351 HALF_LF_CHIME_RQSts 3;
BA_ "EventTrans" SG_ 1351 HandsOnSts 0;
BA_ "GenSigSendType" SG_ 1351 HandsOnSts 3;
BA_ "GenSigStartValue" SG_ 1351 HandsOnSts 6;
BA_ "InitialValue" SG_ 1351 HandsOnSts 6;
BA_ "GenSigStartValue" SG_ 1351 LDW_Intensity_fbk 3;
BA_ "InitialValue" SG_ 1351 LDW_Intensity_fbk 3;
BA_ "GenSigStartValue" SG_ 1351 DrowsinessSts 3;
BA_ "InitialValue" SG_ 1351 DrowsinessSts 3;
BA_ "GenSigStartValue" SG_ 1351 LDWWarningType_fbk 3;
BA_ "InitialValue" SG_ 1351 LDWWarningType_fbk 3;
BA_ "EventTrans" SG_ 1351 DisplaySts 0;
BA_ "GenSigSendType" SG_ 1351 DisplaySts 3;
BA_ "EventTrans" SG_ 1351 SensorBlinded 0;
BA_ "GenSigSendType" SG_ 1351 SensorBlinded 3;
BA_ "EventTrans" SG_ 1351 AHBFault 0;
BA_ "GenSigSendType" SG_ 1351 AHBFault 3;
BA_ "EventTrans" SG_ 1351 AHB_ON 0;
BA_ "GenSigSendType" SG_ 1351 AHB_ON 3;
BA_ "EventTrans" SG_ 1351 TSR_Sts 0;
BA_ "GenSigSendType" SG_ 1351 TSR_Sts 3;
BA_ "EventTrans" SG_ 1351 HALF_heaterSts 0;
BA_ "GenSigSendType" SG_ 1351 HALF_heaterSts 3;
BA_ "EventTrans" SG_ 1376 VDCLamp_FailSts 0;
BA_ "GenSigSendType" SG_ 1376 VDCLamp_FailSts 3;
BA_ "EventTrans" SG_ 1376 TC_ASRLamp_FailSts 0;
BA_ "GenSigSendType" SG_ 1376 TC_ASRLamp_FailSts 3;
BA_ "EventTrans" SG_ 1376 EBDLamp_FailSts 0;
BA_ "GenSigSendType" SG_ 1376 EBDLamp_FailSts 3;
BA_ "EventTrans" SG_ 1376 ABSLamp_FailSts 0;
BA_ "GenSigSendType" SG_ 1376 ABSLamp_FailSts 3;
BA_ "EventTrans" SG_ 1376 LifterButtonValidData 0;
BA_ "GenSigSendType" SG_ 1376 LifterButtonValidData 3;
BA_ "EventTrans" SG_ 1376 ReverseGearBCSts 0;
BA_ "GenSigSendType" SG_ 1376 ReverseGearBCSts 3;
BA_ "EventTrans" SG_ 1376 LifterButtonSts 0;
BA_ "GenSigSendType" SG_ 1376 LifterButtonSts 3;
BA_ "EventTrans" SG_ 1376 BackWindowSts 0;
BA_ "GenSigSendType" SG_ 1376 BackWindowSts 3;
BA_ "GenSigStartValue" SG_ 1376 BackWindowSts 2;
BA_ "InitialValue" SG_ 1376 BackWindowSts 2;
BA_ "EventTrans" SG_ 1376 DriverDoorSts 0;
BA_ "GenSigSendType" SG_ 1376 DriverDoorSts 3;
BA_ "EventTrans" SG_ 1376 KeySts 0;
BA_ "GenSigSendType" SG_ 1376 KeySts 3;
BA_ "Accuracy" SG_ 1376 ExternalTemperature "0,5 °C (-10 °C / +20°C)";
BA_ "GenSigStartValue" SG_ 1376 ExternalTemperature 1;
BA_ "InitialValue" SG_ 1376 ExternalTemperature -39;
BA_ "SignalAge" SG_ 1376 ExternalTemperature 50;
BA_ "GenSigInactiveValue" SG_ 1376 RawNourriceLevel 1;
BA_ "GenSigInactiveValue" SG_ 1376 LowNourriceLevel 1;
BA_ "GenSigStartValue" SG_ 1376 RemoteDoorUnlock 1;
BA_ "InitialValue" SG_ 1376 RemoteDoorUnlock 1;
BA_ "Accuracy" SG_ 1376 FuelLevelRawValue "±2,5 at17,5%";
BA_ "SignalAge" SG_ 1376 FuelLevelRawValue 250;
BA_ "EventTrans" SG_ 1376 NTPCalibrationReqSts 0;
BA_ "GenSigSendType" SG_ 1376 NTPCalibrationReqSts 3;
BA_ "GenSigStartValue" SG_ 1377 OilPressureSts 1;
BA_ "InitialValue" SG_ 1377 OilPressureSts 1;
BA_ "GenSigStartValue" SG_ 1377 EMSFailSts 2;
BA_ "InitialValue" SG_ 1377 EMSFailSts 2;
BA_ "GenSigStartValue" SG_ 1377 CompressorSts 2;
BA_ "InitialValue" SG_ 1377 CompressorSts 2;
BA_ "Accuracy" SG_ 1377 EngineWaterTemp "± 2 °C at 120 °C";
BA_ "InitialValue" SG_ 1377 EngineWaterTemp -40;
BA_ "SignalAge" SG_ 1377 EngineWaterTemp 130;
BA_ "Accuracy" SG_ 1377 FuelConsumption "± 5%";
BA_ "SignalAge" SG_ 1377 FuelConsumption 50;
BA_ "Accuracy" SG_ 1377 EngineSpeed "± 1 rpm";
BA_ "SignalAge" SG_ 1377 EngineSpeed 35;
BA_ "GenSigStartValue" SG_ 1377 EngineSpeedValidData 1;
BA_ "GenSigStartValue" SG_ 1382 AutoEPBEnable 1;
BA_ "InitialValue" SG_ 1382 AutoEPBEnable 1;
BA_ "Accuracy" SG_ 1382 OversteerTendency "3,333%";
BA_ "SignalAge" SG_ 1382 OversteerTendency 20;
BA_ "GenSigStartValue" SG_ 1387 ShiftModeSts 1;
BA_ "InitialValue" SG_ 1387 ShiftModeSts 1;
BA_ "GenSigStartValue" SG_ 1387 AutomaticRoboticXmsnDegradedMode 1;
BA_ "InitialValue" SG_ 1387 AutomaticRoboticXmsnDegradedMode 1;
BA_ "InitialValue" SG_ 1390 MinimumCellsTemperature -40;
BA_ "InitialValue" SG_ 1390 MaximumCellsTemperature -40;
BA_ "InitialValue" SG_ 1390 InletWaterTemperature -25;
BA_ "InitialValue" SG_ 1390 OutletWaterTemperature -25;
BA_ "SignalAge" SG_ 1398 RWSInternalSts 10;
BA_ "GenSigStartValue" SG_ 1403 NCSSetupSts 1;
BA_ "InitialValue" SG_ 1403 NCSSetupSts 1;
VAL_ 1722 TCUModemSts 5 "_5G" 4 "_4G" 3 "_3G" 2 "_2G" 1 "Searching" 0 "Off" ;
VAL_ 1722 SignalStrength 4 "Best" 3 "Good" 2 "Average" 1 "Bad" 0 "Not_Connected" ;
VAL_ 1722 TCUFailSts 1 "Fail_Present" 0 "Fail_Not_Present" ;
VAL_ 1722 PowerModeSts_TCU 3 "Not_used" 2 "Not_used" 1 "Logistic_Mode_ON" 0 "Standard_Power" ;
VAL_ 2654208005 WakeRsn_TCU 0 "'Diag'" 1 "'Network'" 2 "'High_DC_Voltage'" 3 "'WakeRsn3'" 4 "'WakeRsn4'" 5 "'WakeRsn5'" 6 "'WakeRsn6'" 7 "'WakeRsn7'" 8 "'WakeRsn8'" 9 "'WakeRsn9'" 10 "'WakeRsn10'" 11 "'WakeRsn11'" 12 "'WakeRsn12'" 13 "'WakeRsn13'" 14 "'WakeRsn14'" 15 "'WakeRsn15'" 16 "'WakeRsn16'" 17 "'WakeRsn17'" 18 "'WakeRsn18'" 19 "'WakeRsn19'" 20 "'WakeRsn20'" 21 "'WakeRsn21'" 22 "'WakeRsn22'" 23 "'WakeRsn23'" 24 "'WakeRsn24'" 25 "'WakeRsn25'" 26 "'WakeRsn26'" 27 "'WakeRsn27'" 28 "'WakeRsn28'" 29 "'WakeRsn29'" 30 "'WakeRsn30'" 31 "'WakeRsn31'" 32 "'WakeRsn32'" 33 "'WakeRsn33'" 34 "'WakeRsn34'" 35 "'WakeRsn35'" 36 "'WakeRsn36'" 37 "'WakeRsn37'" 38 "'WakeRsn38'" 39 "'WakeRsn39'" 40 "'WakeRsn40'" 41 "'WakeRsn41'" 42 "'WakeRsn42'" 43 "'WakeRsn43'" 44 "'WakeRsn44'" 45 "'WakeRsn45'" 46 "'WakeRsn46'" 47 "'WakeRsn47'" 48 "'WakeRsn48'" 49 "'WakeRsn49'" 50 "'WakeRsn50'" 51 "'WakeRsn51'" 52 "'WakeRsn52'" 53 "'WakeRsn53'" 54 "'WakeRsn54'" 55 "'WakeRsn55'" 56 "'WakeRsn56'" 57 "'WakeRsn57'" 58 "'WakeRsn58'" 59 "'WakeRsn59'" 60 "'WakeRsn60'" 61 "'WakeRsn61'" 62 "'WakeRsn62'" 63 "'WakeRsn63'" 64 "'WakeRsn64'" 65 "'WakeRsn65'" 66 "'WakeRsn66'" 67 "'WakeRsn67'" 68 "'WakeRsn68'" 69 "'WakeRsn69'" 70 "'WakeRsn70'" 71 "'WakeRsn71'" 72 "'WakeRsn72'" 73 "'WakeRsn73'" 74 "'WakeRsn74'" 75 "'WakeRsn75'" 76 "'WakeRsn76'" 77 "'WakeRsn77'" 78 "'WakeRsn78'" 79 "'WakeRsn79'" 80 "'WakeRsn80'" 81 "'WakeRsn81'" 82 "'WakeRsn82'" 83 "'WakeRsn83'" 84 "'WakeRsn84'" 85 "'WakeRsn85'" 86 "'WakeRsn86'" 87 "'WakeRsn87'" 88 "'WakeRsn88'" 89 "'WakeRsn89'" 90 "'WakeRsn90'" 91 "'WakeRsn91'" 92 "'WakeRsn92'" 93 "'WakeRsn93'" 94 "'WakeRsn94'" 95 "'WakeRsn95'" 96 "'WakeRsn96'" 97 "'WakeRsn97'" 98 "'WakeRsn98'" 99 "'WakeRsn99'" 100 "'WakeRsn100'" 101 "'WakeRsn101'" 102 "'WakeRsn102'" 103 "'WakeRsn103'" 104 "'WakeRsn104'" 105 "'WakeRsn105'" 106 "'WakeRsn106'" 107 "'WakeRsn107'" 108 "'WakeRsn108'" 109 "'WakeRsn109'" 110 "'WakeRsn110'" 111 "'WakeRsn111'" 112 "'WakeRsn112'" 113 "'WakeRsn113'" 114 "'WakeRsn114'" 115 "'WakeRsn115'" 116 "'WakeRsn116'" 117 "'WakeRsn117'" 118 "'WakeRsn118'" 119 "'WakeRsn119'" 120 "'WakeRsn120'" 121 "'WakeRsn121'" 122 "'WakeRsn122'" 123 "'WakeRsn123'" 124 "'WakeRsn124'" 125 "'WakeRsn125'" 126 "'WakeRsn126'" 127 "'WakeRsn127'" ;
VAL_ 2654208005 WakeReq_TCU 1 "'Active'" 0 "'NotActive'" ;
VAL_ 1212 TCU_Replacement_Warning 1 "Active" 0 "Not_Active" ;
VAL_ 2654339077 GenericFailSts_TCU 1 "At_least_one_funct_fail_pres" 0 "No_functional_fail_is_present" ;
VAL_ 2654339077 EOL_TCU 1 "EOL_prog_At_FIAT" 0 "No_EOL_prog_At_FIAT" ;
VAL_ 2654339077 DES_TCU 3 "Not_used" 2 "Bus_off_state" 1 "Error_Passive_warning_state" 0 "Error_active_state" ;
VAL_ 2654339077 CurrentFailSts_TCU 1 "DTCStatus_present" 0 "No_functional_fail_is_present" ;
VAL_ 204 LWS_OK 1 "Valid" 0 "Not_Valid" ;
VAL_ 204 LWS_Angle 32767 "Invalid" ;
VAL_ 1388 GenericFailSts 0 "No_functional_fail_is_present" 1 "At_least_one_funct_fail_pres" ;
VAL_ 1388 EOL 0 "No_EOL_prog_At_FIAT" 1 "EOL_prog_At_FIAT" ;
VAL_ 1388 D_ES 0 "Error_Active_State" 1 "Error_Passive_Warning_State" 2 "Bus_Off_State" 3 "Not_used" ;
VAL_ 1388 CurrentFailsSts 0 "No_functional_fail_is_present" 1 "DTCStatus_present" ;
VAL_ 1530 Right_TI_Feedback_C_LCU 0 "OFF" 1 "ON" ;
VAL_ 1530 Right_TI_FailSts_C_LCU 0 "Fail_Not_present" 1 "Fail_present" ;
VAL_ 1530 Right_PL_Feedback_C_LCU 0 "OFF" 1 "ON" ;
VAL_ 1530 Right_LB_Feedback_C_LCU 0 "OFF" 1 "ON" ;
VAL_ 1530 Right_HB_Feedback_C_LCU 0 "OFF" 1 "ON" ;
VAL_ 1530 Right_DRL_Feedback_C_LCU 0 "OFF" 1 "ON" ;
VAL_ 1530 ParkingLight_Feedback_C_LCU 1 "Enable" 0 "Not_Enable" ;
VAL_ 1530 Left_TI_Feedback_C_LCU 0 "OFF" 1 "ON" ;
VAL_ 1530 Left_TI_FailSts_C_LCU 0 "Fail_Not_present" 1 "Fail_present" ;
VAL_ 1530 Left_PL_Feedback_C_LCU 0 "OFF" 1 "ON" ;
VAL_ 1530 Left_LB_Feedback_C_LCU 0 "OFF" 1 "ON" ;
VAL_ 1530 Left_HB_Feedback_C_LCU 0 "OFF" 1 "ON" ;
VAL_ 1530 Left_DRL_Feedback_C_LCU 0 "OFF" 1 "ON" ;
VAL_ 1530 GenericFailSts_C_LCU 0 "No_functional_fail_is_present" 1 "At_least_one_funct_fail_pres" ;
VAL_ 1530 EOL_C_LCU 0 "No_EOL_prog_At_FIAT" 1 "EOL_prog_At_FIAT" ;
VAL_ 1530 D_ES_C_LCU 0 "Error_Active_State" 1 "Error_Passive_Warning_State" 2 "Bus_Off_State" 3 "Not_used" ;
VAL_ 1530 CurrentFailsSts_C_LCU 0 "No_functional_fail_is_present" 1 "DTCStatus_present" ;
VAL_ 70 ABSSts 0 "INIT_" 1 "Fnc_Available_Ctrl_not_Active" 2 "Failure" 3 "Not_Available" 4 "Control_active" 5 "not_used" 6 "not_used" 7 "not_used" ;
VAL_ 70 BrkRecSts 0 "Init" 1 "FNC_Available_Ctrl_not_Active" 2 "Failure" 3 "Not_Available" 4 "Control_active" 5 "Not_used" 6 "Not_used" 7 "Not_used" ;
VAL_ 70 HDCSts 0 "Init" 1 "Fault" 2 "Off" 3 "Ready" 4 "Active" 5 "Suspended" 6 "Not_used" 7 "Not_used" ;
VAL_ 70 EBDSts 0 "INIT_" 1 "Fnc_Available_Ctrl_not_Active" 2 "Failure" 3 "Not_Available" 4 "Control_active" 5 "not_used" 6 "not_used" 7 "not_used" ;
VAL_ 70 ACC_Engine_Torque_Enabled_NFR 0 "Not_Enabled" 1 "Enabled" ;
VAL_ 70 TrqIncrease_Enabler_TCS 0 "Disabled" 1 "Enabled" ;
VAL_ 70 AVHSts 0 "INIT_" 1 "Fnc_Available_Ctrl_not_Active" 2 "Failure" 3 "Not_Available" 4 "Control_active" 5 "not_used" 6 "not_used" 7 "not_used" ;
VAL_ 70 CDPSts 0 "INIT_" 1 "Fnc_Available_Ctrl_not_Active" 2 "Failure" 3 "Not_Available" 4 "Control_active" 5 "not_used" 6 "not_used" 7 "not_used" ;
VAL_ 70 FrontCtrlSts 0 "INIT" 1 "Fnc_Available_Ctrl_not_Active" 2 "Failure" 3 "Not_Available" 4 "F1TCS_ASR_Active" 5 "MSR_Active" 6 "_4WD_Active" 7 "Not_Present" ;
VAL_ 70 RearCtrlSts 0 "INIT" 1 "Fnc_Available_Ctrl_not_Active" 2 "Failure" 3 "Not_Available" 4 "F1TCS_ASR_Active" 5 "MSR_Active" 6 "Not_used" 7 "Not_Present" ;
VAL_ 70 CommandedSilenceRequest 0 "Transmit" 1 "No_bus_communication_allowed" ;
VAL_ 70 ACCEngaged 0 "Not_Engaged" 1 "Engaged" ;
VAL_ 70 DsblFuelShutOff_ACC_NFR 0 "Not_Active" 1 "Active" ;
VAL_ 76 GearEngagedForADAS 0 "Not_Coded" 1 "_1th_gear" 2 "_2th_gear" 3 "_3th_gear" 4 "_4th_gear" 5 "_5th_gear" 6 "_6th_gear" 7 "_7th_gear" 8 "_8th_gear" 9 "Not_used" 10 "Not_used" 11 "Not_used" 12 "Not_used" 13 "Not_used" 14 "R" 15 "N" ;
VAL_ 76 NCRACCFailSts 0 "Fail_not_present" 1 "Fail_present" ;
VAL_ 76 ActiveGearRatioValidData 0 "Valid" 1 "Not_valid" ;
VAL_ 76 GearBoxAutomaticMode 0 "Not_active" 1 "Active" ;
VAL_ 76 DrivingCycle 0 "Not_fulfilled" 1 "Fullfilled" ;
VAL_ 76 WarmingUpCycle 0 "Not_fulfilled" 1 "Fullfilled" ;
VAL_ 76 GearEngaged 0 "'Not Coded'" 1 "'1st gear'" 2 "'2nd gear'" 3 "'3rd gear'" 4 "'4th gear'" 5 "'5th gear'" 6 "'6th gear'" 7 "'7th gear'" 8 "'8th gear'" 9 "Not_used" 10 "Not_used" 11 "Not_used" 12 "Not_used" 13 "Not_used" 14 "'R'" 15 "'N'" ;
VAL_ 76 FutureSyncGear 0 "'Not Coded'" 1 "'1st gear'" 2 "'2nd gear'" 3 "'3rd gear'" 4 "'4th gear'" 5 "'5th gear'" 6 "'6th gear'" 7 "'7th gear'" 8 "'8th gear'" 9 "Not_used" 10 "Not_used" 11 "Not_used" 12 "Not_used" 13 "Not_used" 14 "'R'" 15 "'N'" ;
VAL_ 76 ShiftInProgress 0 "No_Shift_in_progress" 1 "Shift_in_progress" ;
VAL_ 76 EngineSlaveMode 0 "No_slave" 1 "Slave_mode" ;
VAL_ 76 RaceStart 0 "Not_Active" 1 "Active" ;
VAL_ 175 InternalError 0 "No_internal_processing_error_det" 1 "An_internal_processing_error_det" ;
VAL_ 175 VoltageError 0 "No_Overvoltage_undervoltage_det" 1 "Overvoltage_undervoltage_detectd" ;
VAL_ 175 YRSStat 0 "Signal_in_specification_limits" 1 "Temporary_signal_error" 2 "Permanent_signal_error" 3 "Sensor_element_in_initialization" ;
VAL_ 175 AYSStat 0 "Signal_in_specification_limits" 1 "Temporary_signal_error" 2 "Permanent_signal_error" 3 "Sensor_element_in_initialization" ;
VAL_ 175 AXSStat 0 "Signal_in_specification_limits" 1 "Temporary_signal_error" 2 "Permanent_signal_error" 3 "Sensor_element_in_initialization" ;
VAL_ 175 LongAcceleration 4095 "Invalid_value" ;
VAL_ 175 LatAcceleration 4095 "Invalid_value" ;
VAL_ 175 YawRate 4095 "Invalid_value" ;
VAL_ 222 LwsAngle 65535 "Invalid" ;
VAL_ 222 LwsSpeed 4095 "Invalid" ;
VAL_ 222 LwsCalibration 0 "Not_calibrated" 1 "Calibrated" ;
VAL_ 222 LWSFailSts 0 "Fail_not_Present" 1 "Fail_Present_Ignition_Latched" 2 "Fail_Present_Recoverable" 3 "FailPresentBatteryDisconnection" ;
VAL_ 222 LwsNEWCalibration 0 "Not_Active" 1 "Active" ;
VAL_ 262 AssistanceTorque 4095 "Invalid" ;
VAL_ 262 TOIStatus 0 "TOI_Deactivated" 1 "TOI_TNA" 2 "TOI_PNA" 3 "TOI_Ready" 4 "TOI_Req_Denied" 5 "TOI_ACTIVE_AR_ENABLE" 6 "TOI_ACTIVE_AR_DISABLE" 7 "Not_Used" 8 "Not_Used" 9 "Not_Used" 10 "Not_Used" 11 "Not_Used" 12 "Not_Used" 13 "Not_Used" 14 "Not_Used" 15 "Not_Used" ;
VAL_ 262 SteeringColumnTorque 2047 "Invalid" ;
VAL_ 262 DSTTorqueOverlayIntActivated 0 "False" 1 "True" ;
VAL_ 262 DSTTorqueOverlayFault 0 "False" 1 "True" ;
VAL_ 262 EPSTemporaryDeactivation 0 "False" 1 "True" ;
VAL_ 262 Estimated_Rack_Force_sign 0 "Positive" 1 "Negative" ;
VAL_ 262 HALFTorqueOverlayIntActivated 0 "IDLE" 1 "HAS" 2 "LKA" 3 "ABSD" 4 "TJA" 5 "not_used" 6 "not_used" 7 "SNA" ;
VAL_ 262 HALFTorqueOverlayFault 0 "False" 1 "True" ;
VAL_ 262 Estimated_Rack_Force 255 "Invalid" ;
VAL_ 326 Slope 0 "less_than_minus60" 122 "more_than_60" 123 "Not_used" 124 "Not_used" 125 "Not_used" 126 "Not_used" 127 "Not_used" ;
VAL_ 326 EPBMalfunction 0 "Not_active" 1 "Active" ;
VAL_ 326 SlopeValidData 0 "Valid" 1 "Not_Valid" ;
VAL_ 326 Function2Sts 0 "Not_Active" 1 "Active" ;
VAL_ 326 FunctionSts 0 "Not_Active" 1 "Active" ;
VAL_ 326 EPBSts 0 "Released" 1 "Applied" 2 "Applying_in_progress" 3 "Releasing_in_progress" 4 "Not_used" 5 "Not_used" 6 "Not_used" 7 "Undefined_position" ;
VAL_ 326 EPB_ButtonSts 0 "Switch_not_pressed" 1 "Switch_pressed" 2 "Switch_defect_and_pressed" 3 "Switch_defect_and_not_pressed" ;
VAL_ 326 AutoDriveOffFailSts 0 "No_Fail" 1 "Fail" ;
VAL_ 326 VehicleSpeedVSOSigFailSts 0 "Fail_not_present" 1 "Fail_present" ;
VAL_ 326 ESCOFF_Mode 0 "ESC_ON" 1 "ESC_OFF" ;
VAL_ 326 ABSFailPresent 0 "Fail_not_present" 1 "Fail_present" ;
VAL_ 326 NFR_Speed_FA_FailSts 0 "Fail_not_present" 1 "Fail_present" ;
VAL_ 326 NFRAutoStopFailSts 0 "Fail_Not_Present" 1 "Fail_Present" ;
VAL_ 326 NFRAutoStopStaySts 0 "RecrankEngine" 1 "RemainStop" ;
VAL_ 326 NFRAutoStopEnableSts 0 "Disable" 1 "Enable" ;
VAL_ 326 NFRCruiseEnabler 0 "CC_Enabled" 1 "CC_Not_Enabled" ;
VAL_ 348 Intervention 2047 "SNA" ;
VAL_ 348 InterventionReq 0 "Not_Active" 1 "Active" ;
VAL_ 348 InterventionType 0 "None" 1 "ACC" 2 "AEB_P_standard" 3 "AEB_P_extended" 4 "EBA" 5 "AEB_L" 6 "'AEB_Crossing'" 7 "SNA" ;
VAL_ 348 BASensThresholdReq 0 "T0" 1 "T1" 2 "T2" 3 "T3" ;
VAL_ 348 HIS_Req 0 "Not_Active" 1 "Active" ;
VAL_ 348 Prefill_Req 0 "No_Prefill_Requested" 1 "Prefill_Requested" ;
VAL_ 348 Brake_Jerk_Req 0 "Not_Active" 1 "Active" ;
VAL_ 348 ACC_Engine_Torque_Enabled 0 "Not_Enabled" 1 "Enabled" ;
VAL_ 348 ACC_AccelerationReq 2047 "SNA" ;
VAL_ 348 DsblFuelShutOff_ACC 0 "Not_Active" 1 "Active" ;
VAL_ 359 NPE_Driver_Presence 1 "Driver_present" 0 "Driver_not_present" ;
VAL_ 359 IgnPosSts 0 "Initialization" 1 "IGN_LK" 2 "Shutdown_req" 3 "ACC" 4 "RUN" 5 "START" 6 "Not_used" 7 "SNA" ;
VAL_ 359 ValidKeySts 0 "CUST_IMMOB_KEY_DEFAULT" 1 "CUST_IMMOB_KEY_VALID" 2 "Not_used" 3 "SNA" ;
VAL_ 359 CustKeyInIgnSts 0 "CUST_KEY_DEFAULT" 1 "CUST_KEY_NOT_IN_IGNITION" 2 "CUST_KEY_IN_IGNITION" 3 "SNA" ;
VAL_ 359 RFFuncReq 0 "NO_BASIC_REQUEST" 1 "UNLOCK_BUTTON_Single_Pressure" 2 "UNLOCK_BUTTON_Double_Pressure" 3 "UNLOCK_BUTTON_Long_Pressure" 4 "LOCK_BUTTON_Single_Pressure" 5 "LOCK_BUTTON_Double_Pressure" 6 "LOCK_BUTTON_Long_Pressure" 7 "TRUNK_BUTTON_Single_Pressure" 8 "TRUNK_BUTTON_Double_Pressure" 9 "TRUNK_BUTTON_long_Pressure" 10 "BUTTON_D_Single_Pressure" 11 "BUTTON_D_Double_Pressure" 12 "BUTTON_D_long_Pressure" 13 "ALL_UNLOCK_REQUEST" 14 "BUTTON_A_Single_Pressure" 15 "BUTTON_A_Double_Pressure" 16 "BUTTON_A_Long_Pressure" 17 "BUTTON_B_Single_Pressure" 18 "BUTTON_B_Double_Pressure" 19 "BUTTON_B_Long_Pressure" 20 "BUTTON_C_Single_Pressure" 21 "BUTTON_C_Double_Pressure" 22 "BUTTON_C_Long_Pressure" 23 "Left_Unlatch_Switch_Actuation" 24 "Right_Unlatch_Switch_Actuation" 25 "Left_Lock_Switch_Actuation" 26 "Right_Lock_Switch_Actuation" 27 "Ext_Trunk_Open_Switch_Actuation" 28 "Button_C_Button_D_Single_Pressure" 29 "Button_C_Button_D_Long_Pressure" 30 "Charging_Open_Switch_Actuation" 31 "SNA" ;
VAL_ 359 RFFobNum 0 "FOB_DEFAULT" 1 "FOB_1" 2 "FOB_2" 3 "FOB_3" 4 "FOB_4" 5 "FOB_5" 6 "FOB_6" 7 "FOB_7" 8 "FOB_8" 9 "Not_used" 10 "Not_used" 11 "Not_used" 12 "Not_used" 13 "Not_used" 14 "Not_used" 15 "Not_used" ;
VAL_ 359 RFRearFuncReq 0 "NO_BASIC_REQUEST" 1 "RearLeftUnlatchSwitchActuation" 2 "RearRightUnlatchSwitchActuation" 3 "RearLeftLockSwitchActuation" 4 "RearRightLockSwitchActuation" 5 "Not_used" 6 "Not_used" 7 "SNA" ;
VAL_ 359 FobSearchResult 0 "No_Action" 1 "No_Action_ExteriorRear" 2 "No_Action_ExteriorLeft" 3 "No_Action_ExteriorRight" 4 "No_Action_Interior" 5 "Invalid" 6 "Invalid" 7 "Invalid" 8 "Interior" 9 "Invalid" 10 "Invalid" 11 "Invalid" 12 "Invalid" 13 "Invalid" 14 "Invalid" 15 "Invalid" 16 "No_Action_Trunk" 17 "Invalid" 18 "Invalid" 19 "Invalid" 20 "Invalid" 21 "Invalid" 22 "Invalid" 23 "Invalid" 24 "Invalid" 25 "Invalid" 26 "Invalid" 27 "Invalid" 28 "Invalid" 29 "Invalid" 30 "Invalid" 31 "Invalid" 32 "Fault" 33 "Fault" 34 "Fault" 35 "Fault" 36 "Fault" 37 "Fault" 38 "Fault" 39 "Fault" 40 "Fault" 41 "Fault" 42 "Fault" 43 "Fault" 44 "Fault" 45 "Fault" 46 "Fault" 47 "Fault" 48 "Fault" 49 "Fault" 50 "Fault" 51 "Fault" 52 "Fault" 53 "Fault" 54 "Fault" 55 "Fault" 56 "Fault" 57 "Fault" 58 "Fault" 59 "Fault" 60 "Fault" 61 "Fault" 62 "Fault" 63 "Fault" 64 "In_Progress" 65 "In_Progress" 66 "In_Progress" 67 "In_Progress" 68 "In_Progress" 69 "In_Progress" 70 "In_Progress" 71 "In_Progress" 72 "In_Progress" 73 "In_Progress" 74 "In_Progress" 75 "In_Progress" 76 "In_Progress" 77 "In_Progress" 78 "In_Progress" 79 "In_Progress" 80 "In_Progress" 81 "In_Progress" 82 "In_Progress" 83 "In_Progress" 84 "In_Progress" 85 "In_Progress" 86 "In_Progress" 87 "In_Progress" 88 "In_Progress" 89 "In_Progress" 90 "In_Progress" 91 "In_Progress" 92 "In_Progress" 93 "In_Progress" 94 "In_Progress" 95 "In_Progress" 96 "In_Progress" 97 "In_Progress" 98 "In_Progress" 99 "In_Progress" 100 "In_Progress" 101 "In_Progress" 102 "In_Progress" 103 "In_Progress" 104 "In_Progress" 105 "In_Progress" 106 "In_Progress" 107 "In_Progress" 108 "In_Progress" 109 "In_Progress" 110 "In_Progress" 111 "In_Progress" 112 "In_Progress" 113 "In_Progress" 114 "In_Progress" 115 "In_Progress" 116 "In_Progress" 117 "In_Progress" 118 "In_Progress" 119 "In_Progress" 120 "In_Progress" 121 "In_Progress" 122 "In_Progress" 123 "In_Progress" 124 "In_Progress" 125 "In_Progress" 126 "In_Progress" 127 "In_Progress" 128 "Complete_Key_not_found" 129 "Complete_ExteriorRear" 130 "Complete_ExteriorLeft" 131 "Invalid" 132 "Complete_ExteriorRight" 133 "Invalid" 134 "Invalid" 135 "Invalid" 136 "Complete_Interior" 137 "Invalid" 138 "Invalid" 139 "Invalid" 140 "Invalid" 141 "Invalid" 142 "Invalid" 143 "Invalid" 144 "Complete_Trunk" 145 "Invalid" 146 "Invalid" 147 "Invalid" 148 "Invalid" 149 "Invalid" 150 "Invalid" 151 "Invalid" 152 "Complete_TrunkInterior" 153 "Invalid" 154 "Invalid" 155 "Invalid" 156 "Invalid" 157 "Invalid" 158 "Invalid" 159 "Invalid" 160 "Fault" 161 "Fault" 162 "Fault" 163 "Fault" 164 "Fault" 165 "Fault" 166 "Fault" 167 "Fault" 168 "Fault" 169 "Fault" 170 "Fault" 171 "Fault" 172 "Fault" 173 "Fault" 174 "Fault" 175 "Fault" 176 "Fault" 177 "Fault" 178 "Fault" 179 "Fault" 180 "Fault" 181 "Fault" 182 "Fault" 183 "Fault" 184 "Fault" 185 "Fault" 186 "Fault" 187 "Fault" 188 "Fault" 189 "Fault" 190 "Fault" 191 "Fault" 192 "TimeOut" 193 "TimeOut" 194 "TimeOut" 195 "TimeOut" 196 "TimeOut" 197 "TimeOut" 198 "TimeOut" 199 "TimeOut" 200 "TimeOut" 201 "TimeOut" 202 "TimeOut" 203 "TimeOut" 204 "TimeOut" 205 "TimeOut" 206 "TimeOut" 207 "TimeOut" 208 "TimeOut" 209 "TimeOut" 210 "TimeOut" 211 "TimeOut" 212 "TimeOut" 213 "TimeOut" 214 "TimeOut" 215 "TimeOut" 216 "TimeOut" 217 "TimeOut" 218 "TimeOut" 219 "TimeOut" 220 "TimeOut" 221 "TimeOut" 222 "TimeOut" 223 "TimeOut" 224 "TimeOut" 225 "TimeOut" 226 "TimeOut" 227 "TimeOut" 228 "TimeOut" 229 "TimeOut" 230 "TimeOut" 231 "TimeOut" 232 "TimeOut" 233 "TimeOut" 234 "TimeOut" 235 "TimeOut" 236 "TimeOut" 237 "TimeOut" 238 "TimeOut" 239 "TimeOut" 240 "TimeOut" 241 "TimeOut" 242 "TimeOut" 243 "TimeOut" 244 "TimeOut" 245 "TimeOut" 246 "TimeOut" 247 "TimeOut" 248 "TimeOut" 249 "TimeOut" 250 "TimeOut" 251 "TimeOut" 252 "TimeOut" 253 "TimeOut" 254 "TimeOut" 255 "TimeOut" ;
VAL_ 359 RFReq 0 "REQUESTOR_DEFAULT" 1 "REQUESTOR_RKE" 2 "REQUESTOR_PE" 3 "REQUESTOR_REMOTESTART" 4 "REQUESTOR_UCONNECT" 5 "REQUESTOR_WalkAway" 6 "REQUESTOR_PE_KICKBOOT" 7 "SNA" ;
VAL_ 359 FOBInterferenceAvoid 0 "Not_Active" 1 "Active" ;
VAL_ 359 DriverEnginOffRequest 0 "Not_active" 1 "Active" ;
VAL_ 359 StartButtonSts 0 "Not_Pressed" 1 "Pressed" ;
VAL_ 359 FobSearchResult_LongPressure 0 "No_Action" 1 "Research_in_progress" 2 "Not_Found" 3 "Found_ExteriorRear" 4 "Found_ExteriorLeft" 5 "Found_Exterior_Right" 6 "Found_Interior" 7 "Found_Trunk" ;
VAL_ 390 VDCSts 0 "INIT_" 1 "Fnc_Available_Ctrl_not_Active" 2 "Failure" 3 "Not_Available" 4 "Control_active" 5 "not_used" 6 "not_used" 7 "not_used" ;
VAL_ 390 EDIFFDisplayInfo 0 "No_Request_to_HMI" 1 "Fail_Lamp_ON" ;
VAL_ 390 EDIFFSts 0 "INIT_" 1 "Fnc_Available_Ctrl_not_Active" 2 "Failure" 3 "Not_Available" 4 "not_used" 5 "Degraded" 6 "not_used" 7 "not_used" ;
VAL_ 390 LDISts 0 "INIT_" 1 "Fnc_Available_Ctrl_not_Active" 2 "Failure" 3 "Not_Available" 4 "Control_active" 5 "not_used" 6 "not_used" 7 "not_used" ;
VAL_ 390 B_OpenClutch 0 "Close" 1 "Open" ;
VAL_ 400 NAM_dSpace_Enabled 0 "Not_Enabled" 1 "Enabled" ;
VAL_ 400 Wing3_Fbk_Pos_FailSts 0 "Fail_Not_Present" 1 "Fail_Present" ;
VAL_ 400 Wing2_Fbk_Pos_FailSts 0 "Fail_Not_Present" 1 "Fail_Present" ;
VAL_ 400 Wing1_Fbk_Pos_FailSts 0 "Fail_Not_Present" 1 "Fail_Present" ;
VAL_ 426 FL_pRad 255 "SNA" ;
VAL_ 426 FR_pRad 255 "SNA" ;
VAL_ 426 RL_pRad 255 "SNA" ;
VAL_ 426 RR_pRad 255 "SNA" ;
VAL_ 502 SteeringVibrationType 0 "'TYPE_0'" 1 "'TYPE_1'" 2 "'TYPE_2'" 3 "'SNA'" ;
VAL_ 502 TorqueOverlayIntActivation_HALF 0 "'IDLE'" 1 "'HAS'" 2 "'LKA'" 3 "'ABSD'" 4 "'TJA'" 5 "Not_used" 6 "Not_used" 7 "'SNA'" ;
VAL_ 502 SteeringVibrationReq 0 "'NOT_REQUESTED'" 1 "'REQUESTED'" ;
VAL_ 502 HALFSystemSts 0 "'NoFault'" 1 "'Fault'" ;
VAL_ 518 VRD_RH 0 "Initialization" ;
VAL_ 518 LH_WheelDirectionSts 0 "Standstill_no_direction_detected" 1 "Forward" 2 "Backward" 3 "Invalid" ;
VAL_ 518 VRD_LHValidData 0 "Valid" 1 "Not_valid" ;
VAL_ 518 RH_WheelDirectionSts 0 "Standstill_no_direction_detected" 1 "Forward" 2 "Backward" 3 "Invalid" ;
VAL_ 518 VRD_RHValidData 0 "Valid" 1 "Not_valid" ;
VAL_ 518 VRD_LH 0 "Initialization" ;
VAL_ 524 Slope 0 "less_than_minus60" 122 "more_than_60" 123 "Not_used" 124 "Not_used" 125 "Not_used" 126 "Not_used" 127 "Not_used" ;
VAL_ 524 EPBMalfunction 0 "Not_active" 1 "Active" ;
VAL_ 524 SlopeValidData 0 "Valid" 1 "Not_Valid" ;
VAL_ 524 Function2Sts 0 "Not_Active" 1 "Active" ;
VAL_ 524 FunctionSts 0 "Not_Active" 1 "Active" ;
VAL_ 524 EPBSts 0 "Released" 1 "Applied" 2 "Applying_in_progress" 3 "Releasing_in_progress" 4 "Not_used" 5 "Not_used" 6 "Not_used" 7 "Undefined_position" ;
VAL_ 524 EPB_ButtonSts 0 "Switch_not_pressed" 1 "Switch_pressed" 2 "Switch_defect_and_pressed" 3 "Switch_defect_and_not_pressed" ;
VAL_ 524 AutoDriveOffFailSts 0 "No_Fail" 1 "Fail" ;
VAL_ 524 VehicleSpeedVSOSigFailSts 0 "Fail_not_present" 1 "Fail_present" ;
VAL_ 524 ESCOFF_Mode 0 "ESC_ON" 1 "ESC_OFF" ;
VAL_ 524 ABSFailPresent 0 "Fail_not_present" 1 "Fail_present" ;
VAL_ 524 NFR_Speed_FA_FailSts 0 "Fail_not_present" 1 "Fail_present" ;
VAL_ 524 NFRAutoStopFailSts 0 "Fail_Not_Present" 1 "Fail_Present" ;
VAL_ 524 NFRAutoStopStaySts 0 "RecrankEngine" 1 "RemainStop" ;
VAL_ 524 NFRAutoStopEnableSts 0 "Disable" 1 "Enable" ;
VAL_ 524 NFRCruiseEnabler 0 "CC_Enabled" 1 "CC_Not_Enabled" ;
VAL_ 550 VRD_RV 0 "Initialization" ;
VAL_ 550 LV_WheelDirectionSts 0 "Standstill_no_direction_detected" 1 "Forward" 2 "Backward" 3 "Invalid" ;
VAL_ 550 VRD_LVValidData 0 "Valid" 1 "Not_valid" ;
VAL_ 550 RV_WheelDirectionSts 0 "Standstill_no_direction_detected" 1 "Forward" 2 "Backward" 3 "Invalid" ;
VAL_ 550 VRD_RVValidData 0 "Valid" 1 "Not_valid" ;
VAL_ 550 VRD_LV 0 "Initialization" ;
VAL_ 599 AirBagWarningPABLabelSts 1 "PassengerAirbag_Fail" 0 "PassengerAirbag_OK" ;
VAL_ 599 SBR2RowCentralSeatBuckleFailSts 0 "Fail_Not_Present" 1 "Fail_Present" 2 "Not_used" 3 "SNA" ;
VAL_ 599 SBR2RowCentralSeatConfigSts 0 "Seat_Not_Checked" 1 "Seat_Checked" ;
VAL_ 599 AirBagFailSts 0 "Fail_Not_Present_Lamp_Off" 1 "Fail_Not_Present_Lamp_Flashing" 2 "Fail_Present_Lamp_On" 3 "Not_used" ;
VAL_ 599 SBR1RowDriverSeatFailSts 0 "Fail_Not_Present" 1 "Fail_Present" 2 "Not_used" 3 "SNA" ;
VAL_ 599 SBR1RowDriverSeatConfigSts 0 "Seat_Not_Checked" 1 "Seat_Checked" ;
VAL_ 599 SBR2RowCentralSeatSts 0 "Seat_Belt_Fasten" 1 "Seat_Belt_Not_Fasten" 2 "Seat_Safe" 3 "Seat_Not_Safe" 4 "Not_used" 5 "Not_used" 6 "Not_used" 7 "SNA" ;
VAL_ 599 SBR1RowCentralSeatPPDFailSts 0 "Fail_Not_Present" 1 "Fail_Present" 2 "Not_used" 3 "SNA" ;
VAL_ 599 SBR1RowPsngrSeatPPDFailSts 0 "Fail_Not_Present" 1 "Fail_Present" 2 "Not_used" 3 "SNA" ;
VAL_ 599 SBR1RowPsngrSeatBuckleFailSts 0 "Fail_Not_Present" 1 "Fail_Present" 2 "Not_used" 3 "SNA" ;
VAL_ 599 SBR1RowPsngrSeatConfigSts 0 "Seat_Not_Checked" 1 "Seat_Checked" ;
VAL_ 599 SBR1RowDriverSeatSts 0 "Seat_Belt_Fasten" 1 "Seat_Belt_Not_Fasten" 2 "Not_used" 3 "SNA" ;
VAL_ 599 SBR2RowLeftSeatSts 0 "Seat_Belt_Fasten" 1 "Seat_Belt_Not_Fasten" 2 "Not_used" 3 "SNA" ;
VAL_ 599 SBR2RowRightSeatFailSts 0 "Fail_Not_Present" 1 "Fail_Present" 2 "Not_used" 3 "SNA" ;
VAL_ 599 SBR2RowLeftSeatFailSts 0 "Fail_Not_Present" 1 "Fail_Present" 2 "Not_used" 3 "SNA" ;
VAL_ 599 SBR1RowPsngrSeatSts 0 "Seat_Belt_Fasten" 1 "Seat_Belt_Not_Fasten" 2 "Seat_Safe" 3 "Seat_Not_Safe" 4 "Not_used" 5 "Not_used" 6 "Not_used" 7 "SNA" ;
VAL_ 599 CrashOutputSts 0 "No_crash" 1 "Front_Pretensioner" 2 "Front_First_Level" 4 "Front_Second_Level" 8 "Passenger_Side" 16 "Driver_Side" 32 "Rear" 64 "Rollover" 128 "Pedestrian" ;
VAL_ 599 SBR2RowRightSeatSts 0 "Seat_Belt_Fasten" 1 "Seat_Belt_Not_Fasten" 2 "Not_used" 3 "SNA" ;
VAL_ 599 CrashOutputValidData 0 "Valid" 1 "Not_Valid" ;
VAL_ 599 AirBagWarningPADLampOnSts 0 "PADLampON_OK" 1 "PADLampON_Fail" ;
VAL_ 599 AirBagWarningPADLampOffSts 0 "PADLampOFF_OK" 1 "PADLampOFF_Fail" ;
VAL_ 599 SBR2RowRightSeatConfigSts 0 "Seat_Not_Checked" 1 "Seat_Checked" ;
VAL_ 599 SBR2RowLeftSeatConfigSts 0 "Seat_Not_Checked" 1 "Seat_Checked" ;
VAL_ 599 Ppd_psngr_info 0 "passenger_absent" 1 "passenger_present" 2 "PPD_Fault" 3 "PPD_device_not_present" ;
VAL_ 599 AirBagWarningLampSts 0 "Lamp_OK" 1 "Lamp_in_Fail" ;
VAL_ 786 TSROperatingStatus 0 "Off" 1 "Fusion_Mode" 2 "Vision_only_Mode" 3 "Navigation_only_mode" 4 "Not_used" 5 "Not_used" 6 "Not_used" 7 "Defect" ;
VAL_ 786 TSRSignType 0 "Unknown" 1 "Vienna_convention_or_UK" 2 "US_or_Ireland" 3 "Canada_or_Singapore" 4 "China_or_Japan" 5 "Korea_or_Malaysia" 6 "Not_used" 7 "Not_used" ;
VAL_ 786 TSRHandOfTraffic 0 "LH_Traffic" 1 "RH_Traffic" 2 "Unknown" 3 "Not_used" ;
VAL_ 786 TSRMainSign1 0 "Unknown" 1 "Cancellation" 2 "_5" 3 "_10" 4 "_15" 5 "_20" 6 "_25" 7 "_30" 8 "_35" 9 "_40" 10 "_45" 11 "_50" 12 "_55" 13 "_60" 14 "_65" 15 "_70" 16 "_75" 17 "_80" 18 "_85" 19 "_90" 20 "_95" 21 "_100" 22 "_105" 23 "_110" 24 "_115" 25 "_120" 26 "_125" 27 "_130" 28 "_135" 29 "_140" 30 "_145" 31 "_150" 32 "_155" 33 "_160" 34 "not_used" 35 "not_used" 36 "not_used" 37 "not_used" 38 "not_used" 39 "not_used" 40 "not_used" 41 "not_used" 42 "not_used" 43 "not_used" 44 "not_used" 45 "not_used" 46 "not_used" 47 "not_used" 48 "not_used" 49 "not_used" 50 "not_used" 51 "not_used" 52 "not_used" 53 "not_used" 54 "not_used" 55 "not_used" 56 "not_used" 57 "not_used" 58 "not_used" 59 "not_used" 60 "not_used" 61 "_7" ;
VAL_ 786 TSRMainSign2 0 "No_Display" 1 "ProhibitionOvertakingCancelled" 2 "ProhibitionOvertaking" 3 "ProhibitionOvertakingUnkRes" 4 "not_used" 5 "not_used" 6 "not_used" 7 "not_used" 8 "not_used" 9 "not_used" 10 "Warning_Slippery_Road" 11 "not_used" 12 "not_used" 13 "not_used" 14 "not_used" 15 "not_used" 16 "not_used" 17 "not_used" 18 "not_used" 19 "not_used" 20 "not_used" 21 "not_used" 22 "not_used" 23 "Warning_Roadworks" 24 "not_used" 25 "not_used" 26 "not_used" 27 "not_used" 28 "not_used" 29 "not_used" 30 "not_used" 31 "not_used" 32 "not_used" 33 "not_used" 34 "not_used" 35 "not_used" 36 "not_used" 37 "not_used" 38 "not_used" 39 "not_used" 40 "not_used" 41 "not_used" 42 "not_used" 43 "not_used" 44 "not_used" 45 "not_used" 46 "not_used" 47 "not_used" 48 "not_used" 49 "not_used" 50 "not_used" 51 "not_used" 52 "not_used" 53 "not_used" 54 "not_used" 55 "not_used" 56 "not_used" 57 "not_used" 58 "not_used" 59 "not_used" 60 "not_used" 61 "not_used" 62 "not_used" 63 "not_used" 64 "not_used" 65 "not_used" 66 "not_used" 67 "not_used" 68 "not_used" 69 "not_used" 70 "not_used" 71 "not_used" 72 "not_used" 73 "not_used" 74 "not_used" 75 "not_used" 76 "not_used" 77 "not_used" 78 "not_used" 79 "not_used" 80 "not_used" 81 "not_used" 82 "not_used" 83 "not_used" 84 "not_used" 85 "not_used" 86 "not_used" 87 "not_used" 88 "not_used" 89 "not_used" 90 "not_used" 91 "not_used" 92 "not_used" 93 "not_used" 94 "not_used" 95 "not_used" 96 "not_used" 97 "not_used" 98 "not_used" 99 "not_used" 100 "not_used" 101 "not_used" 102 "not_used" 103 "not_used" 104 "not_used" 105 "not_used" 106 "not_used" 107 "not_used" 108 "not_used" 109 "not_used" 110 "not_used" 111 "not_used" 112 "not_used" 113 "not_used" 114 "not_used" 115 "not_used" 116 "not_used" 117 "not_used" 118 "not_used" 119 "not_used" 120 "not_used" 121 "not_used" 122 "not_used" 123 "not_used" 124 "not_used" 125 "not_used" 126 "not_used" 127 "not_used" 128 "not_used" 129 "not_used" 130 "not_used" 131 "not_used" 132 "not_used" 133 "not_used" 134 "not_used" 135 "not_used" 136 "not_used" 137 "not_used" 138 "not_used" 139 "not_used" 140 "not_used" 141 "not_used" 142 "not_used" 143 "not_used" 144 "not_used" 145 "not_used" 146 "not_used" 147 "not_used" 148 "not_used" 149 "not_used" 150 "not_used" 151 "not_used" 152 "not_used" 153 "not_used" 154 "not_used" 155 "not_used" 156 "not_used" 157 "not_used" 158 "not_used" 159 "not_used" 160 "not_used" 161 "not_used" 162 "not_used" 163 "not_used" 164 "not_used" 165 "not_used" 166 "not_used" 167 "not_used" 168 "not_used" 169 "not_used" 170 "not_used" 171 "not_used" 172 "not_used" 173 "not_used" 174 "not_used" 175 "not_used" 176 "not_used" 177 "not_used" 178 "not_used" 179 "not_used" 180 "not_used" 181 "not_used" 182 "not_used" 183 "not_used" 184 "not_used" 185 "not_used" 186 "not_used" 187 "not_used" 188 "not_used" 189 "not_used" 190 "not_used" 191 "not_used" 192 "not_used" 193 "not_used" 194 "not_used" 195 "not_used" 196 "not_used" 197 "not_used" 198 "not_used" 199 "not_used" 200 "not_used" 201 "not_used" 202 "not_used" 203 "not_used" 204 "not_used" 205 "not_used" 206 "not_used" 207 "not_used" 208 "not_used" 209 "not_used" 210 "not_used" 211 "not_used" 212 "not_used" 213 "not_used" 214 "not_used" 215 "not_used" 216 "not_used" 217 "not_used" 218 "not_used" 219 "not_used" 220 "not_used" 221 "not_used" 222 "not_used" 223 "not_used" 224 "not_used" 225 "not_used" 226 "not_used" 227 "not_used" 228 "not_used" 229 "not_used" 230 "not_used" 231 "not_used" 232 "not_used" 233 "not_used" 234 "not_used" 235 "not_used" 236 "not_used" 237 "not_used" 238 "not_used" 239 "not_used" 240 "not_used" 241 "not_used" 242 "not_used" 243 "not_used" 244 "not_used" 245 "not_used" 246 "not_used" 247 "not_used" 248 "not_used" 249 "not_used" 250 "not_used" 251 "not_used" 252 "not_used" 253 "not_used" 254 "not_used" 255 "not_used" ;
VAL_ 786 TSRAddSign1 0 "Undefined1" 1 "CAR" 2 "not_used" 3 "not_used" 4 "not_used" 5 "not_used" 6 "not_used" 7 "not_used" 8 "not_used" 9 "not_used" 10 "not_used" 11 "not_used" 12 "not_used" 13 "WET" 14 "not_used" 15 "RAIN" 16 "SNOW" 17 "TIME" 18 "SECTION" 19 "not_used" 20 "not_used" 21 "EXIT_LEFT" 22 "EXIT_RIGHT" 23 "not_used" 24 "not_used" 25 "not_used" 26 "not_used" 27 "not_used" 28 "TRACTOR_OVER" 29 "not_used" 30 "not_used" 31 "RAIN_AND_SNOW" 32 "not_used" 33 "not_used" 34 "not_used" 35 "ZONE" 36 "not_used" 37 "not_used" 38 "not_used" 39 "not_used" 40 "not_used" 41 "not_used" 42 "not_used" 43 "not_used" 44 "not_used" 45 "not_used" 46 "not_used" 47 "not_used" 48 "not_used" 49 "not_used" 50 "not_used" 51 "not_used" 52 "not_used" 53 "SCHOOL" 54 "NIGHT" 55 "not_used" 56 "not_used" 57 "not_used" 58 "not_used" 59 "not_used" 60 "not_used" 61 "not_used" 62 "not_used" 63 "not_used" ;
VAL_ 786 TSRSpdLimitUnits 0 "Unknown" 1 "km_h" 2 "mph" 3 "Not_used" ;
VAL_ 786 TSRAddSign2 0 "Undefined2" 1 "CAR" 2 "not_used" 3 "not_used" 4 "not_used" 5 "not_used" 6 "not_used" 7 "not_used" 8 "not_used" 9 "not_used" 10 "not_used" 11 "not_used" 12 "not_used" 13 "WET" 14 "not_used" 15 "RAIN" 16 "SNOW" 17 "TIME" 18 "SECTION" 19 "not_used" 20 "not_used" 21 "EXIT_LEFT" 22 "EXIT_RIGHT" 23 "not_used" 24 "not_used" 25 "not_used" 26 "not_used" 27 "not_used" 28 "TRACTOR_OVER" 29 "not_used" 30 "not_used" 31 "RAIN_AND_SNOW" 32 "not_used" 33 "not_used" 34 "not_used" 35 "ZONE" 36 "not_used" 37 "not_used" 38 "not_used" 39 "not_used" 40 "not_used" 41 "not_used" 42 "not_used" 43 "not_used" 44 "not_used" 45 "not_used" 46 "not_used" 47 "not_used" 48 "not_used" 49 "not_used" 50 "not_used" 51 "not_used" 52 "not_used" 53 "SCHOOL" 54 "NIGHT" 55 "not_used" 56 "not_used" 57 "not_used" 58 "not_used" 59 "not_used" 60 "not_used" 61 "not_used" 62 "not_used" 63 "not_used" ;
VAL_ 865 EngineSpeedValidData 0 "Valid" 1 "Not_valid" ;
VAL_ 865 CylCutEnabled 0 "Cyl_Cut_not_enabled_for_DCT" 1 "Cyl_Cut_enabled_for_DCT" ;
VAL_ 865 GPFInfo_NCM_ValidData 0 "Valid" 1 "Not_valid" ;
VAL_ 865 VehDriverReqTrqValidData 0 "Valid" 1 "Not_valid" ;
VAL_ 865 GasPedalPositionValidData 0 "Valid" 1 "Not_valid" ;
VAL_ 865 GPFInfo_NCM_MuxId 0 "GPFInfo_LSB" 1 "GPFInfo_MSB" ;
VAL_ 870 Buzzer4A 0 "Not_active" 1 "Active" ;
VAL_ 870 Buzzer3A 0 "Not_active" 1 "Active" ;
VAL_ 870 Buzzer2A 0 "Not_active" 1 "Active" ;
VAL_ 870 Buzzer1A 0 "Not_active" 1 "Active" ;
VAL_ 870 BuzzerVolumeWarning 0 "Level_0_min_volume" 1 "Level_1" 2 "Level_2" 3 "Level_3" 4 "Level_4" 5 "Level_5" 6 "Level_6" 7 "Level_7_max_volume" ;
VAL_ 870 BuzzerACC_prox 0 "Not_active" 1 "Active" ;
VAL_ 870 Buzzer2A_Backrest 0 "Not_active" 1 "Active" ;
VAL_ 870 StartButtonSound 0 "Not_active" 1 "Active" ;
VAL_ 870 BuzzerSpeed_Alert 0 "Not_active" 1 "Active" ;
VAL_ 870 Buzzer3D 0 "Not_active" 1 "Active" ;
VAL_ 870 Buzzer3C 0 "Not_active" 1 "Active" ;
VAL_ 870 Buzzer2C 0 "Not_active" 1 "Active" ;
VAL_ 870 Buzzer2B 0 "Not_active" 1 "Active" ;
VAL_ 870 Buzzer2B_DDA 0 "Not_active" 1 "Active" ;
VAL_ 870 VolumeAdjustable 0 "No_buzzer" 1 "Volume_Adjustable" 2 "Volume_NotAdjustable" 3 "Not_used" ;
VAL_ 870 NQSIsPlaying 0 "Not_active" 1 "Active" ;
VAL_ 929 EngineTorqueValidData 0 "Valid" 1 "Not_valid" ;
VAL_ 929 TotalFrontAxleTorqueValidData 0 "Valid" 1 "Not_valid" ;
VAL_ 929 EngineTorqueDriverReqValidData 0 "Valid" 1 "Not_valid" ;
VAL_ 929 MaxEngineTorqueValidData 0 "Valid" 1 "Not_valid" ;
VAL_ 929 TotalFrontAxleTorque_V3 2047 "Failure_Value" ;
VAL_ 930 EngTrqEnblRq_DAS 0 "False" 1 "True" ;
VAL_ 930 RPMOverRev 0 "False" 1 "True" ;
VAL_ 930 Override 0 "Not_active" 1 "Active" ;
VAL_ 930 TrackExhaustInd 0 "Not_Active" 1 "Active" ;
VAL_ 930 EngineSpeedHiResValidData 0 "Valid" 1 "Not_Valid" ;
VAL_ 980 CruiseControlCmdResumeSts 0 "Not_Active" 1 "Active" ;
VAL_ 980 CruiseControlCmdChangeSts 0 "Not_Active" 1 "Active" ;
VAL_ 980 CruiseControlCmdDecelerationSts 0 "Not_Pressed" 1 "Pressed" ;
VAL_ 980 CruiseControlCmdAccelerationSts 0 "Not_Pressed" 1 "Pressed" ;
VAL_ 980 HManettinoDriverWishFailSts 0 "Not_fulfilled" 1 "Fullfilled" ;
VAL_ 980 HManettinoDriverWish 0 "NO_COMMAND" 1 "eDrive" 2 "Hybrid" 3 "Performance" 4 "Qualifying" 5 "Not_used" 6 "Not_used" 7 "Not_used" ;
VAL_ 980 CruiseControlFailSts 0 "Fail_not_present" 1 "Fail_Present" ;
VAL_ 980 ACC_OnOffSts 0 "Not_active" 1 "Active" ;
VAL_ 980 SpeedRockerSts 0 "Increase_10" 1 "Increase_01" 2 "No_Req" 3 "Decrease_01" 4 "Decrease_10" 5 "Not_used" 6 "Not_used" 7 "Not_used" ;
VAL_ 980 ACC_DistSts 0 "Not_active" 1 "Active" ;
VAL_ 980 ResumeSwitch 0 "Not_active" 1 "Active" ;
VAL_ 980 ManettinoSuspensionSts 0 "Follow_Manettino_Sts" 1 "Position_1" 2 "Position_2" 3 "Position_3" 4 "Not_used" 5 "Not_used" 6 "Not_used" 7 "Not_used" ;
VAL_ 980 ESPChangeModeReqSts 0 "Not_active" 1 "Active" ;
VAL_ 980 ManettinoFailSts 0 "Fail_Not_Present" 1 "Fail_Present" ;
VAL_ 980 ManettinoSts 0 "Position_0" 1 "Position_1" 2 "Position_2" 3 "Position_3" 4 "Position_4" 5 "Not_used" 6 "Not_used" 7 "Not_used" ;
VAL_ 980 FrontWindshieldWiperSwitchSts 0 "No_command" 1 "Antipanic" 2 "First_Speed" 3 "Second_Speed" 4 "Auto1" 5 "Auto2" 6 "Not_used" 7 "Not_used" ;
VAL_ 980 SuspensionButtonSts 0 "Not_Pressed" 1 "Pressed" ;
VAL_ 980 LdirectionSwitchSts_NVO_INFO 0 "Not_Active" 1 "Active" ;
VAL_ 980 RdirectionSwitchSts_NVO_INFO 0 "Not_Active" 1 "Active" ;
VAL_ 980 EfficiencyModeRequest 0 "Normal" 1 "Hold" 2 "Recharge" 3 "Not_used" ;
VAL_ 980 LChangeLaneSts_NVO_INFO 0 "Not_Active" 1 "Active" ;
VAL_ 980 RChangeLaneSts_NVO_INFO 0 "Not_Active" 1 "Active" ;
VAL_ 980 HDCButtonSts 0 "Not_Pressed" 1 "Pressed" ;
VAL_ 980 ADAS_OnOffSts 0 "Not_Pressed" 1 "Pressed" ;
VAL_ 980 FrontWindshieldWasherSwitchSts 0 "Not_Active" 1 "Active" ;
VAL_ 988 TyrePressureSystemSts 0 "On" 1 "Disabled" ;
VAL_ 988 TyrePressureSystemFailSts 0 "Fail_Not_Present" 1 "Fail_Present" ;
VAL_ 988 TyrePressureSysCalibrationSts 0 "SystemCalibrated" 1 "SystemNotCalibrated" ;
VAL_ 988 NTPTempNotActiveSts 0 "Active" 1 "TemporarilyNotActive" ;
VAL_ 988 NTPCalibrationReqACK 0 "No_calibration_request" 1 "Calibration_Request_Acknowledged" ;
VAL_ 988 IDtyre_temperature 0 "LF" 1 "RF" 2 "LR" 3 "RR" ;
VAL_ 988 TemperatureSts_xx 254 "ValueNotAvailable" 255 "FaultValue" ;
VAL_ 988 UnknownTyrePressureSts 0 "Fail_Not_Present" 1 "Low_Pressure_Soft_warning" 2 "Flat_Tyre_Hard_warning" 3 "High_Temperature" ;
VAL_ 988 TPMSTelltaleSts 0 "OFF" 1 "Blink_Malfunctioning" 2 "ON_Puncture_Malfunctioning" 3 "Not_used" ;
VAL_ 988 RHRTyrePressureSts 0 "Fail_Not_Present" 1 "Low_Pressure_Soft_warning" 2 "Flat_Tyre_Hard_warning" 3 "High_Temperature" ;
VAL_ 988 LHRTyrePressureSts 0 "Fail_Not_Present" 1 "Low_Pressure_Soft_warning" 2 "Flat_Tyre_Hard_warning" 3 "High_Temperature" ;
VAL_ 988 RHFTyrePressureSts 0 "Fail_Not_Present" 1 "Low_Pressure_Soft_warning" 2 "Flat_Tyre_Hard_warning" 3 "High_Temperature" ;
VAL_ 988 LHFTyrePressureSts 0 "Fail_Not_Present" 1 "Low_Pressure_Soft_warning" 2 "Flat_Tyre_Hard_warning" 3 "High_Temperature" ;
VAL_ 988 LHFPressureSts 254 "ValueNotAvailable" 255 "FaultValue" ;
VAL_ 988 RHFPressureSts 254 "ValueNotAvailable" 255 "FaultValue" ;
VAL_ 988 LHRPressureSts 254 "ValueNotAvailable" 255 "FaultValue" ;
VAL_ 988 RHRPressureSts 254 "ValueNotAvailable" 255 "FaultValue" ;
VAL_ 1023 HBActivation 0 "OFF" 1 "ON" 2 "FLASH" 3 "Not_used" ;
VAL_ 1023 LBActivation 0 "OFF" 1 "ON" ;
VAL_ 1023 ParkingLightCmd 0 "Not_Active" 1 "Active" ;
VAL_ 1023 LeftPL 0 "OFF" 1 "ON" ;
VAL_ 1023 RightPL 0 "OFF" 1 "ON" ;
VAL_ 1023 LeftDRL 0 "OFF" 1 "ON" ;
VAL_ 1023 RightDRL 0 "OFF" 1 "ON" ;
VAL_ 1023 AHB_Memory 0 "FALSE" 1 "TRUE" ;
VAL_ 1023 FBL_Activation 0 "OFF" 1 "ON" ;
VAL_ 1023 TrafficChangeEnable 0 "INIT" 1 "active" 2 "Not_Active" 3 "Not_used" ;
VAL_ 1023 AFSReq 0 "OFF" 1 "ON" ;
VAL_ 1023 FrontWindshieldWiperSts 0 "Not_Active" 1 "Active" ;
VAL_ 1023 FrontWindshieldWasherSts 0 "Not_Active" 1 "Active" ;
VAL_ 1023 AHBFeature 0 "OFF" 1 "ON" ;
VAL_ 1023 AHB_ON 0 "OFF" 1 "ON" ;
VAL_ 1058 OBC_OutputCurrent 1023 "Invalid" ;
VAL_ 1058 OBC_ProximityPilotStatus 0 "Unkown" 1 "Not_detected" 2 "Detected" 3 "Failure" ;
VAL_ 1058 OBC_ChrgrSt 0 "Undefined" 1 "Init" 2 "Idle" 3 "ConnectedWithoutPower" 4 "ConnectedWithPower" 5 "Charging" 6 "not_used" 7 "not_used" 8 "not_used" 9 "not_used" 10 "not_used" 11 "not_used" 12 "not_used" 13 "not_used" 14 "Sleep" 15 "Fault" ;
VAL_ 1058 OBC_OutputVoltage 16383 "Invalid" ;
VAL_ 1058 OBC_ControlPilotStatus 0 "Unkown" 1 "Not_detected" 2 "Detected" 3 "Failure" ;
VAL_ 1058 OBC_Temperature 0 "Invalid" ;
VAL_ 1058 OBC_LockMotorSts 0 "Unlocked" 1 "Locked" ;
VAL_ 1058 OBC_CoolantRequestLevel 0 "NoRequestForMoreCoolantPower" 1 "IncreaseLevel1ForMoreCoolantPwr" 2 "IncreaseLevel2ForMoreCoolantPwr" 3 "MaxCoolingPower" 4 "NotDefined" 5 "Not_used" 6 "Not_used" 7 "Not_used" ;
VAL_ 1060 HVB_ChargeCompleted 0 "Not_Active" 1 "Active" ;
VAL_ 1214 LVB_SOCSts 0 "OK" 1 "FLT" ;
VAL_ 1214 LVB_SOC 127 "SNA" ;
VAL_ 1214 LVB_MaxCellsTemp 255 "SNA" ;
VAL_ 1214 LVB_SOH 127 "SNA" ;
VAL_ 1214 LVB_MaxCellsTempFailsts 0 "Fail_not_Present" 1 "Fail_Present" ;
VAL_ 1214 LVB_IntegrityError 0 "Not_Present" 1 "Present" ;
VAL_ 1214 VoltageMonitoringEnable 0 "Not_Enable" 1 "Enabled" ;
VAL_ 1214 RecirculationReq 0 "No_Req" 1 "Req" ;
VAL_ 1214 LiIonBattWngOnDashBoard 0 "no_popup" 1 "virtual_popup_1" 2 "virtual_popup_2" 3 "virtual_popup_3" 4 "virtual_popup_4" 5 "virtual_popup_5" 6 "Not_used" 7 "Not_used" ;
VAL_ 1214 LVB_Relay_Status 0 "CLS" 1 "OPN_REQ" 2 "OPN" 3 "SNA" ;
VAL_ 1214 LVB_BatteryVoltage 255 "SNA" ;
VAL_ 1261 DMS_Attentiveness 0 "Status_not_available" 1 "Driver_inattentive" 2 "Driver_attentive" 3 "Not_used" ;
VAL_ 1261 DMSSystemFail 0 "not_fail" 1 "temp_fail" 2 "perma_fail" 3 "degraded" ;
VAL_ 1261 DMSSystemStatus 0 "Init" 1 "Off" 2 "On" 3 "Error" 4 "Calib_state" 5 "Not_used" 6 "Not_used" 7 "Not_used" ;
VAL_ 1261 HMICode_DMS 0 "not_active" 1 "visual" 2 "visual_acoustic" 3 "Degraded" ;
VAL_ 1261 CabinDivision 0 "Status_not_available" 1 "area1" 2 "area2" 3 "area3" ;
VAL_ 1261 NIR_Blocking_GlassesDetection 0 "Status_not_available" 1 "No_glasses_detection" 2 "glasses_detection" 3 "Not_used" ;
VAL_ 1261 DMS_DriverPresent 0 "Status_not_available" 1 "No_driver_present" 2 "Driver_present" 3 "Not_used" ;
VAL_ 1261 Nominal_condition 0 "Status_not_available" 1 "Nominal_condition" 2 "No_nominal_condition" 3 "Not_used" ;
VAL_ 1273 BlowerSpeed10L 0 "OFF" 1 "Blower_Level_1" 2 "Blower_Level_2" 3 "Blower_Level_3" 4 "Blower_Level_4" 5 "Blower_Level_5" 6 "Blower_Level_6" 7 "Blower_Level_7" 8 "Blower_Level_8" 9 "AUTO" 10 "Not_used" 11 "Not_used" 12 "Not_used" 13 "Not_used" 14 "Not_used" 15 "Not_used" ;
VAL_ 1273 AirConditionCompressor 0 "OFF" 1 "ON" ;
VAL_ 1286 AVHDisplayInfo 0 "No_Request_to_HMI" 1 "Not_used" 2 "Under_Intervention" 3 "Fail_Lamp_ON" ;
VAL_ 1286 HHCDisplayInfo 0 "No_Request_to_HMI" 1 "Fail_Lamp_ON" ;
VAL_ 1286 EBDDisplayInfo 0 "No_Request_to_HMI" 1 "Fail_Lamp_ON" ;
VAL_ 1286 ABSDisplayInfo 0 "No_Request_to_HMI" 1 "Fail_Lamp_ON" ;
VAL_ 1286 ESCOFFLampRequest 0 "No_Request_to_HMI" 1 "Fail_Lamp_ON" ;
VAL_ 1286 Reserved_AWDDisplayInfo 0 "No_Request_to_HMI" 1 "Fail_Lamp_ON" ;
VAL_ 1286 BrakeFluidLevelSts 0 "OK" 1 "Low_Level" ;
VAL_ 1286 NFRSts 0 "Init_" 1 "Normal_Operation" 2 "Degraded_" 3 "Error" 4 "RollBenchMode_Active" 5 "Not_used" 6 "BrakeBenchMode_Active" 7 "Not_used" 8 "DiagnosticSessionActive_on_NFR" 9 "Not_used" 10 "Not_available" 11 "Not_used" 12 "Not_used" 13 "Not_used" 14 "Not_used" 15 "Not_used" ;
VAL_ 1286 F1TCSDisplayInfo 0 "No_Request_to_HMI" 1 "Degraded_mode" 2 "Under_Intervention" 3 "Fail_Lamp_ON" ;
VAL_ 1286 EPBRemovePLRqtInfo 0 "Off" 1 "On" ;
VAL_ 1286 ThirdLightFaultSts 0 "No_Fault" 1 "Fault_Present" ;
VAL_ 1286 EPB_BrakePedalPressIndicationReq 0 "OFF" 1 "ON" ;
VAL_ 1286 EPB_BuzzerReq 0 "OFF" 1 "ON" ;
VAL_ 1286 LDIDisplayInfo 0 "No_Request_to_HMI" 1 "Enable" 2 "Under_Intervention" 3 "Fail_Lamp_On" 4 "Fail_Temp_Not_Available" 5 "Not_used" 6 "Not_used" 7 "Not_used" ;
VAL_ 1286 PBDisplayInfoValidData 0 "Valid" 1 "Not_valid" ;
VAL_ 1286 VDCDisplayInfo 0 "No_Request_to_HMI" 1 "Not_used" 2 "Under_Intervention" 3 "Fail_Lamp_ON" ;
VAL_ 1286 ServiceLampBlinkFreq 0 "No_blinking" 1 "Slow_Blinking_1_Hz" 3 "Fast_blinking_3_Hz" 7 "Signal_invalid" ;
VAL_ 1286 PBDisplayInfo 0 "Not_used" 1 "See_note" 2 "See_note" 3 "See_note" 4 "See_note" 5 "See_note" 6 "See_note" 7 "See_note" 8 "See_note" 9 "See_note" 10 "See_note" 11 "See_note" 12 "See_note" 13 "See_note" 14 "See_note" 15 "See_note" 16 "See_note" 17 "See_note" 18 "See_note" 19 "See_note" 20 "See_note" 21 "See_note" 22 "See_note" 23 "See_note" 24 "See_note" 25 "See_note" 26 "See_note" 27 "Not_used" 28 "Not_used" 29 "Not_used" 30 "Not_used" 31 "Not_used" ;
VAL_ 1286 FadeWarning 0 "Level_0_No_Fade" 1 "Level_1_Soft" 2 "Level_2_Critical" 3 "not_used" ;
VAL_ 1286 EPBDisplayEnable 0 "not_used" 1 "Enabled" 2 "Disabled" 3 "not_used" ;
VAL_ 1286 WarningLampReq 0 "OFF" 1 "ON" 2 "Not_used" 3 "Signal_invalid" ;
VAL_ 1286 ServiceLampReq 0 "OFF" 1 "ON" 2 "Not_used" 3 "Signal_invalid" ;
VAL_ 1286 EPBLifeCycleWarning 0 "OFF" 1 "ON" ;
VAL_ 1286 HDC_Pop_Up 0 "No_Visualization" 1 "HDC_Not_Available" 2 "HDC_ACC_Engaged" 3 "not_used" 4 "not_used" 5 "not_used" 6 "not_used" 7 "not_used" ;
VAL_ 1312 LowBeamSts_VEHSTAT 0 "OFF" 1 "ON" ;
VAL_ 1312 TurnIndicatorSts_CCAN1 0 "Center" 1 "Left" 2 "Right" 3 "SNA" ;
VAL_ 1312 KeySts 0 "Data_not_valid" 1 "STOP" 2 "PARK" 3 "Not_used" 4 "ON" 5 "Not_used" 6 "Not_used" 7 "Not_used" 8 "Not_used" 9 "Not_used" 10 "Not_used" 11 "Not_used" 12 "CRANK_ON" 13 "Not_used" 14 "Not_used" 15 "Not_used" ;
VAL_ 1312 LHRTurnLightFailSts 0 "Fail_Not_Present" 1 "Fail_Present" ;
VAL_ 1312 LHRParkTailLightFailSts 0 "Fail_Not_Present" 1 "Fail_Present" ;
VAL_ 1312 HazardLightSts 0 "OFF" 1 "ON" ;
VAL_ 1312 ADAS_heater 0 "Denied" 1 "Allowed" ;
VAL_ 1312 NBCFISSts 0 "Not_active" 1 "Active" ;
VAL_ 1312 StopLightFault 0 "False" 1 "True" ;
VAL_ 1312 AHBFeature 0 "OFF" 1 "ON" ;
VAL_ 1312 HighBeamSts_VEHSTAT 0 "OFF" 1 "ON" ;
VAL_ 1312 RHTurnSignalSts 0 "OFF" 1 "ON" ;
VAL_ 1312 RHStopLightFailSts 0 "Fail_Not_Present" 1 "Fail_Present" ;
VAL_ 1312 RHRTurnLightFailSts 0 "Fail_Not_Present" 1 "Fail_Present" ;
VAL_ 1312 RHRParkTailLightFailSts 0 "Fail_Not_Present" 1 "Fail_Present" ;
VAL_ 1312 RHFTurnLightFailSts 0 "Fail_Not_Present" 1 "Fail_Present" ;
VAL_ 1312 LHTurnSignalSts 0 "OFF" 1 "ON" ;
VAL_ 1312 LHStopLightFailSts 0 "Fail_Not_Present" 1 "Fail_Present" ;
VAL_ 1312 FrontWindshieldWiperMotErrSts 0 "Not_Active" 1 "Active" ;
VAL_ 1312 LHFTurnLightFailSts 0 "Fail_Not_Present" 1 "Fail_Present" ;
VAL_ 1312 NSVSts 0 "Down" 1 "Up" 2 "Moving" 3 "Not_Available" ;
VAL_ 1312 RLSWiperSpeed 0 "Off" 1 "Low_Speed" 2 "High_Speed" 3 "Not_used" 4 "Not_used" 5 "Not_used" 6 "RLS_Error" 7 "SNA" ;
VAL_ 1312 FrontWiperModeSts 0 "Stop" 1 "Moving" ;
VAL_ 1313 STS_DRS_DriverLatchsts 0 "init" 1 "Unlocked" 2 "Locked" 3 "SNA" ;
VAL_ 1313 STS_DRS_PsngrDoorSts 0 "SNA" 1 "close" 2 "Ajar" 3 "Open" ;
VAL_ 1313 STS_DRS_DriverDoorSts 0 "SNA" 1 "close" 2 "Ajar" 3 "Open" ;
VAL_ 1313 STS_DRS_VPSTrunkSts 0 "Closed_Unlocked" 1 "Closed_Locked" 2 "Open_Unlocked" 3 "Open_Locked" ;
VAL_ 1313 STS_DRS_RearRightLatchsts 0 "init" 1 "Unlocked" 2 "Locked" 3 "SNA" ;
VAL_ 1313 STS_DRS_RearLeftDoorSts 0 "SNA" 1 "close" 2 "Ajar" 3 "Open" ;
VAL_ 1313 STS_DRS_RearRightDoorSts 0 "SNA" 1 "close" 2 "Ajar" 3 "Open" ;
VAL_ 1313 STS_DRS_PsngrLatchsts 0 "init" 1 "Unlocked" 2 "Locked" 3 "SNA" ;
VAL_ 1313 STS_DRS_PsngrWindowSts 0 "Open" 1 "Close" 2 "Middle" 3 "Running_Up" 4 "Running_Down" 5 "Reverse" 6 "Short_drop" 7 "SNA" ;
VAL_ 1313 STS_DRS_DriverWindowSts 0 "Open" 1 "Close" 2 "Middle" 3 "Running_Up" 4 "Running_Down" 5 "Reverse" 6 "Short_drop" 7 "SNA" ;
VAL_ 1313 STS_DRS_VPSLockValidData 0 "Valid" 1 "Not_Valid" ;
VAL_ 1313 STS_DRS_RearLeftLatchsts 0 "init" 1 "Unlocked" 2 "Locked" 3 "SNA" ;
VAL_ 1313 STS_DRS_RearRightWindowSts 0 "Open" 1 "Close" 2 "Middle" 3 "Running_Up" 4 "Running_Down" 5 "Reverse" 6 "Short_drop" 7 "SNA" ;
VAL_ 1313 STS_DRS_RearLeftWindowSts 0 "Open" 1 "Close" 2 "Middle" 3 "Running_Up" 4 "Running_Down" 5 "Reverse" 6 "Short_drop" 7 "SNA" ;
VAL_ 1313 VPSDoorSts 0 "Locked_External" 1 "Locked_Internal" 2 "Unlocked_External" 3 "Unlocked_Internal" ;
VAL_ 1314 RefrigerantFluidTemp2FailSts 0 "Fail_not_Present" 1 "Fail_Present" ;
VAL_ 1314 RefrigerantFluidTemp1FailSts 0 "Fail_not_Present" 1 "Fail_Present" ;
VAL_ 1314 RefrigerantFluidPress2FailSts 0 "Fail_not_Present" 1 "Fail_Present" ;
VAL_ 1314 RefrigerantFluidPres1FailSts 0 "Fail_not_Present" 1 "Fail_Present" ;
VAL_ 1314 VoltageCntrl_LoadEnable 0 "FALSE" 1 "TRUE" ;
VAL_ 1314 RefrigerantFluidPressEVDCFailSts 0 "Fail_not_Present" 1 "Fail_Present" ;
VAL_ 1317 SetSpeed 255 "SNA" ;
VAL_ 1317 ActualSpeed 255 "SNA" ;
VAL_ 1317 Voltage 255 "SNA" ;
VAL_ 1317 Temperature 255 "SNA" ;
VAL_ 1317 Current 255 "SNA" ;
VAL_ 1317 OverTemperature 0 "No_overtemperature" 1 "Overtemperature" 2 "Not_used" 3 "SNA" ;
VAL_ 1317 HVB_Load_Enable_NCL 0 "Enable" 1 "Not_Enable" ;
VAL_ 1317 LT_WaterPumpRelayFailSts 0 "Fail_not_Present" 1 "Fail_Present" ;
VAL_ 1317 Stepmode 0 "rotation_monitoring_active" 1 "No_rotation_monitoring" 2 "Not_used" 3 "Signal_invalid" ;
VAL_ 1317 LT_WaterPumpRelaySts 0 "Open" 1 "Close" 2 "Opened_Stuck" 3 "Closed_Stuck" ;
VAL_ 1317 Deblocking 0 "Deblocking_not_active" 1 "Deblocking_active" 2 "Not_used" 3 "SNA" ;
VAL_ 1317 VoltageError 0 "No_Voltage_Error" 1 "Voltage_Error_Detected" 2 "Not_used" 3 "SNA" ;
VAL_ 1317 DryRun 0 "No_dry_run_detected" 1 "Dry_run_detected" 2 "Not_used" 3 "SNA" ;
VAL_ 1317 OverCurrent 0 "No_overcurrent" 1 "Overcurrent_occurred" 2 "Not_used" 3 "SNA" ;
VAL_ 1317 CommunicationError 0 "No_error" 1 "Error" ;
VAL_ 1317 StatusPostRunningMode 0 "No_post_running" 1 "Active_post_Run" 2 "Active_post_Run" 3 "Active_post_Run" 4 "Active_post_Run" 5 "Variable_Post_Run" 6 "Not_used" 7 "SNA" ;
VAL_ 1317 EOBDII_FailureCleaningRqt 0 "NO_Cleaning_Request" 1 "Cleaning_Request" ;
VAL_ 1317 EOBDII_SecondaryNodes 0 "None" 1 "NBC" 2 "NCL" 3 "OBC" 4 "PCU" 5 "Not_used" 6 "Not_used" 7 "Not_used" ;
VAL_ 1318 StopLightActRqt 0 "Stop_Light_switched_OFF" 1 "Stop_Light_switched_ON" ;
VAL_ 1318 BrakePedalSts 0 "Not_Pressed" 1 "Pressed" ;
VAL_ 1318 BrakePedalValidData 0 "Valid_QM" 1 "Not_valid" 2 "Valid_ASIL" 3 "Not_used" ;
VAL_ 1318 BrakePressureActualValidData 0 "Valid_QM" 1 "Not_valid" 2 "Valid_ASIL" 3 "Not_used" ;
VAL_ 1318 DriverBrkPressureRqtValidData 0 "Valid_QM" 1 "Not_valid" 2 "Valid_ASIL" 3 "Not_used" ;
VAL_ 1318 BrakePressureTargetValidData 0 "Valid_QM" 1 "Not_valid" 2 "Valid_ASIL" 3 "Not_used" ;
VAL_ 1318 BrakeRodStrokeValidData 0 "Valid_QM" 1 "Not_valid" 2 "Valid_ASIL" 3 "Not_used" ;
VAL_ 1323 EngineWarmingInProgress 0 "Not_Active" 1 "Active" ;
VAL_ 1323 HManettinoTransitionInfo 0 "No_Transition" 1 "Denied_due_to_low_HVB_SOC" 2 "No_Enough_Power_from_HVB" 3 "Not_used" 4 "Not_used" 5 "Not_used" 6 "Not_used" 7 "Not_used" ;
VAL_ 1323 HManettinoFailSts 0 "Fail_Not_Present" 1 "Fail_Present" ;
VAL_ 1323 HManettinoSts 0 "Not_used" 1 "EDrive" 2 "Hybrid" 3 "Performance" 4 "Qualifying" 5 "Not_used" 6 "Not_used" 7 "Not_used" ;
VAL_ 1323 LimpHomeWarningSts 0 "message_1" 1 "message_2" 2 "message_3" 3 "message_4" 4 "message_5" 5 "message_6" 6 "message_7" 7 "message_8" 8 "message_9" 9 "message_10" 10 "message_11" 11 "message_12" 12 "message_13" 13 "message_14" 14 "message_15" 15 "message_16" ;
VAL_ 1323 FuelTankFlapEnable 0 "Not_Enabled" 1 "Enabled" 2 "Not_Enabled_Fail" 3 "FTIV_Fail_Stop" ;
VAL_ 1323 EfficiencyMode 0 "Normal" 1 "Hold" 2 "Recharge" 3 "Not_used" ;
VAL_ 1323 P2_To_Wheel 0 "Not_Active_Lamp" 1 "Lamp_Boost" 2 "Lamp_Reg" 3 "Not_used" ;
VAL_ 1323 HybridLimpHomeSts 0 "LimpHomeMessage1" 1 "LimpHomeMessage2" 2 "LimpHomeMessage3" 3 "LimpHomeMessage4" 4 "LimpHomeMessage5" 5 "LimpHomeMessage6" 6 "LimpHomeMessage7" 7 "LimpHomeMessage8" ;
VAL_ 1323 START_ButtonPress_Rqt 0 "No_Visualization" 1 "Pressure" 2 "Pressure_and_hold" 3 "Not_used" ;
VAL_ 1323 P2_To_HVB 0 "Not_Active_Lamp" 1 "Lamp_Boost" 2 "Lamp_Reg" 3 "Not_used" ;
VAL_ 1323 eDriveStsForNqs 0 "eDrive" 1 "S_E_S" 2 "No_eDrive" 3 "NO_EDRIVE_NO_S_E_S" ;
VAL_ 1323 Engine_To_P2 0 "Not_Active_Lamp" 1 "Active_Lamp" ;
VAL_ 1323 MAX_PWR 0 "_0" 1 "_10" 2 "_20" 3 "_40" 4 "_60" 5 "_80" 6 "_100" 7 "SNA" ;
VAL_ 1323 Engine_To_Wheel 0 "Not_Active_Lamp" 1 "Active_Lamp" ;
VAL_ 1323 P2_To_P4 0 "Not_Active_Lamp" 1 "Active_Lamp" ;
VAL_ 1323 VehicleStartNotAllowed 0 "Not_Active" 1 "Active" ;
VAL_ 1323 HVB_Lamp 0 "Not_Active_Lamp" 1 "Lamp_ON" 2 "Lamp_Discharge" 3 "Lamp_Recharge" ;
VAL_ 1323 P4_To_HVB 0 "Not_Active_Lamp" 1 "Lamp_Boost" 2 "Lamp_Reg" 3 "Not_used" ;
VAL_ 1323 P4_To_Wheel 0 "Not_Active_Lamp" 1 "Lamp_Boost" 2 "Lamp_Reg" 3 "Not_used" ;
VAL_ 1323 ICE_Lamp 0 "Not_Active_Lamp" 1 "Active_Lamp" ;
VAL_ 1323 OverboostStatus 0 "normal" 1 "overboost_active" 2 "derated" 3 "Enabled" ;
VAL_ 1323 OverboostLevel_NQS 63 "Fail" ;
VAL_ 1351 HALF_CHIME_TYPESts 0 "None" 1 "Audio_01" 2 "Audio_02" 3 "Audio_03" 4 "Audio_04" 5 "Audio_05" 6 "Half_Chime" 7 "not_used" 8 "not_used" 9 "not_used" 10 "not_used" 11 "not_used" 12 "not_used" 13 "not_used" 14 "not_used" 15 "SNA" ;
VAL_ 1351 TSR_Fault 0 "OFF" 1 "ON" ;
VAL_ 1351 TSR_ON 0 "OFF" 1 "ON" ;
VAL_ 1351 LDWSystemSts 0 "OFF" 1 "ON" 2 "Init" 3 "Not_used" ;
VAL_ 1351 StatusLKA 0 "OFF" 1 "LKA_ON" 2 "LDW_ON" 3 "Init" ;
VAL_ 1351 AHBSensitivitySts 0 "Init" 1 "Low" 2 "High" 3 "Not_used" ;
VAL_ 1351 LDWSensitivitySts 0 "Early" 1 "Med" 2 "Late" 3 "Init" ;
VAL_ 1351 HALF_RF_CHIME_RQSts 0 "False" 1 "True" ;
VAL_ 1351 HALF_LF_CHIME_RQSts 0 "False" 1 "True" ;
VAL_ 1351 TSA_ON 0 "Init" 1 "OFF" 2 "Visual" 3 "Visual_Acoustic" ;
VAL_ 1351 HandsOnSts 0 "OFF" 1 "Yellow" 2 "Red" 3 "Green" 4 "NO_HANDS_ON_STR_WHEEL_YELLOW" 5 "NO_HANDS_ON_STR_WHEEL_RED" 6 "NoDisplay" 7 "Not_Valid" ;
VAL_ 1351 StatusDDA 0 "Init" 1 "Enable" 2 "Not_Enable" 3 "not_used" ;
VAL_ 1351 LDW_Intensity_fbk 0 "Low" 1 "Med" 2 "High" 3 "Init" ;
VAL_ 1351 ADAS_Unavailable_Camera 0 "No_Code" 1 "Camera_Blinded_ADAS_unavailable" 2 "Camera_Fail_ADAS_unavailable" 3 "SNA" ;
VAL_ 1351 TSAMainSign2Fbk 0 "Init" 1 "OFF" 2 "ON" 3 "Not_used" ;
VAL_ 1351 TSASignChangeFbk 0 "Init" 1 "OFF" 2 "ON" 3 "Not_used" ;
VAL_ 1351 DDAW_Level 0 "None" 1 "Level_1" 2 "Level_2" 3 "Level_3" 4 "Level_4" 5 "Level_5" 6 "Level_6" 7 "Level_7" 8 "Level_8" 9 "Level_9" 10 "Level_10" 11 "Not_used" 12 "Not_used" 13 "Not_used" 14 "Not_used" 15 "Not_used" ;
VAL_ 1351 DrowsinessSts 0 "LAMP_ON" 1 "LAMP_OFF" 2 "Failure" 3 "Not_Available" ;
VAL_ 1351 LDWWarningType_fbk 0 "Acoustic" 1 "Vibration" 2 "Acoustic_Vibration" 3 "Init" ;
VAL_ 1351 DisplaySts 0 "LaneSense_OFF" 1 "LaneSense_ON_HF_NotA" 2 "SingleLine_Left" 3 "SingleLine_Right" 4 "ON_HF_NotA_NHTSA_on_Left" 5 "ON_HF_NotA_NHTSA_on_Right" 6 "ON_HF_Armed" 7 "ON_HF_Left_SingleLine_Left" 8 "ON_HF_Left_Side" 9 "ON_HF_Right_SingleLine_Right" 10 "ON_HF_Right_Side" 11 "ON_HF_Left_NHTSA_Left" 12 "ON_HF_Right_NHTSA_Right" 13 "ON" 14 "ON_HF_LKA_on_Left" 15 "ON_HF_LKA_on_Right" 16 "Not_used" 17 "LKA_UNAVAILABLE" 18 "Not_used" 19 "Not_used" 20 "Not_used" 21 "Not_used" 22 "Not_used" 23 "Not_used" 24 "Not_used" 25 "Not_used" 26 "Not_used" 27 "Not_used" 28 "Not_used" 29 "Not_used" 30 "Not_used" 31 "Not_used" 32 "Not_used" 33 "Not_used" 34 "Not_used" 35 "Not_used" 36 "Not_used" 37 "Not_used" 38 "Not_used" 39 "Not_used" 40 "Not_used" 41 "Not_used" 42 "Not_used" 43 "Not_used" 44 "Not_used" 45 "Not_used" 46 "Not_used" 47 "Not_used" 48 "Not_used" 49 "Not_used" 50 "Not_used" 51 "Not_used" 52 "Not_used" 53 "Not_used" 54 "Not_used" 55 "Not_used" 56 "Not_used" 57 "Not_used" 58 "Not_used" 59 "Not_used" 60 "Not_used" 97 "ON_HF_NotA_NoHands" 98 "SingleLine_Left_marker_NoHands" 99 "SingleLine_Right_marker_NoHands" 100 "ON_HF_NotA_NHTSA_on_Left_NoHand" 101 "ON_HF_NotA_NHTSA_on_Right_NoHand" 102 "ON_HF_Armed_NoHands" 103 "ON_HF_Left_SingleLineLeft_NoHand" 104 "ON_HF_Left_NoHands" 105 "ON_HF_Right_SingleLine_R_NoHand" 106 "ON_HF_Right_NoHands" 107 "ON_HF_Left_NHTSA_on_Left_NoHand" 108 "ON_HF_Right_NHTSA_on_R_NoHand" 109 "Not_used" 110 "Not_used" 111 "Not_used" 112 "Not_used" 113 "Not_used" 114 "Not_used" 115 "Not_used" 116 "Not_used" 117 "Not_used" 118 "Not_used" 119 "Not_used" 120 "Not_used" 121 "Not_used" 122 "Not_used" 123 "Not_used" 124 "Not_used" 125 "Not_used" 126 "Not_used" 127 "Not_used" 128 "Not_used" 129 "Not_used" 130 "Not_used" 131 "Not_used" 132 "Not_used" 133 "Not_used" 134 "Not_used" 135 "Not_used" 136 "Not_used" 137 "Not_used" 138 "Not_used" 139 "Not_used" 140 "Not_used" 141 "Not_used" 142 "Not_used" 143 "Not_used" 144 "Not_used" 145 "Not_used" 146 "Not_used" 147 "Not_used" 148 "Not_used" 149 "Not_used" 150 "Not_used" 151 "Not_used" 152 "Not_used" 153 "Not_used" 154 "Not_used" 155 "Not_used" 156 "Not_used" 157 "Not_used" 158 "Not_used" 159 "Not_used" 160 "Sensor_Blinded" 161 "LaneSense_Temp_Unavailable" 162 "Blinded_LaneSense_AHBC_ON" 163 "Not_used" 164 "Not_used" 165 "Not_used" 166 "Not_used" 167 "Not_used" 168 "Not_used" 169 "Not_used" 170 "Not_used" 171 "Not_used" 172 "Not_used" 173 "Not_used" 174 "Not_used" 175 "Not_used" 176 "Not_used" 177 "Not_used" 178 "Not_used" 179 "Not_used" 180 "Not_used" 181 "Not_used" 182 "Not_used" 183 "Not_used" 184 "Not_used" 185 "Not_used" 186 "Not_used" 187 "Not_used" 188 "Not_used" 189 "Not_used" 190 "Not_used" 191 "Not_used" 192 "Not_used" 193 "Not_used" 194 "Not_used" 195 "Not_used" 196 "Not_used" 197 "Not_used" 198 "Not_used" 199 "Not_used" 200 "Not_used" 201 "Not_used" 202 "Not_used" 203 "Not_used" 204 "Not_used" 205 "Not_used" 206 "Not_used" 207 "Not_used" 208 "Not_used" 209 "Not_used" 210 "Not_used" 211 "Not_used" 212 "Not_used" 213 "Not_used" 214 "Not_used" 215 "Not_used" 216 "Not_used" 217 "Not_used" 218 "Not_used" 219 "Not_used" 220 "Not_used" 221 "Not_used" 222 "Not_used" 223 "Not_used" 224 "Not_used" 225 "Not_used" 226 "Not_used" 227 "Not_used" 228 "Not_used" 229 "Not_used" 230 "Not_used" 231 "Not_used" 232 "Not_used" 233 "Not_used" 234 "Not_used" 235 "Not_used" 236 "Not_used" 237 "Not_used" 238 "Not_used" 239 "Not_used" 240 "LaneSense_Fault" 241 "Not_used" 242 "Not_used" 243 "Not_used" 244 "Not_used" 245 "Not_used" 246 "Not_used" 247 "Not_used" 248 "Not_used" 249 "Not_used" 250 "Not_used" 251 "Not_used" 252 "Not_used" 253 "Not_used" 254 "Not_used" 255 "SNA" ;
VAL_ 1351 SensorBlinded 0 "OFF" 1 "ON" ;
VAL_ 1351 AHBFault 0 "OFF" 1 "ON" ;
VAL_ 1351 AHB_ON 0 "OFF" 1 "ON" ;
VAL_ 1351 TSR_Sts 0 "init" 1 "Operative" ;
VAL_ 1351 HALF_heaterSts 0 "Inactive" 1 "Active" ;
VAL_ 1351 DDAW_Index 511 "SNA" ;
VAL_ 1360 NBC_DTCStatus_byte0 0 "Not_Supported" 1 "Critically_Disabled" 2 "No_Status_No_Report" 3 "Diagnostic_Passed" 4 "Diagnostic_Failed" 5 "TestFailed" 6 "TestNotCompletedThisCycle" 7 "Reserved" ;
VAL_ 1360 NBC_DTCStatus_byte1 0 "Not_Supported" 1 "Critically_Disabled" 2 "No_Status_No_Report" 3 "Diagnostic_Passed" 4 "Diagnostic_Failed" 5 "TestFailed" 6 "TestNotCompletedThisCycle" 7 "Reserved" ;
VAL_ 1360 NBC_DTCStatus_byte2 0 "Not_Supported" 1 "Critically_Disabled" 2 "No_Status_No_Report" 3 "Diagnostic_Passed" 4 "Diagnostic_Failed" 5 "TestFailed" 6 "TestNotCompletedThisCycle" 7 "Reserved" ;
VAL_ 1360 NBC_DTCStatus_byte3 0 "Not_Supported" 1 "Critically_Disabled" 2 "No_Status_No_Report" 3 "Diagnostic_Passed" 4 "Diagnostic_Failed" 5 "TestFailed" 6 "TestNotCompletedThisCycle" 7 "Reserved" ;
VAL_ 1360 NBC_DTCStatus_byte4 0 "Not_Supported" 1 "Critically_Disabled" 2 "No_Status_No_Report" 3 "Diagnostic_Passed" 4 "Diagnostic_Failed" 5 "TestFailed" 6 "TestNotCompletedThisCycle" 7 "Reserved" ;
VAL_ 1360 NBC_DTCStatus_byte5 0 "Not_Supported" 1 "Critically_Disabled" 2 "No_Status_No_Report" 3 "Diagnostic_Passed" 4 "Diagnostic_Failed" 5 "TestFailed" 6 "TestNotCompletedThisCycle" 7 "Reserved" ;
VAL_ 1360 NBC_OBD_Err_Cancel_Req 0 "No_Request" 1 "ERR_Cancel_Request" ;
VAL_ 1376 IncreaseIdleSpeedReq_2 1 "ON" 0 "OFF" ;
VAL_ 1376 VDCLamp_FailSts 0 "OFF_Fail_not_present" 1 "OFF_Fail_present" 2 "ON_Fail_not_present" 3 "Not_used" ;
VAL_ 1376 TC_ASRLamp_FailSts 0 "OFF_Fail_not_present" 1 "OFF_Fail_present" 2 "ON_Fail_not_present" 3 "Not_used" ;
VAL_ 1376 EBDLamp_FailSts 0 "OFF_Fail_not_present" 1 "OFF_Fail_present" 2 "ON_Fail_not_present" 3 "Not_used" ;
VAL_ 1376 ABSLamp_FailSts 0 "OFF_Fail_not_present" 1 "OFF_Fail_present" 2 "ON_Fail_not_present" 3 "Not_used" ;
VAL_ 1376 LifterButtonValidData 0 "Valid" 1 "Not_Valid" ;
VAL_ 1376 TrunkSts 0 "Closed" 1 "Open" ;
VAL_ 1376 ReverseGearBCSts 0 "Not_inserted" 1 "Inserted" ;
VAL_ 1376 LifterButtonSts 0 "Not_Pressed" 1 "Pressed" ;
VAL_ 1376 AutoEPBButtonSts 0 "Not_Active" 1 "Active" ;
VAL_ 1376 SimpleCapoteSts 0 "Closed" 1 "Open" ;
VAL_ 1376 PowerModeSts 0 "Standard_Power" 1 "Logistic_Mode_ON" 2 "Logistic_Mode_PR" 3 "Not_used" ;
VAL_ 1376 TrunkReleaseReqCntrl 0 "Not_active" 1 "Active" ;
VAL_ 1376 BackWindowSts 0 "Completely_Open" 1 "Middle_position" 2 "No_Command" 3 "Completely_Closed" ;
VAL_ 1376 DriverDoorSts 0 "Closed" 1 "Open" ;
VAL_ 1376 KeySts 0 "Data_not_valid" 1 "STOP" 2 "PARK" 3 "Not_used" 4 "ON" 5 "Not_used" 6 "Not_used" 7 "Not_used" 8 "Not_used" 9 "Not_used" 10 "Not_used" 11 "Not_used" 12 "CRANK_ON" 13 "Not_used" 14 "Not_used" 15 "Not_used" ;
VAL_ 1376 ExternalTemperature 0 "FaultValue" ;
VAL_ 1376 FuelLevelFailSts 0 "Fail_Not_Present" 1 "Fail_Present" ;
VAL_ 1376 RawNourriceLevel 0 "Normal" 1 "Low" ;
VAL_ 1376 IncreaseIdleSpeedReq 0 "OFF" 1 "ON" ;
VAL_ 1376 CompressorACReqSts 0 "Not_Active" 1 "Active" ;
VAL_ 1376 LowNourriceLevel 0 "Normal" 1 "Low" ;
VAL_ 1376 EngineBonnetSts 0 "Closed" 1 "Open" ;
VAL_ 1376 RemoteDoorUnlock 0 "Driver" 1 "All" ;
VAL_ 1376 ExternalTemperatureFailSts 0 "Fail_Not_Present" 1 "Fail_Present" ;
VAL_ 1376 FOBSearchRequest 0 "NO_ACTION" 1 "REQUEST_SEARCH" 2 "RESULT_RECEIVED" 3 "RESERVED" ;
VAL_ 1376 TheftAlarmStatus 0 "VTA_DISARM" 1 "VTA_PREARM" 2 "VTA_ARM" 3 "VTA_LGT" 4 "VTA_LGT_HORN" 5 "VTA_TAMP" 6 "VTA_ITM_Alarm" 7 "SNA" ;
VAL_ 1376 SnowChainMode 0 "Not_Active" 1 "Active" ;
VAL_ 1376 NTPCalibrationReqSts 0 "no_Request" 1 "Request" ;
VAL_ 1376 NBCStopStartButtonSts 0 "Stop_E_Start_OFF" 1 "Stop_E_Start_ON" ;
VAL_ 1376 PsngDoorSts 0 "Closed" 1 "Open" ;
VAL_ 1376 BCANAutoStopFailSts 0 "No_fail" 1 "NCL_fail" 2 "NQS_fail" 3 "NQS_NCL_fail" 4 "NCP_fail" 5 "NCP_NCL_fail" 6 "NCP_NQS_fail" 7 "NCP_NQS_NCL_fail" 8 "NBC_fail" 9 "NBC_NCL_fail" 10 "NBC_NQS_fail" 11 "NBC_NQS_NCL_fail" 12 "NBC_NCP_fail" 13 "NBC_NCP_NCL_fail" 14 "NBC_NCP_NQS_fail" 15 "NBC_NCP_NQS_NCL_fail" ;
VAL_ 1376 BCANAutoStopStaySts 0 "RecrankEngine" 1 "RemainStop" ;
VAL_ 1376 BCANAutoStopEnableSts 0 "Disable" 1 "Enable" ;
VAL_ 1377 GenericFailSts_STATUS_C_NCM 0 "No_functional_fail_is_present" 1 "At_least_one_funct_fail_pres" ;
VAL_ 1377 CurrentFailSts 0 "No_functional_fail_is_present" 1 "DTCStatus_present" ;
VAL_ 1377 EOL 0 "No_EOL_prog_At_FIAT" 1 "EOL_prog_At_FIAT" ;
VAL_ 1377 D_ES 0 "Error_Active_State" 1 "Error_Passive_Warning_State" 2 "Bus_Off_State" 3 "Not_used" ;
VAL_ 1377 CCSpeedWarning 0 "No_Warning" 1 "CCSpeedReducedByEDrive" 2 "MaxCCSpeedReachedForEDrive" 3 "CCNotAvailable" ;
VAL_ 1377 LiIonBattWngOnDashBoard 0 "no_popup" 1 "virtual_popup_1" 2 "virtual_popup_2" 3 "virtual_popup_3" 4 "virtual_popup_4" 5 "virtual_popup_5" 6 "Not_used" 7 "Not_used" ;
VAL_ 1377 GeneralDenominator 0 "Denominetor_not_increase" 1 "Denominetor_increase" ;
VAL_ 1377 OilPressureFailSts 0 "Fail_Not_Present" 1 "Fail_Present" ;
VAL_ 1377 OilPressureSts 0 "Normal_Pressure" 1 "Low_Pressure" ;
VAL_ 1377 EngineWaterTempWarningLightSts 0 "OFF" 1 "ON" ;
VAL_ 1377 EngineBonnetSts2_LH 0 "Closed" 1 "Open" ;
VAL_ 1377 EngineWaterTempFailSts 0 "Fail_Not_Present" 1 "Fail_Present" ;
VAL_ 1377 EMSFailSts 0 "Fail_Not_Present" 1 "Fail_Flash_Light_Indication" 2 "Fail_Fix_Light_Indication" 3 "Not_used" ;
VAL_ 1377 LimpHomeSts 0 "Not_Active" 1 "Active" ;
VAL_ 1377 CompressorSts 0 "Not_used" 1 "Not_inserted_by_NCM" 2 "Not_inserted_by_driver_or_secur" 3 "Inserted" ;
VAL_ 1377 SlowDownSts 0 "Fail_Not_Present" 1 "High_Temperature" 2 "FailPresent" 3 "Very_High_Temperature" ;
VAL_ 1377 ShiftIndicatorLightSts 0 "Light_Indication_off" 1 "Flashing_Light_Indication" 2 "Fix_Light_Indication" 3 "Not_used" ;
VAL_ 1377 OilLevelSts 0 "Normal_Level" 1 "Out_of_Level" ;
VAL_ 1377 EngineSpeedValidData 0 "Valid" 1 "Not_valid" ;
VAL_ 1377 FuelConsumptionValidData 0 "Valid" 1 "Not_valid" ;
VAL_ 1377 BatteryDisconnectionWarning 0 "Not_Active" 1 "Active" ;
VAL_ 1382 GenericFailSts_STATUS_C_NFR 0 "No_functional_fail_is_present" 1 "At_least_one_funct_fail_pres" ;
VAL_ 1382 CurrentFailSts 0 "No_functional_fail_is_present" 1 "DTCStatus_present" ;
VAL_ 1382 EOL 0 "No_EOL_prog_At_FIAT" 1 "EOL_prog_At_FIAT" ;
VAL_ 1382 DES 0 "Error_Active_State" 1 "Error_Passive_Warning_State" 2 "Bus_Off_State" 3 "Not_used" ;
VAL_ 1382 OversteerTendencyValidData 0 "Valid" 1 "Not_valid" ;
VAL_ 1382 MiniSpareDetection 0 "On" 1 "Disabled" ;
VAL_ 1382 TireToleranceCompensation 0 "On" 1 "Disabled" ;
VAL_ 1382 AutoEPBEnable 0 "Disabled" 1 "Enabled" 2 "Disable_Denied" 3 "Automatic_Enabled" ;
VAL_ 1382 R_OdometerPulseCounterFailSts 0 "Fail_Not_Present" 1 "Fail_Present" ;
VAL_ 1382 L_OdometerPulseCounterFailSts 0 "Fail_Not_Present" 1 "Fail_Present" ;
VAL_ 1386 GenericFailSts_STATUS_C_NAM 0 "No_functional_fail_is_present" 1 "At_least_one_funct_fail_pres" ;
VAL_ 1386 CurrentFailSts 0 "No_functional_fail_is_present" 1 "DTCStatus_present" ;
VAL_ 1386 EOL 0 "No_EOL_prog_At_FIAT" 1 "EOL_prog_At_FIAT" ;
VAL_ 1386 D_ES 0 "Error_Active_State" 1 "Error_Passive_Warning_State" 2 "Bus_Off_State" 3 "Not_used" ;
VAL_ 1386 NAMInfoForDisplay 0 "No_visualizations" 1 "NAM_not_available_low_temp_" 2 "Fail_present" 3 "Not_used" ;
VAL_ 1386 NAMFailSts 0 "No_fail" 1 "Fail" ;
VAL_ 1387 GenericFailSts_STATUS_C_NCA_NCR 0 "No_functional_fail_is_present" 1 "At_least_one_funct_fail_pres" ;
VAL_ 1387 CurrentFailSts 0 "No_functional_fail_is_present" 1 "DTCStatus_present" ;
VAL_ 1387 EOL 0 "No_EOL_prog_At_FIAT" 1 "EOL_prog_At_FIAT" ;
VAL_ 1387 D_ES 0 "Error_Active_State" 1 "Error_Passive_Warning_State" 2 "Bus_Off_State" 3 "Not_used" ;
VAL_ 1387 ShiftModeSts 0 "Manual" 1 "Automatic" ;
VAL_ 1387 Automatic_RoboticXmsnFailSts 0 "Fail_Not_Present" 1 "Fail_Present" ;
VAL_ 1387 ActualGearForDisplay 0 "Not_coded" 1 "_1st_gear" 2 "_2nd_gear" 3 "_3rd_gear" 4 "_4th_gear" 5 "_5th_gear" 6 "_6th_gear" 7 "_7th_gear" 8 "'8th gear'" 9 "Not_used" 10 "Not_used" 11 "'P'" 12 "'D'" 13 "'L'" 14 "'R'" 15 "'N'" ;
VAL_ 1387 NCDFailSts 0 "Lamps_Off_Fail_not_present" 1 "Amber_Lamp_On_Fail_present" 2 "Amber_Lamp_On_Fail_present" 3 "Red_Lamp_On_Fail_present" ;
VAL_ 1387 AutoEPBInhibitionReq 0 "Not_Active" 1 "Active" ;
VAL_ 1387 BuzzerReqSts 0 "OFF" 1 "Reverse_gear_sound_ON" 2 "Others_case_sound_ON" 3 "ParkLock_not_Inserted" ;
VAL_ 1387 GearIndicationSts 0 "Normal" 1 "Blinking" ;
VAL_ 1387 AutomaticRoboticXmsnDegradedMode 0 "Not_active" 1 "Active" ;
VAL_ 1387 PerformanceLaunchMode 0 "Not_active" 1 "Active" ;
VAL_ 1387 RoboticTransmissionWarning 0 "No_warning" 1 "Press_brake_pedal_warning" 2 "Tip_not_available_warning" 3 "Lower_gear_shifts_warning" 4 "Manual_mode_not_avail_warn" 5 "Insert_N_warning" 6 "Automatic_mode_not_avail_warning" 7 "Delayed_start_up_warning" 8 "Clutch_over_temperature" 9 "Manoeuvre_not_allowed_warning" 10 "Press_brake_pedal_and_repeat_man" 11 "F1_pump_overheating_lower_gear" 12 "Parking_lock_not_inserted" 13 "Carwash_mode_activation" 14 "Disengage_parklock_request" 15 "Creeping_Deactivation" 16 "SuperCapWarning" 17 "Not_used" 18 "Not_used" 19 "Not_used" 20 "Not_used" 21 "Not_used" 22 "Not_used" 23 "Not_used" 24 "Not_used" 25 "Not_used" 26 "Not_used" 27 "Not_used" 28 "Not_used" 29 "Not_used" 30 "Not_used" 31 "Not_used" 32 "Not_used" 33 "Not_used" 34 "Not_used" 35 "Not_used" 36 "Not_used" 37 "Not_used" 38 "Not_used" 39 "Not_used" 40 "Not_used" 41 "Not_used" 42 "Not_used" 43 "Not_used" 44 "Not_used" 45 "Not_used" 46 "Not_used" 47 "Not_used" 48 "Not_used" 49 "Not_used" 50 "Not_used" 51 "Not_used" 52 "Not_used" 53 "Not_used" 54 "Not_used" 55 "Not_used" 56 "Not_used" 57 "Not_used" 58 "Not_used" 59 "Not_used" 60 "Not_used" 61 "Not_used" 62 "Not_used" 63 "Not_used" ;
VAL_ 1387 PLockSts 0 "Not_Engaged" 1 "Engaged" 2 "Fail" 3 "Not_used" ;
VAL_ 1387 NCR_EPB_Req 0 "Not_Req" 1 "Req" ;
VAL_ 1387 SailingAct 0 "Not_active" 1 "Active" ;
VAL_ 1390 InletWaterTemp_Target 63 "SNA" ;
VAL_ 1390 InletWaterTemp_InOut_Target 63 "SNA" ;
VAL_ 1390 OutletWaterTemperatureFailsts 0 "Fail_Not_Present" 1 "Fail_Present" ;
VAL_ 1390 InletWaterTemperatureFailSts 0 "Fail_Not_Present" 1 "Fail_Present" ;
VAL_ 1391 GenericFailSts_STATUS_C_NYL 0 "No_functional_fail_is_present" 1 "At_least_one_funct_fail_pres" ;
VAL_ 1391 CurrentFailSts 0 "No_functional_fail_is_present" 1 "DTCStatus_present" ;
VAL_ 1391 EOL 0 "No_EOL_prog_At_FIAT" 1 "EOL_prog_At_FIAT" ;
VAL_ 1391 D_ES 0 "Error_Active_State" 1 "Error_Passive_Warning_State" 2 "Bus_Off_State" 3 "Not_used" ;
VAL_ 1394 ADCGenericFailSts 0 "No_functional_fail_is_present" 1 "At_least_one_funct_failure" ;
VAL_ 1394 ADCCurrentFailSts 0 "No_functional_fail_is_present" 1 "DTCStatus_present" ;
VAL_ 1394 EOL_ADC 0 "No_EOL_prog_at_FIAT" 1 "EOL_prog_at_FIAT" ;
VAL_ 1394 DES_ADC 0 "Error_active_state" 1 "Error_Passive_warning_state" 2 "Bus_off_state" 3 "Not_used" ;
VAL_ 1394 ADC_InternalSts 0 "Init" 1 "Shut_Down" 2 "Stand_by" 3 "Mute" 4 "Partial_Operation" 5 "Full_Operation" 6 "Fault" 7 "Not_used" ;
VAL_ 1394 AUDIOSts_Telematic 0 "Initialization" 1 "Available" 2 "Not_Available" 3 "Not_used" ;
VAL_ 1394 ADC_ESEFailSts 0 "Fail_not_present" 1 "Fail_Present" ;
VAL_ 1394 ADC_PowerModeSts 0 "Standard_Power" 1 "Logistic_Mode_ON" 2 "Logistic_Mode_PR" 3 "Not_used" ;
VAL_ 1394 NWSFailSts 0 "Fail_not_present" 1 "Fail_Present" ;
VAL_ 1394 AvasAlertSound 0 "Off" 1 "On" ;
VAL_ 1395 GenericFailSts_STATUS_C_NSV 0 "No_functional_fail_is_present" 1 "At_least_one_funct_fail_pres" ;
VAL_ 1395 CurrentFailSts 0 "No_functional_fail_is_present" 1 "DTCStatus_present" ;
VAL_ 1395 EOL 0 "No_EOL_prog_At_FIAT" 1 "EOL_prog_At_FIAT" ;
VAL_ 1395 D_ES 0 "Error_Active_State" 1 "Error_Passive_Warning_State" 2 "Bus_Off_State" 3 "Not_used" ;
VAL_ 1395 VehicleLifterBuzzerReq 0 "No_acoustic_signal" 1 "Lifter_inhibited_or_End_lowering" 2 "End_of_raising_sequence" 3 "Vehicle_lifter_failure" ;
VAL_ 1395 VehicleLifterSts 0 "Down" 1 "Moving_Up" 2 "Moving_Down" 3 "Up" 4 "Inhibited" 5 "Not_used" 6 "Not_used" 7 "Unknown" ;
VAL_ 1395 VehicleLifterFailSts 0 "Fail_not_present" 1 "Minor_Error" 2 "Critical_Error" 3 "Not_used" ;
VAL_ 1395 NSVAutoStopFailSts 0 "Fail_Not_Present" 1 "Fail_Present" ;
VAL_ 1395 NSVAutoStopEnableSts 0 "Disable" 1 "Enable" ;
VAL_ 1395 NSVAutoStopStaySts 0 "RecrankEngine" 1 "RemainStop" ;
VAL_ 1395 VehicleLifterInfoForDisplay 0 "None" 1 "Moving_Up" 2 "Moving_Down" 3 "Up" 4 "Down" 5 "Inhibited" 6 "Failure" 7 "Up_at_KeyOff" 8 "Not_used" 9 "Not_used" 10 "Not_used" 11 "Not_used" 12 "Not_used" 13 "Not_used" 14 "Not_used" 15 "Not_used" 16 "Not_used" 17 "Not_used" 18 "Not_used" 19 "Not_used" 20 "Not_used" 21 "Not_used" 22 "Not_used" 23 "Not_used" 24 "Not_used" 25 "Not_used" 26 "Not_used" 27 "Not_used" 28 "Not_used" 29 "Not_used" 30 "Not_used" 31 "Not_used" ;
VAL_ 1398 RWSInternalSts 0 "Init_Check" 1 "Ready_for_Drive" 2 "Drive" 3 "Diag" 4 "Emergency_2_Zero_Position" 5 "Error_Blocked" 6 "Shutdown" 7 "Not_used" 8 "Not_used" 9 "Not_used" 10 "Not_used" 11 "Not_used" 12 "Not_used" 13 "Not_used" 14 "Not_used" 15 "Not_used" 16 "Not_used" 17 "Not_used" 18 "Not_used" 19 "Not_used" 20 "Not_used" 21 "Not_used" 22 "Not_used" 23 "Not_used" 24 "Not_used" 25 "Not_used" 26 "Not_used" 27 "Not_used" 28 "Not_used" 29 "Not_used" 30 "Not_used" 31 "Not_used" ;
VAL_ 1398 WarningLamp 0 "None" 1 "Yellow_Lamp" 2 "Red_Lamp" 3 "Invalid" ;
VAL_ 1398 SnowChainModeLampSts 0 "Lamp_OFF" 1 "Lamp_ON" ;
VAL_ 1403 GenericFailSts_STATUS_C_NCS_V2 0 "No_functional_fail_is_present" 1 "At_least_one_funct_fail_pres" ;
VAL_ 1403 CurrentFailSts 0 "No_functional_fail_is_present" 1 "DTCStatus_present" ;
VAL_ 1403 EOL 0 "No_EOL_prog_At_FIAT" 1 "EOL_prog_At_FIAT" ;
VAL_ 1403 D_ES 0 "Error_Active_State" 1 "Error_Passive_Warning_State" 2 "Bus_Off_State" 3 "Not_used" ;
VAL_ 1403 NCSSetupSts 0 "Follow_Manettino_Sts" 1 "Position_1" 2 "Position_2" 3 "Position_3" 4 "Not_used" 5 "Not_used" 6 "Not_used" 7 "Status_already_selected" ;
VAL_ 1403 NCSSystemInfoForDisplay 0 "No_Info" 1 "Fault" 2 "Degraded" 3 "Not_Available" 4 "Critical_Fault" 5 "Not_Used" 6 "Not_Used" 7 "Not_Used" ;
VAL_ 1403 NCSSetupInfoForDisplay 0 "No_Visualization" 1 "position_1" 2 "position_2" 4 "position_3" 5 "Not_used" 6 "Not_used" 7 "Status_Already_Selected" ;
VAL_ 1408 FLS1RawValueValidData 0 "Valid" 1 "Not_valid" ;
VAL_ 1408 FLS2RawValueValidData 0 "Valid" 1 "Not_valid" ;
VAL_ 1408 FLS3RawValueValidData 0 "Valid" 1 "Not_valid" ;
